VERSION "HNPBNNNYNNNNNNNNNNNNNNNNNNNNNNNNYNYYYYYYYY>4>%%%/4>'%**4YYY///"

NS_ :

BS_:

BU_: TPM TCM SCCM RF_HUB PTS ORC IC HaLF ETM ESM ESC EPS ECM Diagnost DTCM DASM CBC AFLS ADCM

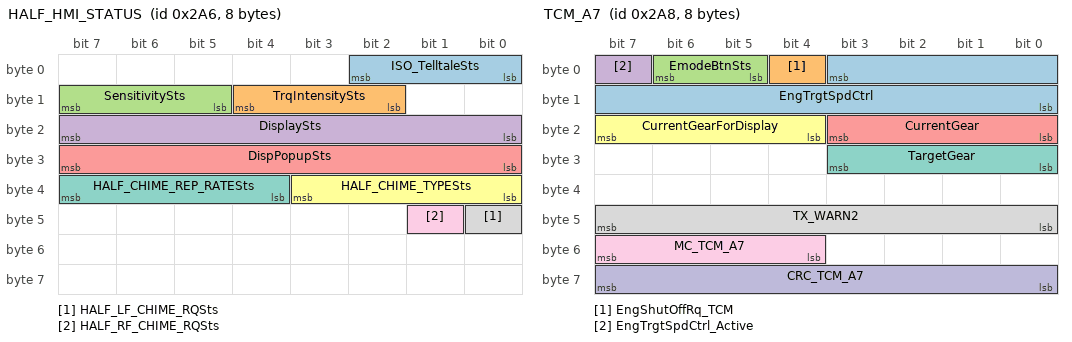
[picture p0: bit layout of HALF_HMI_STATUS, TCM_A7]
BO_ 678 HALF_HMI_STATUS: 8 HaLF
 SG_ ISO_TelltaleSts : 0|3@1+ (1,0) [0|0] ""  IC
 SG_ TrqIntensitySts : 10|3@1+ (1,0) [0|0] ""  IC
 SG_ SensitivitySts : 13|3@1+ (1,0) [0|0] ""  IC
 SG_ DisplaySts : 16|8@1+ (1,0) [0|0] ""  IC
 SG_ DispPopupSts : 24|8@1+ (1,0) [0|0] ""  IC
 SG_ HALF_CHIME_TYPESts : 32|4@1+ (1,0) [0|0] ""  CBC
 SG_ HALF_CHIME_REP_RATESts : 36|4@1+ (1,0) [0|15] ""  CBC
 SG_ HALF_LF_CHIME_RQSts : 40|1@1+ (1,0) [0|0] ""  CBC
 SG_ HALF_RF_CHIME_RQSts : 41|1@1+ (1,0) [0|0] ""  CBC

BO_ 680 TCM_A7: 8 ECM
 SG_ EngTrgtSpdCtrl : 3|12@0+ (2.5,0) [0|10235] "rpm"  ECM
 SG_ EngShutOffRq_TCM : 4|1@1+ (1,0) [0|0] ""  ECM,RF_HUB
 SG_ EmodeBtnSts : 5|2@1+ (1,0) [0|0] ""  ECM,CBC
 SG_ EngTrgtSpdCtrl_Active : 7|1@1+ (1,0) [0|0] ""  ECM
 SG_ CurrentGear : 16|4@1+ (1,0) [0|0] ""  ECM,DASM
 SG_ CurrentGearForDisplay : 20|4@1+ (1,0) [0|0] ""  ECM,IC
 SG_ TargetGear : 24|4@1+ (1,0) [0|0] ""  ECM,DASM
 SG_ TX_WARN2 : 40|8@1+ (1,0) [0|0] ""  ECM,IC
 SG_ MC_TCM_A7 : 52|4@1+ (1,0) [0|15] ""  ECM,DASM
 SG_ CRC_TCM_A7 : 56|8@1+ (1,0) [0|0] ""  ECM,DASM

BO_ 683 CBC_PT9: 8 CBC
 SG_ Pitch_Angle : 0|8@1+ (1,-90) [-90|90] "°"  IC
 SG_ Roll_Angle : 8|8@1+ (1,-90) [-90|90] "°"  IC

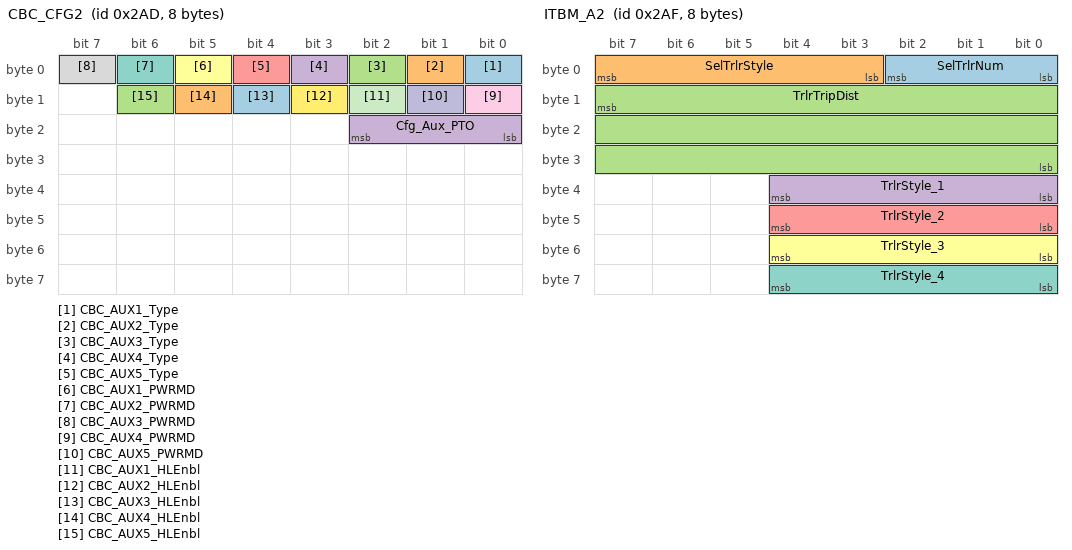
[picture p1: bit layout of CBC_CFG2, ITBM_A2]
BO_ 685 CBC_CFG2: 8 CBC
 SG_ CBC_AUX1_Type : 0|1@1+ (1,0) [0|0] ""  IC
 SG_ CBC_AUX2_Type : 1|1@1+ (1,0) [0|0] ""  IC
 SG_ CBC_AUX3_Type : 2|1@1+ (1,0) [0|0] ""  IC
 SG_ CBC_AUX4_Type : 3|1@1+ (1,0) [0|0] ""  IC
 SG_ CBC_AUX5_Type : 4|1@1+ (1,0) [0|0] ""  IC
 SG_ CBC_AUX1_PWRMD : 5|1@1+ (1,0) [0|0] ""  IC
 SG_ CBC_AUX2_PWRMD : 6|1@1+ (1,0) [0|0] ""  IC
 SG_ CBC_AUX3_PWRMD : 7|1@1+ (1,0) [0|0] ""  IC
 SG_ CBC_AUX4_PWRMD : 8|1@1+ (1,0) [0|0] ""  IC
 SG_ CBC_AUX5_PWRMD : 9|1@1+ (1,0) [0|0] ""  IC
 SG_ CBC_AUX1_HLEnbl : 10|1@1+ (1,0) [0|0] ""  IC
 SG_ CBC_AUX2_HLEnbl : 11|1@1+ (1,0) [0|0] ""  IC
 SG_ CBC_AUX3_HLEnbl : 12|1@1+ (1,0) [0|0] ""  IC
 SG_ CBC_AUX4_HLEnbl : 13|1@1+ (1,0) [0|0] ""  IC
 SG_ CBC_AUX5_HLEnbl : 14|1@1+ (1,0) [0|0] ""  IC
 SG_ Cfg_Aux_PTO : 16|3@1+ (1,0) [0|0] ""  IC

BO_ 687 ITBM_A2: 8 Vector__XXX
 SG_ SelTrlrNum : 0|3@1+ (1,0) [0|0] ""  IC,CBC
 SG_ SelTrlrStyle : 3|5@1+ (1,0) [0|0] ""  IC,CBC
 SG_ TrlrTripDist : 15|24@0+ (0.1,0) [0|1677720] "km"  IC,CBC
 SG_ TrlrStyle_1 : 32|5@1+ (1,0) [0|0] ""  IC,CBC
 SG_ TrlrStyle_2 : 40|5@1+ (1,0) [0|0] ""  IC,CBC
 SG_ TrlrStyle_3 : 48|5@1+ (1,0) [0|0] ""  IC,CBC
 SG_ TrlrStyle_4 : 56|5@1+ (1,0) [0|0] ""  IC,CBC

BO_ 688 EPPM_A1: 2 Vector__XXX
 SG_ EPPM_FAULT : 0|1@1+ (1,0) [0|0] ""  ORC,IC
 SG_ EPPM_Stat : 1|2@1+ (1,0) [0|0] ""  ORC

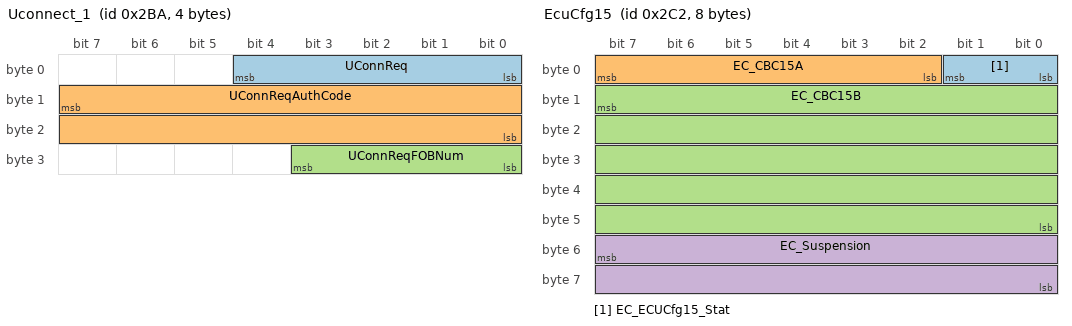
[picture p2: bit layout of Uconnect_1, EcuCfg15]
BO_ 698 Uconnect_1: 4 ETM
 SG_ UConnReq : 0|5@1+ (1,0) [0|0] ""  RF_HUB
 SG_ UConnReqAuthCode : 15|16@0+ (1,0) [0|0] ""  RF_HUB
 SG_ UConnReqFOBNum : 24|4@1+ (1,0) [0|0] ""  RF_HUB

BO_ 706 EcuCfg15: 8 CBC
 SG_ EC_ECUCfg15_Stat : 0|2@1+ (1,0) [0|0] ""  ADCM,RF_HUB
 SG_ EC_CBC15A : 2|6@1+ (1,0) [0|0] ""  RF_HUB
 SG_ EC_CBC15B : 15|40@0+ (1,0) [0|0] ""  RF_HUB
 SG_ EC_Suspension : 55|16@0+ (1,0) [0|0] ""  ADCM,RF_HUB

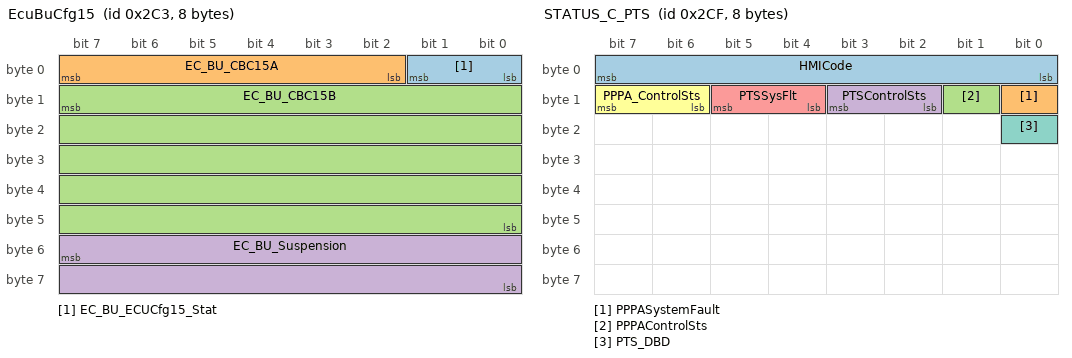
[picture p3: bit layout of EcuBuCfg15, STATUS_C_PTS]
BO_ 707 EcuBuCfg15: 8 RF_HUB
 SG_ EC_BU_ECUCfg15_Stat : 0|2@1+ (1,0) [0|0] ""  CBC
 SG_ EC_BU_CBC15A : 2|6@1+ (1,0) [0|0] ""  CBC
 SG_ EC_BU_CBC15B : 15|40@0+ (1,0) [0|0] ""  CBC
 SG_ EC_BU_Suspension : 55|16@0+ (1,0) [0|0] ""  CBC

BO_ 719 STATUS_C_PTS: 8 PTS
 SG_ HMICode : 0|8@1+ (1,0) [0|0] ""  IC
 SG_ PPPASystemFault : 8|1@1+ (1,0) [0|0] ""  IC
 SG_ PPPAControlSts : 9|1@1+ (1,0) [0|0] ""  IC
 SG_ PTSControlSts : 10|2@1+ (1,0) [0|0] ""  IC
 SG_ PTSSysFlt : 12|2@1+ (1,0) [0|0] ""  IC
 SG_ PPPA_ControlSts : 14|2@1+ (1,0) [0|0] ""  CBC
 SG_ PTS_DBD : 16|1@1+ (1,0) [0|0] ""  IC

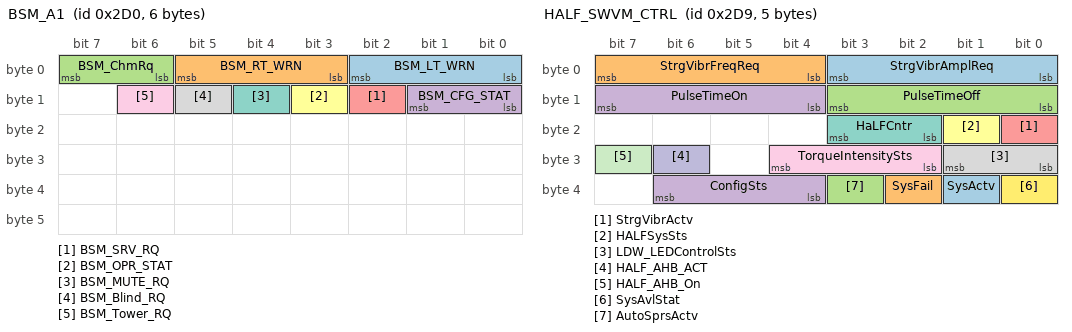
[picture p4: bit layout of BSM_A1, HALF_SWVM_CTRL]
BO_ 720 BSM_A1: 6 CBC
 SG_ BSM_LT_WRN : 0|3@1+ (1,0) [0|0] ""  IC
 SG_ BSM_RT_WRN : 3|3@1+ (1,0) [0|0] ""  IC
 SG_ BSM_ChmRq : 6|2@1+ (1,0) [0|0] ""  IC
 SG_ BSM_CFG_STAT : 8|2@1+ (1,0) [0|0] ""  IC
 SG_ BSM_SRV_RQ : 10|1@1+ (1,0) [0|0] ""  IC
 SG_ BSM_OPR_STAT : 11|1@1+ (1,0) [0|0] ""  IC
 SG_ BSM_MUTE_RQ : 12|1@1+ (1,0) [0|0] "" Vector__XXX
 SG_ BSM_Blind_RQ : 13|1@1+ (1,0) [0|0] ""  IC
 SG_ BSM_Tower_RQ : 14|1@1+ (1,0) [0|0] ""  IC

BO_ 729 HALF_SWVM_CTRL: 5 HaLF
 SG_ StrgVibrAmplReq : 0|4@1+ (0.25,0) [0|3.75] "mm"  SCCM
 SG_ StrgVibrFreqReq : 4|4@1+ (1,0) [0|15] "Hz"  SCCM
 SG_ PulseTimeOff : 8|4@1+ (0.25,0) [0|3.75] "ms"  SCCM
 SG_ PulseTimeOn : 12|4@1+ (0.25,0) [0|3.75] "ms"  SCCM
 SG_ StrgVibrActv : 16|1@1+ (1,0) [0|0] ""  SCCM
 SG_ HALFSysSts : 17|1@1+ (1,0) [0|0] ""  SCCM
 SG_ HaLFCntr : 18|2@1+ (1,0) [0|3] "decimal"  SCCM
 SG_ LDW_LEDControlSts : 24|2@1+ (1,0) [0|0] ""  CBC
 SG_ TorqueIntensitySts : 26|3@1+ (1,0) [0|0] ""  CBC
 SG_ HALF_AHB_ACT : 30|1@1+ (1,0) [0|0] ""  IC,CBC
 SG_ HALF_AHB_On : 31|1@1+ (1,0) [0|0] ""  CBC
 SG_ SysAvlStat : 32|1@1+ (1,0) [0|0] ""  IC
 SG_ SysActv : 33|1@1+ (1,0) [0|0] ""  IC
 SG_ SysFail : 34|1@1+ (1,0) [0|0] ""  IC
 SG_ AutoSprsActv : 35|1@1+ (1,0) [0|0] ""  IC
 SG_ ConfigSts : 36|3@1+ (1,0) [0|0] ""  IC,CBC

BO_ 734 RFHUB_KEY_DATA: 7 RF_HUB
 SG_ RFHM_TXFR_SEL : 0|3@1+ (1,0) [0|0] ""  CBC
 SG_ RFHM_KEY_DATA : 15|48@0+ (1,0) [0|0] ""  CBC

BO_ 735 CBC_KEY_DATA: 7 CBC
 SG_ CBC_TXFR_SEL : 0|3@1+ (1,0) [0|0] ""  RF_HUB
 SG_ CBC_KEY_DATA : 15|48@0+ (1,0) [0|0] ""  RF_HUB

BO_ 736 ESP_B1: 8 ESC
 SG_ LT_DIST : 7|16@0+ (4,0) [0|262136] "cm"  ECM,PTS,IC,CBC
 SG_ RT_DIST : 23|16@0+ (4,0) [0|262136] "cm"  ECM,PTS,IC,CBC
 SG_ YRS_DataRq : 32|1@1+ (1,0) [0|0] "" Vector__XXX
 SG_ SPCR_Warn_V2 : 33|3@1+ (1,0) [0|0] ""  DASM,IC
 SG_ HDC_SUPP : 40|1@1+ (1,0) [0|0] ""  CBC
 SG_ HDC_EN : 41|1@1+ (1,0) [0|0] ""  CBC
 SG_ TSC_SUPP : 42|1@1+ (1,0) [0|0] ""  CBC
 SG_ TSC_EN : 43|1@1+ (1,0) [0|0] ""  CBC
 SG_ ESP_PD_SUPP : 44|1@1+ (1,0) [0|0] ""  CBC
 SG_ ESP_PD_EN : 45|1@1+ (1,0) [0|0] ""  CBC
 SG_ HSA_SUPP : 46|1@1+ (1,0) [0|0] ""  IC,CBC
 SG_ HSA_EN : 47|1@1+ (1,0) [0|0] ""  IC,CBC
 SG_ ESP_DSBL : 51|1@1+ (1,0) [0|0] ""  ETM,ORC,DTCM,DASM,IC,CBC
 SG_ HILL_DES_STAT : 52|2@1+ (1,0) [0|0] ""  TCM,ECM,DASM,IC,CBC
 SG_ ESP_Off_IndLmp_On_Rq : 54|1@1+ (1,0) [0|0] ""  ETM,ORC,DTCM,IC,CBC
 SG_ ESP_TRK_MD : 55|1@1+ (1,0) [0|0] ""  ORC,IC,CBC
 SG_ ESC_CtrlLmp_Info : 56|2@1+ (1,0) [0|0] ""  ETM,ORC,DTCM,DASM,PTS,IC
 SG_ ABS_IndLmp_On_Rq : 58|2@1+ (1,0) [0|0] ""  ETM,ECM,IC
 SG_ BrkIndLmp_On_Rq_ESC : 60|2@1+ (1,0) [0|0] ""  ETM,IC
 SG_ SelSpdLmp : 62|2@1+ (1,0) [0|0] ""  IC,CBC

BO_ 737 ESP_B2: 8 ESC
 SG_ VehPerfAccel_X : 1|10@0+ (0.08,-40.88) [-40.88|40.88] "m/s²"  IC,CBC
 SG_ ESC_LnchMd : 3|2@1+ (1,0) [0|0] ""  ORC,ECM,IC,CBC
 SG_ ESC_LnchMdAbrt : 5|1@1+ (1,0) [0|0] ""  ECM,IC
 SG_ VehPerfAccel_Y : 17|10@0+ (0.08,-40.88) [-40.88|40.88] "m/s²"  IC,CBC
 SG_ LaunchRPMsetting_ESC : 19|5@1+ (250,1000) [1000|7000] "rpm"  CBC
 SG_ ESC_LnchMdCnd1 : 32|1@1+ (1,0) [0|0] ""  ECM,IC
 SG_ ESC_LnchMdCnd2 : 33|1@1+ (1,0) [0|0] ""  ECM,IC
 SG_ ESC_LnchMdCnd3 : 34|1@1+ (1,0) [0|0] ""  ECM,IC
 SG_ ESC_LnchMdCnd4 : 35|1@1+ (1,0) [0|0] ""  ECM,IC
 SG_ ESC_LnchMdCnd5 : 36|1@1+ (1,0) [0|0] ""  ECM,IC
 SG_ ESC_LnchMdCnd6 : 37|1@1+ (1,0) [0|0] ""  ECM,IC
 SG_ BrkWearInd : 38|2@1+ (1,0) [0|0] ""  IC
 SG_ ESC_sftbtn_launch_sel : 40|1@1+ (1,0) [0|0] ""  CBC
 SG_ ICS_ESC_OFF_LED_hrdbtn_cnrtl : 41|2@1+ (1,0) [0|0] ""  CBC
 SG_ ESC_OFF_Hrd_Sft_Button_sts : 43|3@1+ (1,0) [0|0] ""  CBC
 SG_ ESC_LnchAbrtSts : 46|2@1+ (1,0) [0|0] ""  ECM,IC
 SG_ ICS_Launch_HrdBtn_LED_cnrtl : 51|2@1+ (1,0) [0|0] ""  CBC
 SG_ ESC_LnchMode : 53|3@1+ (1,0) [0|0] ""  ECM

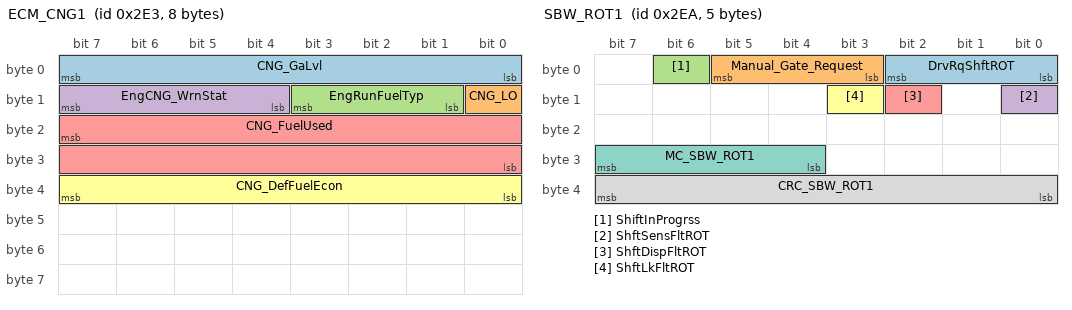
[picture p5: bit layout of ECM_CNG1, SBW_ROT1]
BO_ 739 ECM_CNG1: 8 ECM
 SG_ CNG_GaLvl : 0|8@1+ (1,0) [0|100] "%"  IC
 SG_ CNG_LO : 8|1@1+ (1,0) [0|0] ""  IC
 SG_ EngRunFuelTyp : 9|3@1+ (1,0) [0|0] ""  IC,CBC
 SG_ EngCNG_WrnStat : 12|4@1+ (1,0) [0|0] ""  IC
 SG_ CNG_FuelUsed : 23|16@0+ (0.21668,0) [0|14200] "µl/100ms"  IC
 SG_ CNG_DefFuelEcon : 32|8@1+ (0.2,0) [0|50] "kmpl"  IC

BO_ 746 SBW_ROT1: 5 ESM
 SG_ DrvRqShftROT : 0|3@1+ (1,0) [0|0] ""  TCM,RF_HUB
 SG_ Manual_Gate_Request : 3|3@1+ (1,0) [0|0] ""  TCM
 SG_ ShiftInProgrss : 6|1@1+ (1,0) [0|0] ""  TCM,IC
 SG_ ShftSensFltROT : 8|1@1+ (1,0) [0|0] ""  TCM
 SG_ ShftDispFltROT : 10|1@1+ (1,0) [0|0] ""  TCM
 SG_ ShftLkFltROT : 11|1@1+ (1,0) [0|0] ""  TCM
 SG_ MC_SBW_ROT1 : 28|4@1+ (1,0) [0|15] ""  TCM
 SG_ CRC_SBW_ROT1 : 32|8@1+ (1,0) [0|0] ""  TCM

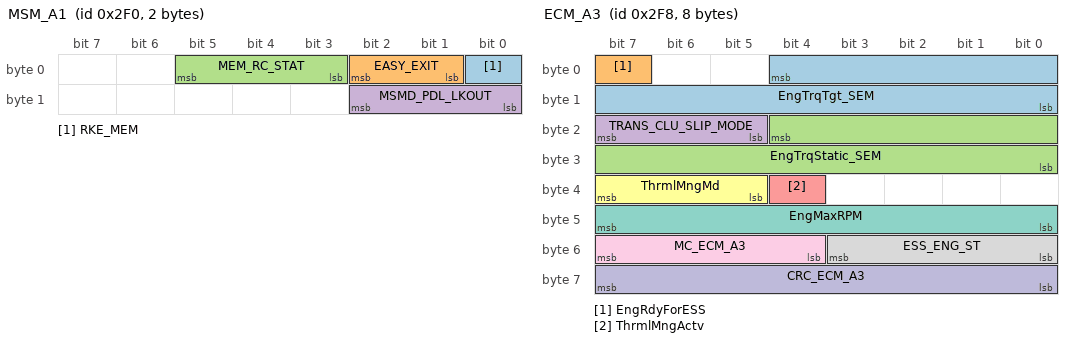
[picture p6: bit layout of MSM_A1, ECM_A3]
BO_ 752 MSM_A1: 2 CBC
 SG_ RKE_MEM : 0|1@1+ (1,0) [0|0] ""  IC
 SG_ EASY_EXIT : 1|2@1+ (1,0) [0|0] ""  IC
 SG_ MEM_RC_STAT : 3|3@1+ (1,0) [0|0] ""  IC
 SG_ MSMD_PDL_LKOUT : 8|3@1+ (1,0) [0|0] ""  IC

BO_ 760 ECM_A3: 8 ECM
 SG_ EngTrqTgt_SEM : 4|13@0+ (0.25,-500) [-500|1547.5] "Nm"  TCM
 SG_ EngRdyForESS : 7|1@1+ (1,0) [0|0] ""  TCM
 SG_ EngTrqStatic_SEM : 20|13@0+ (0.25,-500) [-500|1547.5] "Nm"  TCM
 SG_ TRANS_CLU_SLIP_MODE : 21|3@1+ (1,0) [0|0] ""  TCM
 SG_ ThrmlMngActv : 36|1@1+ (1,0) [0|0] ""  TCM
 SG_ ThrmlMngMd : 37|3@1+ (1,0) [0|0] ""  CBC
 SG_ EngMaxRPM : 40|8@1+ (50,0) [0|12700] "rpm"  TCM
 SG_ ESS_ENG_ST : 48|4@1+ (1,0) [0|0] ""  ORC,DTCM,TCM,ESC,EPS,AFLS,CBC
 SG_ MC_ECM_A3 : 52|4@1+ (1,0) [0|15] ""  TCM,CBC
 SG_ CRC_ECM_A3 : 56|8@1+ (1,0) [0|0] ""  TCM

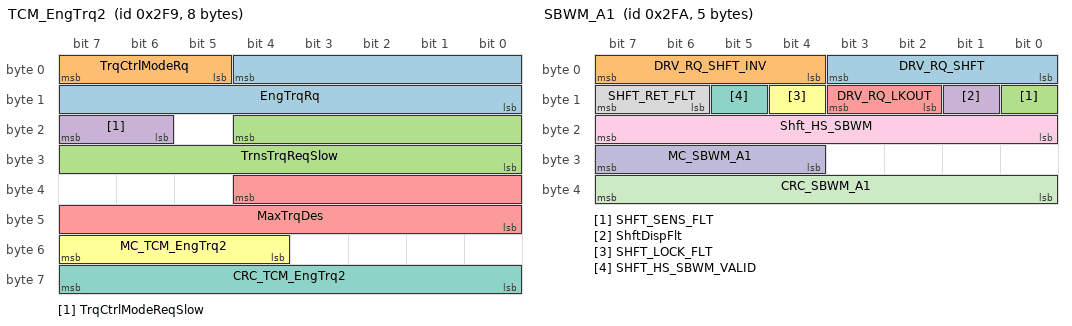
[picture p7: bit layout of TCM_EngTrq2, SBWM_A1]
BO_ 761 TCM_EngTrq2: 8 TCM
 SG_ EngTrqRq : 4|13@0+ (0.25,-500) [-500|1547.5] "Nm"  ECM
 SG_ TrqCtrlModeRq : 5|3@1+ (1,0) [0|0] ""  ECM
 SG_ TrnsTrqReqSlow : 20|13@0+ (0.25,-500) [-500|1547.5] "Nm"  ECM
 SG_ TrqCtrlModeReqSlow : 22|2@1+ (1,0) [0|0] ""  ECM
 SG_ MaxTrqDes : 36|13@0+ (0.25,-500) [-500|1547.5] "Nm"  ECM
 SG_ MC_TCM_EngTrq2 : 52|4@1+ (1,0) [0|15] ""  ECM
 SG_ CRC_TCM_EngTrq2 : 56|8@1+ (1,0) [0|0] ""  ECM

BO_ 762 SBWM_A1: 5 Vector__XXX
 SG_ DRV_RQ_SHFT : 0|4@1+ (1,0) [0|0] ""  TCM
 SG_ DRV_RQ_SHFT_INV : 4|4@1+ (1,0) [0|0] ""  TCM
 SG_ SHFT_SENS_FLT : 8|1@1+ (1,0) [0|0] ""  TCM
 SG_ ShftDispFlt : 9|1@1+ (1,0) [0|0] ""  TCM
 SG_ DRV_RQ_LKOUT : 10|2@1+ (1,0) [0|0] ""  TCM
 SG_ SHFT_LOCK_FLT : 12|1@1+ (1,0) [0|0] ""  TCM
 SG_ SHFT_HS_SBWM_VALID : 13|1@1+ (1,0) [0|0] ""  TCM
 SG_ SHFT_RET_FLT : 14|2@1+ (1,0) [0|0] ""  TCM
 SG_ Shft_HS_SBWM : 16|8@1+ (1,0) [0|0] ""  TCM
 SG_ MC_SBWM_A1 : 28|4@1+ (1,0) [0|15] ""  TCM
 SG_ CRC_SBWM_A1 : 32|8@1+ (1,0) [0|0] ""  TCM

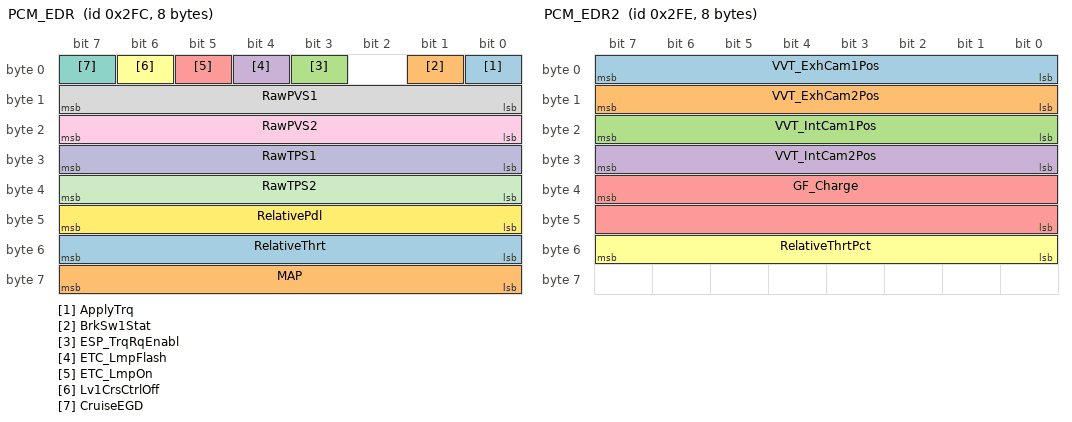
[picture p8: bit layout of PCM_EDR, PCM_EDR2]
BO_ 764 PCM_EDR: 8 ECM
 SG_ ApplyTrq : 0|1@1+ (1,0) [0|0] ""  ORC
 SG_ BrkSw1Stat : 1|1@1+ (1,0) [0|0] "" Vector__XXX
 SG_ ESP_TrqRqEnabl : 3|1@1+ (1,0) [0|0] ""  ORC
 SG_ ETC_LmpFlash : 4|1@1+ (1,0) [0|0] ""  ORC
 SG_ ETC_LmpOn : 5|1@1+ (1,0) [0|0] ""  ORC
 SG_ Lv1CrsCtrlOff : 6|1@1+ (1,0) [0|0] ""  ORC
 SG_ CruiseEGD : 7|1@1+ (1,0) [0|0] ""  ORC
 SG_ RawPVS1 : 8|8@1+ (0.019607843,0) [0|4.98] "Volts"  ORC
 SG_ RawPVS2 : 16|8@1+ (0.019607843,0) [0|4.98] "Volts"  ORC
 SG_ RawTPS1 : 24|8@1+ (0.019607843,0) [0|4.98] "Volts"  ORC
 SG_ RawTPS2 : 32|8@1+ (0.019607843,0) [0|4.98] "Volts"  ORC
 SG_ RelativePdl : 40|8@1+ (0.019607843,0) [0|4.98] "Volts"  ORC
 SG_ RelativeThrt : 48|8@1+ (0.019607843,0) [0|4.98] "Volts"  ORC
 SG_ MAP : 56|8@1+ (0.8,0) [0|203.2] "kPa"  ORC,ESC

BO_ 766 PCM_EDR2: 8 ECM
 SG_ VVT_ExhCam1Pos : 0|8@1+ (1,0) [1|254] "Degrees"  ORC
 SG_ VVT_ExhCam2Pos : 8|8@1+ (1,0) [1|254] "Degrees"  ORC
 SG_ VVT_IntCam1Pos : 16|8@1+ (1,0) [1|254] "Degrees"  ORC
 SG_ VVT_IntCam2Pos : 24|8@1+ (1,0) [1|254] "Degrees"  ORC
 SG_ GF_Charge : 39|16@0+ (0.2,0) [0|13106.8] "mg/cycle/cyl"  ORC
 SG_ RelativeThrtPct : 48|8@1+ (0.4,0) [0|100] "%"  ORC

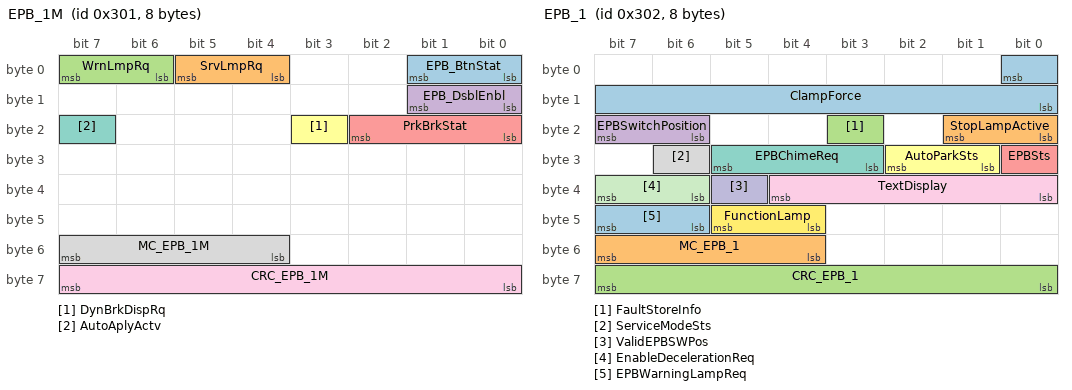
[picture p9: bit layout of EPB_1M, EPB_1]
BO_ 769 EPB_1M: 8 Vector__XXX
 SG_ EPB_BtnStat : 0|2@1+ (1,0) [0|0] ""  ECM,ESC
 SG_ SrvLmpRq : 4|2@1+ (1,0) [0|0] ""  CBC
 SG_ WrnLmpRq : 6|2@1+ (1,0) [0|0] ""  ORC,CBC
 SG_ EPB_DsblEnbl : 8|2@1+ (1,0) [0|0] ""  TCM,RF_HUB
 SG_ PrkBrkStat : 16|3@1+ (1,0) [0|0] ""  ORC,TCM,ECM,ESC,CBC,RF_HUB
 SG_ DynBrkDispRq : 19|1@1+ (1,0) [0|0] ""  TCM,ESC,CBC
 SG_ AutoAplyActv : 23|1@1+ (1,0) [0|0] ""  CBC
 SG_ MC_EPB_1M : 52|4@1+ (1,0) [0|15] ""  ESC
 SG_ CRC_EPB_1M : 56|8@1+ (1,0) [0|0] ""  ESC

BO_ 770 EPB_1: 8 Vector__XXX
 SG_ ClampForce : 0|9@0+ (0.1,0) [0|51.1] "Kn"  ORC,DASM,ESC,EPS,IC,CBC
 SG_ StopLampActive : 16|2@1+ (1,0) [0|0] ""  DASM,ESC,EPS,IC,CBC
 SG_ FaultStoreInfo : 19|1@1+ (1,0) [0|0] ""  DASM,ESC,EPS,IC,CBC
 SG_ EPBSwitchPosition : 22|2@1+ (1,0) [0|0] ""  ORC,DASM,ESC,EPS,IC,CBC
 SG_ EPBSts : 24|1@1+ (1,0) [0|0] ""  ORC,DASM,ESC,EPS,IC,CBC
 SG_ AutoParkSts : 25|2@1+ (1,0) [0|0] ""  DASM,ESC,EPS,IC,CBC
 SG_ EPBChimeReq : 27|3@1+ (1,0) [0|0] ""  DASM,ESC,EPS,IC,CBC
 SG_ ServiceModeSts : 30|1@1+ (1,0) [0|0] ""  DASM,ESC,EPS,IC,CBC
 SG_ TextDisplay : 32|5@1+ (1,0) [0|0] ""  DASM,ESC,EPS,IC,CBC
 SG_ ValidEPBSWPos : 37|1@1+ (1,0) [0|0] ""  DASM,ESC,EPS,IC,CBC
 SG_ EnableDecelerationReq : 38|2@1+ (1,0) [0|0] ""  DASM,ESC,EPS,IC,CBC
 SG_ FunctionLamp : 44|2@1+ (1,0) [0|0] ""  DASM,ESC,EPS,IC,CBC
 SG_ EPBWarningLampReq : 46|2@1+ (1,0) [0|0] ""  ORC,DASM,ESC,EPS,IC,CBC
 SG_ MC_EPB_1 : 52|4@1+ (1,0) [0|15] ""  DASM,ESC,EPS,IC,CBC
 SG_ CRC_EPB_1 : 56|8@1+ (1,0) [0|0] ""  DASM,ESC,EPS,IC,CBC

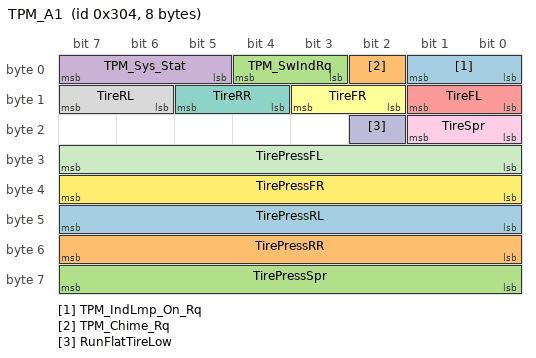
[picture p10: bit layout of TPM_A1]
BO_ 772 TPM_A1: 8 TPM
 SG_ TPM_IndLmp_On_Rq : 0|2@1+ (1,0) [0|0] ""  ETM,ORC,IC
 SG_ TPM_Chime_Rq : 2|1@1+ (1,0) [0|0] ""  ORC,IC
 SG_ TPM_SwIndRq : 3|2@1+ (1,0) [0|0] ""  ORC,IC,CBC
 SG_ TPM_Sys_Stat : 5|3@1+ (1,0) [0|0] ""  ORC,IC
 SG_ TireFL : 8|2@1+ (1,0) [0|0] ""  ETM,ORC,IC
 SG_ TireFR : 10|2@1+ (1,0) [0|0] ""  ETM,ORC,IC
 SG_ TireRR : 12|2@1+ (1,0) [0|0] ""  ETM,ORC,IC
 SG_ TireRL : 14|2@1+ (1,0) [0|0] ""  ETM,ORC,IC
 SG_ TireSpr : 16|2@1+ (1,0) [0|0] ""  ORC,IC
 SG_ RunFlatTireLow : 18|1@1+ (1,0) [0|0] ""  ORC,IC
 SG_ TirePressFL : 24|8@1+ (1,0) [0|126] "psi"  ETM,ORC,IC
 SG_ TirePressFR : 32|8@1+ (1,0) [0|126] "psi"  ETM,ORC,IC
 SG_ TirePressRL : 40|8@1+ (1,0) [0|126] "psi"  ETM,ORC,IC
 SG_ TirePressRR : 48|8@1+ (1,0) [0|126] "psi"  ETM,ORC,IC
 SG_ TirePressSpr : 56|8@1+ (1,0) [0|126] "psi"  ORC,IC

CM_ SG_ 678 ISO_TelltaleSts "LDW telltale status in cluster";
CM_ SG_ 678 TrqIntensitySts "LDW torque intesity level for display in cluster";
CM_ SG_ 678 SensitivitySts "LDW sensitivity level for display in cluster";
CM_ SG_ 678 DisplaySts "LDW display status in cluster";
CM_ SG_ 678 DispPopupSts "LDW message status in cluster";
CM_ SG_ 678 HALF_CHIME_TYPESts "LDW chime type";
CM_ SG_ 678 HALF_CHIME_REP_RATESts "LDW chime repetition rate";
CM_ SG_ 678 HALF_LF_CHIME_RQSts "LDW chime request for left side; true = [1]";
CM_ SG_ 678 HALF_RF_CHIME_RQSts "LDW chime request for right side; true = [1]";
CM_ SG_ 680 EngTrgtSpdCtrl "Engine target speed control";
CM_ SG_ 680 EngShutOffRq_TCM "TCM request engine shut off";
CM_ SG_ 680 EmodeBtnSts "Emode button LED status";
CM_ SG_ 680 EngTrgtSpdCtrl_Active "Engine target speed control active";
CM_ SG_ 680 CurrentGear "Current Gear";
CM_ SG_ 680 CurrentGearForDisplay "Current Gear for display";
CM_ SG_ 680 TargetGear "Target Gear - protected";
CM_ SG_ 680 TX_WARN2 "Transmission warning #2";
CM_ SG_ 680 MC_TCM_A7 "Message counter";
CM_ SG_ 680 CRC_TCM_A7 "CRC-checksum byte 1 to 7 according to SAE J1850";
CM_ SG_ 683 Pitch_Angle "Pitch angle; Disable = [FE]";
CM_ SG_ 683 Roll_Angle "Roll angle";
CM_ SG_ 685 CBC_AUX1_Type "Aux switch 1 behavior; Latching = [0], Momentary = [1]";
CM_ SG_ 685 CBC_AUX2_Type "Aux switch 2 behavior; Latching = [0], Momentary = [1]";
CM_ SG_ 685 CBC_AUX3_Type "Aux switch 3 behavior; Latching = [0], Momentary = [1]";
CM_ SG_ 685 CBC_AUX4_Type "Aux switch 4 behavior; Latching = [0], Momentary = [1]";
CM_ SG_ 685 CBC_AUX5_Type "Aux switch 5 behavior; Latching = [0], Momentary = [1]";
CM_ SG_ 685 CBC_AUX1_PWRMD "Aux switch 1 power mode; ignition = [0], battery = [1]";
CM_ SG_ 685 CBC_AUX2_PWRMD "Aux switch 2 power mode; ignition = [0], battery = [1]";
CM_ SG_ 685 CBC_AUX3_PWRMD "Aux switch 3 power mode; ignition = [0], battery = [1]";
CM_ SG_ 685 CBC_AUX4_PWRMD "Aux switch 4 power mode; ignition = [0], battery = [1]";
CM_ SG_ 685 CBC_AUX5_PWRMD "Aux switch 5 power mode; ignition = [0], battery = [1]";
CM_ SG_ 685 CBC_AUX1_HLEnbl "Aux switch 1 enable holding last state; enabled = [1]";
CM_ SG_ 685 CBC_AUX2_HLEnbl "Aux switch 2 enable holding last state; enabled = [1]";
CM_ SG_ 685 CBC_AUX3_HLEnbl "Aux switch 3 enable holding last state; enabled = [1]";
CM_ SG_ 685 CBC_AUX4_HLEnbl "Aux switch 4 enable holding last state; enabled = [1]";
CM_ SG_ 685 CBC_AUX5_HLEnbl "Aux switch 5 enable holding last state; enabled = [1]";
CM_ SG_ 685 Cfg_Aux_PTO "AUX Switches Configuration";
CM_ SG_ 687 SelTrlrNum "Selected trailer number";
CM_ SG_ 687 SelTrlrStyle "Selected trailer style";
CM_ SG_ 687 TrlrTripDist "Trip distance of the curent Trailer";
CM_ SG_ 687 TrlrStyle_1 "Trailer 1 style";
CM_ SG_ 687 TrlrStyle_2 "Trailer 2 style";
CM_ SG_ 687 TrlrStyle_3 "Trailer 3 style";
CM_ SG_ 687 TrlrStyle_4 "Trailer 4 style";
CM_ SG_ 688 EPPM_FAULT "Pedestrian protection module fault; True = [1]";
CM_ SG_ 688 EPPM_Stat "Pedestrian protection module status";
CM_ SG_ 698 UConnReq "Basic Uconnect request";
CM_ SG_ 698 UConnReqAuthCode "Authorization for requests";
CM_ SG_ 698 UConnReqFOBNum "FOB number making the request";
CM_ SG_ 706 EC_ECUCfg15_Stat "ECU Configuration messages status 15";
CM_ SG_ 706 EC_CBC15A "CBC ecu configuration 15A";
CM_ SG_ 706 EC_CBC15B "CBC ecu configuration 15B";
CM_ SG_ 706 EC_Suspension "Suspension ecu configuration";
CM_ SG_ 707 EC_BU_ECUCfg15_Stat "Backup for ECU Configuration messages status 15";
CM_ SG_ 707 EC_BU_CBC15A "Backup for CBC ecu configuration 15A";
CM_ SG_ 707 EC_BU_CBC15B "Backup for CBC ecu configuration 15B";
CM_ SG_ 707 EC_BU_Suspension "Backup for Suspension ecu configuration";
CM_ SG_ 719 HMICode "HMI codes to be displayed";
CM_ SG_ 719 PPPASystemFault "Indicates the fail status of PPPA; true = [1]";
CM_ SG_ 719 PPPAControlSts "Indicates the active state of PPPA; active = [1]";
CM_ SG_ 719 PTSControlSts "Indicates the active state of the PTS";
CM_ SG_ 719 PTSSysFlt "Indicates the fail status of the PTS";
CM_ SG_ 719 PPPA_ControlSts "Parallel & perpendicular park assist switch status";
CM_ SG_ 719 PTS_DBD "Park assist system disabled; System_Disabled = [1]";
CM_ SG_ 720 BSM_LT_WRN "Blind spot detection left side warning";
CM_ SG_ 720 BSM_RT_WRN "Blind spot detection Right side warning";
CM_ SG_ 720 BSM_ChmRq "Blind spot chime request";
CM_ SG_ 720 BSM_CFG_STAT "BSM configuration status";
CM_ SG_ 720 BSM_SRV_RQ "BSM service warning request; 1= service request";
CM_ SG_ 720 BSM_OPR_STAT "BSM operation status; 1= operational failure";
CM_ SG_ 720 BSM_MUTE_RQ "Audio system mute request from BSM";
CM_ SG_ 720 BSM_Blind_RQ "Sensor blinded request from BSM; 1= sensor blocked request";
CM_ SG_ 720 BSM_Tower_RQ "BSM unavailable in the astronomy tower zone; 1= tower zone request";
CM_ SG_ 729 StrgVibrAmplReq "Steering vibration amplitude request";
CM_ SG_ 729 StrgVibrFreqReq "Steering vibration frequency request";
CM_ SG_ 729 PulseTimeOff "Pulse time off";
CM_ SG_ 729 PulseTimeOn "Pulse time on";
CM_ SG_ 729 StrgVibrActv "Steering vibration active; true = [1]";
CM_ SG_ 729 HALFSysSts "Half system status; fault = [1]";
CM_ SG_ 729 HaLFCntr "HaLF message counter";
CM_ SG_ 729 LDW_LEDControlSts "LDW switch LED status";
CM_ SG_ 729 TorqueIntensitySts "LDW Torque Intesity Level";
CM_ SG_ 729 HALF_AHB_ACT "Auto high beam is active (indicates that all enabling conditions are met)";
CM_ SG_ 729 HALF_AHB_On "Auto high beam on request from the HALF ECU";
CM_ SG_ 729 SysAvlStat "System availability status; available = [1]";
CM_ SG_ 729 SysActv "System active";
CM_ SG_ 729 SysFail "System fault";
CM_ SG_ 729 AutoSprsActv "Automatic suppression active";
CM_ SG_ 729 ConfigSts "LDW sensitivity level";
CM_ SG_ 734 RFHM_TXFR_SEL "RFHM transfer select (defines the key data)";
CM_ SG_ 734 RFHM_KEY_DATA "RFHM key data";
CM_ SG_ 735 CBC_TXFR_SEL "CBC transfer select (defines the key data)";
CM_ SG_ 735 CBC_KEY_DATA "CBC key data";
CM_ SG_ 736 LT_DIST "Distance Traveled by Left Wheel";
CM_ SG_ 736 RT_DIST "Distance Traveled by Right Wheel";
CM_ SG_ 736 YRS_DataRq "Request from ESC for YRS information";
CM_ SG_ 736 SPCR_Warn_V2 "Stop coordinator warning if driver exits vehicle";
CM_ SG_ 736 HDC_SUPP "Hill Descent Control supported (1=supported)";
CM_ SG_ 736 HDC_EN "Hill Descent Control enabled (1=enabled)";
CM_ SG_ 736 TSC_SUPP "Trailer Sway Control supported (1=supported)";
CM_ SG_ 736 TSC_EN "Trailer Sway Control enabled (1=enabled)";
CM_ SG_ 736 ESP_PD_SUPP "ESP Permanent Disable supported (1=supported)";
CM_ SG_ 736 ESP_PD_EN "ESP Permanent Disable enabled (1=enabled)";
CM_ SG_ 736 HSA_SUPP "Hill Start Assist supported (1=supported)";
CM_ SG_ 736 HSA_EN "Hill Start Assist enabled (1=enabled)";
CM_ SG_ 736 ESP_DSBL "ESP feature is completely disabled = [1]";
CM_ SG_ 736 HILL_DES_STAT "Hill descent feature status";
CM_ SG_ 736 ESP_Off_IndLmp_On_Rq "ESP-OFF indication lamp on request";
CM_ SG_ 736 ESP_TRK_MD "ESP Track Mode indication";
CM_ SG_ 736 ESC_CtrlLmp_Info "ESC control lamp information";
CM_ SG_ 736 ABS_IndLmp_On_Rq "ABS indication lamp on request";
CM_ SG_ 736 BrkIndLmp_On_Rq_ESC "Brake indication lamp (red) on request";
CM_ SG_ 736 SelSpdLmp "Select speed lamp status";
CM_ SG_ 737 VehPerfAccel_X "Vehicle longitudinal acceleration (+ means forward)";
CM_ SG_ 737 ESC_LnchMd "ESC launch mode";
CM_ SG_ 737 ESC_LnchMdAbrt "Indication of aborted Launch (1=aborted)";
CM_ SG_ 737 VehPerfAccel_Y "Vehicle lateral acceleration (+ means left, specific to center of gravity)";
CM_ SG_ 737 LaunchRPMsetting_ESC "Launch RPM setting";
CM_ SG_ 737 ESC_LnchMdCnd1 "Vehicle stopped for Launch (1=stopped for launch)";
CM_ SG_ 737 ESC_LnchMdCnd2 "Vehicle on level ground for Launch (1=level for launch)";
CM_ SG_ 737 ESC_LnchMdCnd3 "Steering wheel straight for Launch (1=straight for launch)";
CM_ SG_ 737 ESC_LnchMdCnd4 "Accelerator depressed for Launch (1=accelerator depressed for launch)";
CM_ SG_ 737 ESC_LnchMdCnd5 "Vehicle not in Reverse (1=not in reverse for launch)";
CM_ SG_ 737 ESC_LnchMdCnd6 "Engine Running (1=running)";
CM_ SG_ 737 BrkWearInd "Brake pad wear indication";
CM_ SG_ 737 ESC_sftbtn_launch_sel "Soft button launch selected; Launch selected = [1]";
CM_ SG_ 737 ICS_ESC_OFF_LED_hrdbtn_cnrtl "Button 4 control status";
CM_ SG_ 737 ESC_OFF_Hrd_Sft_Button_sts "ESC hard button status";
CM_ SG_ 737 ESC_LnchAbrtSts "ESC launch mode abort status";
CM_ SG_ 737 ICS_Launch_HrdBtn_LED_cnrtl "Launch LED control status";
CM_ SG_ 737 ESC_LnchMode "ESC launch mode - signal # 2";
CM_ SG_ 739 CNG_GaLvl "CNG gauge level";
CM_ SG_ 739 CNG_LO "CNG is low";
CM_ SG_ 739 EngRunFuelTyp "Engine running fuel type";
CM_ SG_ 739 EngCNG_WrnStat "Engine CNG warning status";
CM_ SG_ 739 CNG_FuelUsed "CNG fuel used per 100 ms";
CM_ SG_ 739 CNG_DefFuelEcon "CNG default fuel economy";
CM_ SG_ 746 DrvRqShftROT "Driver requested gear shift position";
CM_ SG_ 746 Manual_Gate_Request "Manual gate request";
CM_ SG_ 746 ShiftInProgrss "Shift lever shift in progress, 1=Active";
CM_ SG_ 746 ShftSensFltROT "Shift sensor single fault - rotary shifter, 1=fault";
CM_ SG_ 746 ShftDispFltROT "Gear shifter display/trigger fault status - rotary shifter, 1=fault";
CM_ SG_ 746 ShftLkFltROT "Shift lock fault - rotary shifter, 1=fault";
CM_ SG_ 746 MC_SBW_ROT1 "Message counter";
CM_ SG_ 746 CRC_SBW_ROT1 "CRC-checksum byte 1 to 4 according to SAE J1850";
CM_ SG_ 752 RKE_MEM "Remote linked to memory; [0] = NO, [1] = YES";
CM_ SG_ 752 EASY_EXIT "Easy exit seat state";
CM_ SG_ 752 MEM_RC_STAT "Memory recall status";
CM_ SG_ 752 MSMD_PDL_LKOUT "Adjustable pedal lockout";
CM_ SG_ 760 EngTrqTgt_SEM "Target Torque  - trans trq. request";
CM_ SG_ 760 EngRdyForESS "Engine is ready for ESS action (1 = ready)";
CM_ SG_ 760 EngTrqStatic_SEM "Static engine torque - trans trq request";
CM_ SG_ 760 TRANS_CLU_SLIP_MODE "Clutch Slip Request Mode";
CM_ SG_ 760 ThrmlMngActv "Thermal management active (extra flag)";
CM_ SG_ 760 ThrmlMngMd "Thermal management mode";
CM_ SG_ 760 EngMaxRPM "Engine maximum RPM";
CM_ SG_ 760 ESS_ENG_ST "ESS Engine State";
CM_ SG_ 760 MC_ECM_A3 "Message counter";
CM_ SG_ 760 CRC_ECM_A3 "CRC-checksum byte 1 to 7 according to SAE J1850";
CM_ SG_ 761 EngTrqRq "Requested engine torque";
CM_ SG_ 761 TrqCtrlModeRq "Torque control mode request";
CM_ SG_ 761 TrnsTrqReqSlow "Slow path desired engine torque request from the trans";
CM_ SG_ 761 TrqCtrlModeReqSlow "Slow path torque control mode request";
CM_ SG_ 761 MaxTrqDes "Maximum engine torque desired";
CM_ SG_ 761 MC_TCM_EngTrq2 "Message counter";
CM_ SG_ 761 CRC_TCM_EngTrq2 "CRC-checksum byte 1 to 7 according to SAE J1850";
CM_ SG_ 762 DRV_RQ_SHFT "Driver requested gear shift position";
CM_ SG_ 762 DRV_RQ_SHFT_INV "Driver requested gear shift position inverse";
CM_ SG_ 762 SHFT_SENS_FLT "Shift sensor single fault, 1=fault";
CM_ SG_ 762 ShftDispFlt "Gear shifter display/trigger fault status, 1=fault";
CM_ SG_ 762 DRV_RQ_LKOUT "Driver requested shifter lockout release switch";
CM_ SG_ 762 SHFT_LOCK_FLT "Shift lock fault, 1=fault";
CM_ SG_ 762 SHFT_HS_SBWM_VALID "Handshake testparameter valid (SBWM to TCU), 1=valid";
CM_ SG_ 762 SHFT_RET_FLT "Gear shifter return sensor fault status";
CM_ SG_ 762 Shft_HS_SBWM "Handshake testparameter (SBWM to TCU)";
CM_ SG_ 762 MC_SBWM_A1 "Message counter";
CM_ SG_ 762 CRC_SBWM_A1 "CRC-checksum byte 1 to 4 according to SAE J1850";
CM_ SG_ 764 ApplyTrq "EDR ONLY - Torque may be applied to the wheels";
CM_ SG_ 764 BrkSw1Stat "EDR ONLY - Brake switch1 status, off = [0]";
CM_ SG_ 764 ESP_TrqRqEnabl "EDR ONLY - ESP torque requests are allowed = [1]";
CM_ SG_ 764 ETC_LmpFlash "EDR ONLY - ETC lamp is flashing";
CM_ SG_ 764 ETC_LmpOn "EDR ONLY - ETC lamp is on";
CM_ SG_ 764 Lv1CrsCtrlOff "EDR ONLY - Level is requested cruise off";
CM_ SG_ 764 CruiseEGD "EDR ONLY - Cruise system is engaged";
CM_ SG_ 764 RawPVS1 "EDR ONLY - Raw pedal value sensor #1";
CM_ SG_ 764 RawPVS2 "EDR ONLY - Raw pedal value sensor #2";
CM_ SG_ 764 RawTPS1 "EDR ONLY - Raw throttle position sensor #1";
CM_ SG_ 764 RawTPS2 "EDR ONLY - Raw throttle position sensor #2";
CM_ SG_ 764 RelativePdl "EDR ONLY - Relative pedal value";
CM_ SG_ 764 RelativeThrt "EDR ONLY - Relative throttle value";
CM_ SG_ 764 MAP "EDR ONLY - Intake manifold pressure";
CM_ SG_ 766 VVT_ExhCam1Pos "EDR ONLY - Centerline position for exhaust cam on bank 1";
CM_ SG_ 766 VVT_ExhCam2Pos "EDR ONLY - Centerline position for exhaust cam on bank 2";
CM_ SG_ 766 VVT_IntCam1Pos "EDR ONLY - Centerline position for intake cam on bank 1";
CM_ SG_ 766 VVT_IntCam2Pos "EDR ONLY - Centerline position for intake cam on bank 2";
CM_ SG_ 766 GF_Charge "EDR ONLY - Port flow per cylinder per stroke";
CM_ SG_ 766 RelativeThrtPct "EDR ONLY - Relative throttle percent";
CM_ SG_ 769 EPB_BtnStat "Electric parking brake button status";
CM_ SG_ 769 SrvLmpRq "Service lamp request";
CM_ SG_ 769 WrnLmpRq "Warning lamp request";
CM_ SG_ 769 EPB_DsblEnbl "EPB display enable";
CM_ SG_ 769 PrkBrkStat "Parking brake status";
CM_ SG_ 769 DynBrkDispRq "Dynamic braking display request; True = [1]";
CM_ SG_ 769 AutoAplyActv "Automatic apply is active; True = [1]";
CM_ SG_ 769 MC_EPB_1M "Message counter";
CM_ SG_ 769 CRC_EPB_1M "CRC-checksum byte 1 to 7 according to SAE J1850";
CM_ SG_ 770 ClampForce "EPB clamp force";
CM_ SG_ 770 StopLampActive "Stop Lamp active request";
CM_ SG_ 770 FaultStoreInfo "Fault (DTC) store information";
CM_ SG_ 770 EPBSwitchPosition "EPB switch position";
CM_ SG_ 770 EPBSts "EPB status for external system";
CM_ SG_ 770 AutoParkSts "Auto park status (snable/disable)";
CM_ SG_ 770 EPBChimeReq "EPB chime request";
CM_ SG_ 770 ServiceModeSts "EPB service mode status";
CM_ SG_ 770 TextDisplay "Text message display request";
CM_ SG_ 770 ValidEPBSWPos "Valid EPB switch position";
CM_ SG_ 770 EnableDecelerationReq "Enable (active) deceleration request";
CM_ SG_ 770 FunctionLamp "EPB function lamp (BRAKE) active request";
CM_ SG_ 770 EPBWarningLampReq "EPB warning lamp active request";
CM_ SG_ 770 MC_EPB_1 "Message counter";
CM_ SG_ 770 CRC_EPB_1 "CRC-checksum byte 1 to 7 according to SAE J1850";
CM_ SG_ 772 TPM_IndLmp_On_Rq "Tire pressure indication request";
CM_ SG_ 772 TPM_Chime_Rq "TPM chime request";
CM_ SG_ 772 TPM_SwIndRq "TPM load switch indicator request";
CM_ SG_ 772 TPM_Sys_Stat "TPM system localization status";
CM_ SG_ 772 TireFL "Tire front left";
CM_ SG_ 772 TireFR "Tire front right";
CM_ SG_ 772 TireRR "Tire rear right";
CM_ SG_ 772 TireRL "Tire rear left";
CM_ SG_ 772 TireSpr "Spare tire";
CM_ SG_ 772 RunFlatTireLow "Run flat tire low pressure; true = [1]";
CM_ SG_ 772 TirePressFL "Tire pressure front left";
CM_ SG_ 772 TirePressFR "Tire pressure front right";
CM_ SG_ 772 TirePressRL "Tire pressure rear left";
CM_ SG_ 772 TirePressRR "Tire pressure rear right";
CM_ SG_ 772 TirePressSpr "Tire pressure spare tire";
BA_DEF_ SG_  "GenSigTimeout_ADCM" INT 0 65535;
BA_DEF_ SG_  "GenSigTimeout_AFLS" INT 0 65535;
BA_DEF_ SG_  "GenSigTimeout_CBC" INT 0 65535;
BA_DEF_ SG_  "GenSigTimeout_DTCM" INT 0 65535;
BA_DEF_ SG_  "GenSigTimeout_ECM" INT 0 65535;
BA_DEF_ SG_  "GenSigTimeout_EPS" INT 0 65535;
BA_DEF_ SG_  "GenSigTimeout_ESC" INT 0 65535;
BA_DEF_ SG_  "GenSigTimeout_ESM" INT 0 65535;
BA_DEF_ SG_  "GenSigTimeout_ETM" INT 0 65535;
BA_DEF_ SG_  "GenSigTimeout_HaLF" INT 0 65535;
BA_DEF_ SG_  "GenSigTimeout_IC" INT 0 65535;
BA_DEF_ SG_  "GenSigTimeout_ORC" INT 0 65535;
BA_DEF_ SG_  "GenSigTimeout_PTS" INT 0 65535;
BA_DEF_ SG_  "GenSigTimeout_RF_HUB" INT 0 65535;
BA_DEF_ SG_  "GenSigTimeout_SCCM" INT 0 65535;
BA_DEF_ SG_  "GenSigTimeout_TPM" INT 0 65535;
BA_DEF_ BO_  "GenMsgStartValue" STRING ;
BA_DEF_ SG_  "GenSigSNA" STRING ;
BA_DEF_ SG_  "FlexKomIsMotorola" ENUM  "nein","ja";
BA_DEF_ SG_  "FlexKomSigLaenge" INT 0 64;
BA_DEF_ SG_  "FlexKomSigStartPos" INT 0 63;
BA_DEF_ SG_  "FlexKomComment" STRING ;
BA_DEF_ SG_  "FlexKomSigName" STRING ;
BA_DEF_ SG_  "FlexKomSID" INT 0 2147483647;
BA_DEF_ SG_  "GenSigStartValue" HEX 0 4294967295;
BA_DEF_ SG_  "FlexKomSigStartValue" STRING ;
BA_DEF_ SG_  "GenSigCycleTimeActive" INT 0 65535;
BA_DEF_ SG_  "GenSigCycleTime" INT 0 65535;
BA_DEF_ SG_  "GenSigSendType" ENUM  "cyclicX","spontanX","cyclicIfActiveX","spontanWithDelay","cyclicAndSpontanX","cyclicAndSpontanWithDelay","spontanWithRepitition","cyclicIfActiveAndSpontanWD","cyclicIfActiveFast","cyclicWithRepeatOnDemand","none";
BA_DEF_ BO_  "GenMsgNrOfRepetitions" INT 0 65535;
BA_DEF_ BO_  "GenMsgDelayTime" INT 0 65535;
BA_DEF_ BO_  "GenMsgStartDelayTime" INT 0 65535;
BA_DEF_ BO_  "GenMsgCycleTimeActive" INT 0 65535;
BA_DEF_ BO_  "GenMsgCycleTime" INT 0 65535;
BA_DEF_ BO_  "GenMsgSendType" ENUM  "cyclicX","spontanX","cyclicIfActiveX","spontanWithDelay","cyclicAndSpontanX","cyclicAndSpontanWithDelay","spontanWithRepitition","cyclicIfActiveAndSpontanWD","cyclicIfActiveFast","cyclicWithRepeatOnDemand","none";
BA_DEF_ BO_  "DiagResponse" ENUM  "nein","ja";
BA_DEF_ BO_  "DiagRequest" ENUM  "nein","ja";
BA_DEF_ BO_  "DiagState" ENUM  "nein","ja";
BA_DEF_ BO_  "App-Botschaft" ENUM  "nein","ja";
BA_DEF_ BO_  "NWM-Botschaft" ENUM  "nein","ja";
BA_DEF_DEF_  "GenSigTimeout_ADCM" 0;
BA_DEF_DEF_  "GenSigTimeout_AFLS" 0;
BA_DEF_DEF_  "GenSigTimeout_CBC" 0;
BA_DEF_DEF_  "GenSigTimeout_DTCM" 0;
BA_DEF_DEF_  "GenSigTimeout_ECM" 0;
BA_DEF_DEF_  "GenSigTimeout_EPS" 0;
BA_DEF_DEF_  "GenSigTimeout_ESC" 0;
BA_DEF_DEF_  "GenSigTimeout_ESM" 0;
BA_DEF_DEF_  "GenSigTimeout_ETM" 0;
BA_DEF_DEF_  "GenSigTimeout_HaLF" 0;
BA_DEF_DEF_  "GenSigTimeout_IC" 0;
BA_DEF_DEF_  "GenSigTimeout_ORC" 0;
BA_DEF_DEF_  "GenSigTimeout_PTS" 0;
BA_DEF_DEF_  "GenSigTimeout_RF_HUB" 0;
BA_DEF_DEF_  "GenSigTimeout_SCCM" 0;
BA_DEF_DEF_  "GenSigTimeout_TPM" 0;
BA_DEF_DEF_  "GenMsgStartValue" "";
BA_DEF_DEF_  "GenSigSNA" "";
BA_DEF_DEF_  "FlexKomIsMotorola" "nein";
BA_DEF_DEF_  "FlexKomSigLaenge" 0;
BA_DEF_DEF_  "FlexKomSigStartPos" 0;
BA_DEF_DEF_  "FlexKomComment" "";
BA_DEF_DEF_  "FlexKomSigName" "";
BA_DEF_DEF_  "FlexKomSID" 0;
BA_DEF_DEF_  "GenSigStartValue" 0;
BA_DEF_DEF_  "FlexKomSigStartValue" "";
BA_DEF_DEF_  "GenSigCycleTimeActive" 0;
BA_DEF_DEF_  "GenSigCycleTime" 0;
BA_DEF_DEF_  "GenSigSendType" "cyclicX";
BA_DEF_DEF_  "GenMsgNrOfRepetitions" 0;
BA_DEF_DEF_  "GenMsgDelayTime" 0;
BA_DEF_DEF_  "GenMsgStartDelayTime" 0;
BA_DEF_DEF_  "GenMsgCycleTimeActive" 0;
BA_DEF_DEF_  "GenMsgCycleTime" 0;
BA_DEF_DEF_  "GenMsgSendType" "cyclicX";
BA_DEF_DEF_  "DiagResponse" "nein";
BA_DEF_DEF_  "DiagRequest" "nein";
BA_DEF_DEF_  "DiagState" "nein";
BA_DEF_DEF_  "App-Botschaft" "nein";
BA_DEF_DEF_  "NWM-Botschaft" "nein";
BA_ "GenMsgSendType" BO_ 678 5;
BA_ "GenMsgCycleTime" BO_ 678 250;
BA_ "GenMsgDelayTime" BO_ 678 20;
BA_ "GenMsgNrOfRepetitions" BO_ 678 2;
BA_ "GenMsgStartValue" BO_ 678 "0000000000000000h";
BA_ "GenMsgCycleTime" BO_ 680 20;
BA_ "GenMsgDelayTime" BO_ 680 20;
BA_ "GenMsgNrOfRepetitions" BO_ 680 2;
BA_ "GenMsgStartValue" BO_ 680 "0FFF0F0F000000FFh";
BA_ "GenMsgCycleTime" BO_ 683 100;
BA_ "GenMsgDelayTime" BO_ 683 20;
BA_ "GenMsgNrOfRepetitions" BO_ 683 2;
BA_ "GenMsgStartValue" BO_ 683 "5A5AAAAAAAAAAAAAh";
BA_ "GenMsgStartDelayTime" BO_ 683 30;
BA_ "GenMsgSendType" BO_ 685 5;
BA_ "GenMsgCycleTime" BO_ 685 1000;
BA_ "GenMsgDelayTime" BO_ 685 20;
BA_ "GenMsgNrOfRepetitions" BO_ 685 2;
BA_ "GenMsgStartValue" BO_ 685 "0080AFAAAAAAAAAAh";
BA_ "GenMsgStartDelayTime" BO_ 685 110;
BA_ "GenMsgSendType" BO_ 687 5;
BA_ "GenMsgCycleTime" BO_ 687 1000;
BA_ "GenMsgDelayTime" BO_ 687 20;
BA_ "GenMsgNrOfRepetitions" BO_ 687 2;
BA_ "GenMsgStartValue" BO_ 687 "09FFFFFF01010101h";
BA_ "GenMsgSendType" BO_ 688 5;
BA_ "GenMsgCycleTime" BO_ 688 1000;
BA_ "GenMsgDelayTime" BO_ 688 20;
BA_ "GenMsgNrOfRepetitions" BO_ 688 2;
BA_ "GenMsgStartValue" BO_ 688 "0000h";
BA_ "GenMsgSendType" BO_ 698 8;
BA_ "GenMsgCycleTimeActive" BO_ 698 100;
BA_ "GenMsgDelayTime" BO_ 698 20;
BA_ "GenMsgNrOfRepetitions" BO_ 698 2;
BA_ "GenMsgStartValue" BO_ 698 "00000000h";
BA_ "GenMsgSendType" BO_ 706 5;
BA_ "GenMsgCycleTime" BO_ 706 2000;
BA_ "GenMsgDelayTime" BO_ 706 20;
BA_ "GenMsgNrOfRepetitions" BO_ 706 2;
BA_ "GenMsgStartValue" BO_ 706 "0300000000000000h";
BA_ "GenMsgSendType" BO_ 707 1;
BA_ "GenMsgDelayTime" BO_ 707 20;
BA_ "GenMsgNrOfRepetitions" BO_ 707 2;
BA_ "GenMsgStartValue" BO_ 707 "0300000000000000h";
BA_ "GenMsgSendType" BO_ 719 5;
BA_ "GenMsgCycleTime" BO_ 719 500;
BA_ "GenMsgDelayTime" BO_ 719 20;
BA_ "GenMsgNrOfRepetitions" BO_ 719 2;
BA_ "GenMsgStartValue" BO_ 719 "0000000000000000h";
BA_ "GenMsgSendType" BO_ 720 5;
BA_ "GenMsgCycleTime" BO_ 720 500;
BA_ "GenMsgDelayTime" BO_ 720 20;
BA_ "GenMsgNrOfRepetitions" BO_ 720 2;
BA_ "GenMsgStartValue" BO_ 720 "000300000000h";
BA_ "GenMsgSendType" BO_ 729 5;
BA_ "GenMsgCycleTime" BO_ 729 100;
BA_ "GenMsgDelayTime" BO_ 729 20;
BA_ "GenMsgNrOfRepetitions" BO_ 729 2;
BA_ "GenMsgStartValue" BO_ 729 "0000000020h";
BA_ "GenMsgSendType" BO_ 734 1;
BA_ "GenMsgDelayTime" BO_ 734 20;
BA_ "GenMsgNrOfRepetitions" BO_ 734 2;
BA_ "GenMsgStartValue" BO_ 734 "00000000000000h";
BA_ "GenMsgSendType" BO_ 735 1;
BA_ "GenMsgDelayTime" BO_ 735 20;
BA_ "GenMsgNrOfRepetitions" BO_ 735 2;
BA_ "GenMsgStartValue" BO_ 735 "00000000000000h";
BA_ "GenMsgCycleTime" BO_ 736 50;
BA_ "GenMsgDelayTime" BO_ 736 20;
BA_ "GenMsgNrOfRepetitions" BO_ 736 2;
BA_ "GenMsgStartValue" BO_ 736 "FFFFFFFF0000003Fh";
BA_ "GenMsgCycleTime" BO_ 737 100;
BA_ "GenMsgDelayTime" BO_ 737 20;
BA_ "GenMsgNrOfRepetitions" BO_ 737 2;
BA_ "GenMsgStartValue" BO_ 737 "C1FE01FE00000000h";
BA_ "GenMsgCycleTime" BO_ 739 100;
BA_ "GenMsgDelayTime" BO_ 739 20;
BA_ "GenMsgNrOfRepetitions" BO_ 739 2;
BA_ "GenMsgStartValue" BO_ 739 "FF00FFFFFF000000h";
BA_ "GenMsgCycleTime" BO_ 746 20;
BA_ "GenMsgDelayTime" BO_ 746 20;
BA_ "GenMsgNrOfRepetitions" BO_ 746 2;
BA_ "GenMsgStartValue" BO_ 746 "00000000FFh";
BA_ "GenMsgSendType" BO_ 752 5;
BA_ "GenMsgCycleTime" BO_ 752 500;
BA_ "GenMsgDelayTime" BO_ 752 20;
BA_ "GenMsgNrOfRepetitions" BO_ 752 2;
BA_ "GenMsgStartValue" BO_ 752 "0600h";
BA_ "GenMsgCycleTime" BO_ 760 10;
BA_ "GenMsgDelayTime" BO_ 760 20;
BA_ "GenMsgNrOfRepetitions" BO_ 760 2;
BA_ "GenMsgStartValue" BO_ 760 "1FFF1FFF00FF0FFFh";
BA_ "GenMsgCycleTime" BO_ 761 10;
BA_ "GenMsgDelayTime" BO_ 761 20;
BA_ "GenMsgNrOfRepetitions" BO_ 761 2;
BA_ "GenMsgStartValue" BO_ 761 "1FFF1FFF1FFF00FFh";
BA_ "GenMsgCycleTime" BO_ 762 20;
BA_ "GenMsgDelayTime" BO_ 762 20;
BA_ "GenMsgNrOfRepetitions" BO_ 762 2;
BA_ "GenMsgStartValue" BO_ 762 "F04C0000FFh";
BA_ "GenMsgCycleTime" BO_ 764 100;
BA_ "GenMsgDelayTime" BO_ 764 20;
BA_ "GenMsgNrOfRepetitions" BO_ 764 2;
BA_ "GenMsgStartValue" BO_ 764 "00FFFFFFFFFFFFFFh";
BA_ "GenMsgCycleTime" BO_ 766 100;
BA_ "GenMsgDelayTime" BO_ 766 20;
BA_ "GenMsgNrOfRepetitions" BO_ 766 2;
BA_ "GenMsgStartValue" BO_ 766 "FFFFFFFF0000FF00h";
BA_ "GenMsgCycleTime" BO_ 769 100;
BA_ "GenMsgDelayTime" BO_ 769 20;
BA_ "GenMsgNrOfRepetitions" BO_ 769 2;
BA_ "GenMsgStartValue" BO_ 769 "00020700000000FFh";
BA_ "GenMsgCycleTime" BO_ 770 100;
BA_ "GenMsgDelayTime" BO_ 770 20;
BA_ "GenMsgNrOfRepetitions" BO_ 770 2;
BA_ "GenMsgStartValue" BO_ 770 "00000000000000FFh";
BA_ "GenMsgCycleTime" BO_ 772 1000;
BA_ "GenMsgDelayTime" BO_ 772 20;
BA_ "GenMsgNrOfRepetitions" BO_ 772 2;
BA_ "GenMsgStartValue" BO_ 772 "000000FFFFFFFFFFh";
BA_ "GenSigSendType" SG_ 678 ISO_TelltaleSts 5;
BA_ "GenSigCycleTime" SG_ 678 ISO_TelltaleSts 250;
BA_ "FlexKomSigStartValue" SG_ 678 ISO_TelltaleSts "00h";
BA_ "GenSigTimeout_IC" SG_ 678 ISO_TelltaleSts 2625;
BA_ "FlexKomSID" SG_ 678 ISO_TelltaleSts 2015;
BA_ "FlexKomSigStartPos" SG_ 678 ISO_TelltaleSts 2;
BA_ "FlexKomSigLaenge" SG_ 678 ISO_TelltaleSts 3;
BA_ "FlexKomSigName" SG_ 678 ISO_TelltaleSts "ISO_TelltaleSts";
BA_ "FlexKomComment" SG_ 678 ISO_TelltaleSts "LDW telltale status in cluster";
BA_ "FlexKomIsMotorola" SG_ 678 ISO_TelltaleSts 1;
BA_ "GenSigSNA" SG_ 678 ISO_TelltaleSts "7h";
BA_ "GenSigSendType" SG_ 678 TrqIntensitySts 5;
BA_ "GenSigCycleTime" SG_ 678 TrqIntensitySts 250;
BA_ "FlexKomSigStartValue" SG_ 678 TrqIntensitySts "00h";
BA_ "GenSigTimeout_IC" SG_ 678 TrqIntensitySts 2625;
BA_ "FlexKomSID" SG_ 678 TrqIntensitySts 2016;
BA_ "FlexKomSigStartPos" SG_ 678 TrqIntensitySts 12;
BA_ "FlexKomSigLaenge" SG_ 678 TrqIntensitySts 3;
BA_ "FlexKomSigName" SG_ 678 TrqIntensitySts "TrqIntensitySts";
BA_ "FlexKomComment" SG_ 678 TrqIntensitySts "LDW torque intesity level for display in cluster";
BA_ "FlexKomIsMotorola" SG_ 678 TrqIntensitySts 1;
BA_ "GenSigSNA" SG_ 678 TrqIntensitySts "7h";
BA_ "GenSigSendType" SG_ 678 SensitivitySts 5;
BA_ "GenSigCycleTime" SG_ 678 SensitivitySts 250;
BA_ "FlexKomSigStartValue" SG_ 678 SensitivitySts "00h";
BA_ "GenSigTimeout_IC" SG_ 678 SensitivitySts 2625;
BA_ "FlexKomSID" SG_ 678 SensitivitySts 2017;
BA_ "FlexKomSigStartPos" SG_ 678 SensitivitySts 15;
BA_ "FlexKomSigLaenge" SG_ 678 SensitivitySts 3;
BA_ "FlexKomSigName" SG_ 678 SensitivitySts "SensitivitySts";
BA_ "FlexKomComment" SG_ 678 SensitivitySts "LDW sensitivity level for display in cluster";
BA_ "FlexKomIsMotorola" SG_ 678 SensitivitySts 1;
BA_ "GenSigSNA" SG_ 678 SensitivitySts "7h";
BA_ "GenSigSendType" SG_ 678 DisplaySts 5;
BA_ "GenSigCycleTime" SG_ 678 DisplaySts 250;
BA_ "FlexKomSigStartValue" SG_ 678 DisplaySts "00h";
BA_ "GenSigTimeout_IC" SG_ 678 DisplaySts 2625;
BA_ "FlexKomSID" SG_ 678 DisplaySts 2018;
BA_ "FlexKomSigStartPos" SG_ 678 DisplaySts 23;
BA_ "FlexKomSigLaenge" SG_ 678 DisplaySts 8;
BA_ "FlexKomSigName" SG_ 678 DisplaySts "DisplaySts";
BA_ "FlexKomComment" SG_ 678 DisplaySts "LDW display status in cluster";
BA_ "FlexKomIsMotorola" SG_ 678 DisplaySts 1;
BA_ "GenSigSNA" SG_ 678 DisplaySts "FFh";
BA_ "GenSigSendType" SG_ 678 DispPopupSts 5;
BA_ "GenSigCycleTime" SG_ 678 DispPopupSts 250;
BA_ "FlexKomSigStartValue" SG_ 678 DispPopupSts "00h";
BA_ "GenSigTimeout_IC" SG_ 678 DispPopupSts 2625;
BA_ "FlexKomSID" SG_ 678 DispPopupSts 2019;
BA_ "FlexKomSigStartPos" SG_ 678 DispPopupSts 31;
BA_ "FlexKomSigLaenge" SG_ 678 DispPopupSts 8;
BA_ "FlexKomSigName" SG_ 678 DispPopupSts "DispPopupSts";
BA_ "FlexKomComment" SG_ 678 DispPopupSts "LDW message status in cluster";
BA_ "FlexKomIsMotorola" SG_ 678 DispPopupSts 1;
BA_ "GenSigSNA" SG_ 678 DispPopupSts "FFh";
BA_ "GenSigSendType" SG_ 678 HALF_CHIME_TYPESts 5;
BA_ "GenSigCycleTime" SG_ 678 HALF_CHIME_TYPESts 250;
BA_ "FlexKomSigStartValue" SG_ 678 HALF_CHIME_TYPESts "00h";
BA_ "GenSigTimeout_CBC" SG_ 678 HALF_CHIME_TYPESts 2625;
BA_ "FlexKomSID" SG_ 678 HALF_CHIME_TYPESts 2020;
BA_ "FlexKomSigStartPos" SG_ 678 HALF_CHIME_TYPESts 35;
BA_ "FlexKomSigLaenge" SG_ 678 HALF_CHIME_TYPESts 4;
BA_ "FlexKomSigName" SG_ 678 HALF_CHIME_TYPESts "HALF_CHIME_TYPESts";
BA_ "FlexKomComment" SG_ 678 HALF_CHIME_TYPESts "LDW chime type";
BA_ "FlexKomIsMotorola" SG_ 678 HALF_CHIME_TYPESts 1;
BA_ "GenSigSNA" SG_ 678 HALF_CHIME_TYPESts "Fh";
BA_ "GenSigSendType" SG_ 678 HALF_CHIME_REP_RATESts 5;
BA_ "GenSigCycleTime" SG_ 678 HALF_CHIME_REP_RATESts 250;
BA_ "FlexKomSigStartValue" SG_ 678 HALF_CHIME_REP_RATESts "00h";
BA_ "GenSigTimeout_CBC" SG_ 678 HALF_CHIME_REP_RATESts 2625;
BA_ "FlexKomSID" SG_ 678 HALF_CHIME_REP_RATESts 2021;
BA_ "FlexKomSigStartPos" SG_ 678 HALF_CHIME_REP_RATESts 39;
BA_ "FlexKomSigLaenge" SG_ 678 HALF_CHIME_REP_RATESts 4;
BA_ "FlexKomSigName" SG_ 678 HALF_CHIME_REP_RATESts "HALF_CHIME_REP_RATESts";
BA_ "FlexKomComment" SG_ 678 HALF_CHIME_REP_RATESts "LDW chime repetition rate";
BA_ "FlexKomIsMotorola" SG_ 678 HALF_CHIME_REP_RATESts 1;
BA_ "GenSigSNA" SG_ 678 HALF_CHIME_REP_RATESts "0h";
BA_ "GenSigSendType" SG_ 678 HALF_LF_CHIME_RQSts 5;
BA_ "GenSigCycleTime" SG_ 678 HALF_LF_CHIME_RQSts 250;
BA_ "FlexKomSigStartValue" SG_ 678 HALF_LF_CHIME_RQSts "00h";
BA_ "FlexKomSID" SG_ 678 HALF_LF_CHIME_RQSts 2023;
BA_ "FlexKomSigStartPos" SG_ 678 HALF_LF_CHIME_RQSts 40;
BA_ "FlexKomSigLaenge" SG_ 678 HALF_LF_CHIME_RQSts 1;
BA_ "FlexKomSigName" SG_ 678 HALF_LF_CHIME_RQSts "HALF_LF_CHIME_RQSts";
BA_ "FlexKomComment" SG_ 678 HALF_LF_CHIME_RQSts "LDW chime request for left side; true = [1]";
BA_ "FlexKomIsMotorola" SG_ 678 HALF_LF_CHIME_RQSts 1;
BA_ "GenSigSNA" SG_ 678 HALF_LF_CHIME_RQSts "0h";
BA_ "GenSigSendType" SG_ 678 HALF_RF_CHIME_RQSts 5;
BA_ "GenSigCycleTime" SG_ 678 HALF_RF_CHIME_RQSts 250;
BA_ "FlexKomSigStartValue" SG_ 678 HALF_RF_CHIME_RQSts "00h";
BA_ "FlexKomSID" SG_ 678 HALF_RF_CHIME_RQSts 2022;
BA_ "FlexKomSigStartPos" SG_ 678 HALF_RF_CHIME_RQSts 41;
BA_ "FlexKomSigLaenge" SG_ 678 HALF_RF_CHIME_RQSts 1;
BA_ "FlexKomSigName" SG_ 678 HALF_RF_CHIME_RQSts "HALF_RF_CHIME_RQSts";
BA_ "FlexKomComment" SG_ 678 HALF_RF_CHIME_RQSts "LDW chime request for right side; true = [1]";
BA_ "FlexKomIsMotorola" SG_ 678 HALF_RF_CHIME_RQSts 1;
BA_ "GenSigSNA" SG_ 678 HALF_RF_CHIME_RQSts "0h";
BA_ "GenSigCycleTime" SG_ 680 EngTrgtSpdCtrl 20;
BA_ "FlexKomSigStartValue" SG_ 680 EngTrgtSpdCtrl "0FFF0F0F000000FFh";
BA_ "GenSigStartValue" SG_ 680 EngTrgtSpdCtrl 4095;
BA_ "FlexKomSID" SG_ 680 EngTrgtSpdCtrl 1613;
BA_ "FlexKomSigStartPos" SG_ 680 EngTrgtSpdCtrl 7;
BA_ "FlexKomSigLaenge" SG_ 680 EngTrgtSpdCtrl 64;
BA_ "FlexKomSigName" SG_ 680 EngTrgtSpdCtrl "TCM_A7_PKT";
BA_ "FlexKomComment" SG_ 680 EngTrgtSpdCtrl "Transmission message A7 packet";
BA_ "FlexKomIsMotorola" SG_ 680 EngTrgtSpdCtrl 1;
BA_ "GenSigSNA" SG_ 680 EngTrgtSpdCtrl "FFFh";
BA_ "GenSigCycleTime" SG_ 680 EngShutOffRq_TCM 20;
BA_ "FlexKomSigStartValue" SG_ 680 EngShutOffRq_TCM "0FFF0F0F000000FFh";
BA_ "FlexKomSID" SG_ 680 EngShutOffRq_TCM 1613;
BA_ "FlexKomSigStartPos" SG_ 680 EngShutOffRq_TCM 7;
BA_ "FlexKomSigLaenge" SG_ 680 EngShutOffRq_TCM 64;
BA_ "FlexKomSigName" SG_ 680 EngShutOffRq_TCM "TCM_A7_PKT";
BA_ "FlexKomComment" SG_ 680 EngShutOffRq_TCM "Transmission message A7 packet";
BA_ "FlexKomIsMotorola" SG_ 680 EngShutOffRq_TCM 1;
BA_ "GenSigSNA" SG_ 680 EngShutOffRq_TCM "0h";
BA_ "GenSigCycleTime" SG_ 680 EmodeBtnSts 20;
BA_ "FlexKomSigStartValue" SG_ 680 EmodeBtnSts "0FFF0F0F000000FFh";
BA_ "GenSigTimeout_CBC" SG_ 680 EmodeBtnSts 210;
BA_ "FlexKomSID" SG_ 680 EmodeBtnSts 1613;
BA_ "FlexKomSigStartPos" SG_ 680 EmodeBtnSts 7;
BA_ "FlexKomSigLaenge" SG_ 680 EmodeBtnSts 64;
BA_ "FlexKomSigName" SG_ 680 EmodeBtnSts "TCM_A7_PKT";
BA_ "FlexKomComment" SG_ 680 EmodeBtnSts "Transmission message A7 packet";
BA_ "FlexKomIsMotorola" SG_ 680 EmodeBtnSts 1;
BA_ "GenSigSNA" SG_ 680 EmodeBtnSts "3h";
BA_ "GenSigCycleTime" SG_ 680 EngTrgtSpdCtrl_Active 20;
BA_ "FlexKomSigStartValue" SG_ 680 EngTrgtSpdCtrl_Active "0FFF0F0F000000FFh";
BA_ "FlexKomSID" SG_ 680 EngTrgtSpdCtrl_Active 1613;
BA_ "FlexKomSigStartPos" SG_ 680 EngTrgtSpdCtrl_Active 7;
BA_ "FlexKomSigLaenge" SG_ 680 EngTrgtSpdCtrl_Active 64;
BA_ "FlexKomSigName" SG_ 680 EngTrgtSpdCtrl_Active "TCM_A7_PKT";
BA_ "FlexKomComment" SG_ 680 EngTrgtSpdCtrl_Active "Transmission message A7 packet";
BA_ "FlexKomIsMotorola" SG_ 680 EngTrgtSpdCtrl_Active 1;
BA_ "GenSigSNA" SG_ 680 EngTrgtSpdCtrl_Active "0h";
BA_ "GenSigCycleTime" SG_ 680 CurrentGear 20;
BA_ "FlexKomSigStartValue" SG_ 680 CurrentGear "0FFF0F0F000000FFh";
BA_ "GenSigStartValue" SG_ 680 CurrentGear 15;
BA_ "FlexKomSID" SG_ 680 CurrentGear 1613;
BA_ "FlexKomSigStartPos" SG_ 680 CurrentGear 7;
BA_ "FlexKomSigLaenge" SG_ 680 CurrentGear 64;
BA_ "FlexKomSigName" SG_ 680 CurrentGear "TCM_A7_PKT";
BA_ "FlexKomComment" SG_ 680 CurrentGear "Transmission message A7 packet";
BA_ "FlexKomIsMotorola" SG_ 680 CurrentGear 1;
BA_ "GenSigSNA" SG_ 680 CurrentGear "Fh";
BA_ "GenSigCycleTime" SG_ 680 CurrentGearForDisplay 20;
BA_ "FlexKomSigStartValue" SG_ 680 CurrentGearForDisplay "0FFF0F0F000000FFh";
BA_ "GenSigTimeout_IC" SG_ 680 CurrentGearForDisplay 210;
BA_ "FlexKomSID" SG_ 680 CurrentGearForDisplay 1613;
BA_ "FlexKomSigStartPos" SG_ 680 CurrentGearForDisplay 7;
BA_ "FlexKomSigLaenge" SG_ 680 CurrentGearForDisplay 64;
BA_ "FlexKomSigName" SG_ 680 CurrentGearForDisplay "TCM_A7_PKT";
BA_ "FlexKomComment" SG_ 680 CurrentGearForDisplay "Transmission message A7 packet";
BA_ "FlexKomIsMotorola" SG_ 680 CurrentGearForDisplay 1;
BA_ "GenSigSNA" SG_ 680 CurrentGearForDisplay "Fh";
BA_ "GenSigCycleTime" SG_ 680 TargetGear 20;
BA_ "FlexKomSigStartValue" SG_ 680 TargetGear "0FFF0F0F000000FFh";
BA_ "GenSigStartValue" SG_ 680 TargetGear 15;
BA_ "FlexKomSID" SG_ 680 TargetGear 1613;
BA_ "FlexKomSigStartPos" SG_ 680 TargetGear 7;
BA_ "FlexKomSigLaenge" SG_ 680 TargetGear 64;
BA_ "FlexKomSigName" SG_ 680 TargetGear "TCM_A7_PKT";
BA_ "FlexKomComment" SG_ 680 TargetGear "Transmission message A7 packet";
BA_ "FlexKomIsMotorola" SG_ 680 TargetGear 1;
BA_ "GenSigSNA" SG_ 680 TargetGear "Fh";
BA_ "GenSigCycleTime" SG_ 680 TX_WARN2 20;
BA_ "FlexKomSigStartValue" SG_ 680 TX_WARN2 "0FFF0F0F000000FFh";
BA_ "GenSigTimeout_IC" SG_ 680 TX_WARN2 210;
BA_ "FlexKomSID" SG_ 680 TX_WARN2 1613;
BA_ "FlexKomSigStartPos" SG_ 680 TX_WARN2 7;
BA_ "FlexKomSigLaenge" SG_ 680 TX_WARN2 64;
BA_ "FlexKomSigName" SG_ 680 TX_WARN2 "TCM_A7_PKT";
BA_ "FlexKomComment" SG_ 680 TX_WARN2 "Transmission message A7 packet";
BA_ "FlexKomIsMotorola" SG_ 680 TX_WARN2 1;
BA_ "GenSigSNA" SG_ 680 TX_WARN2 "FFh";
BA_ "GenSigCycleTime" SG_ 680 MC_TCM_A7 20;
BA_ "FlexKomSigStartValue" SG_ 680 MC_TCM_A7 "0FFF0F0F000000FFh";
BA_ "FlexKomSID" SG_ 680 MC_TCM_A7 1613;
BA_ "FlexKomSigStartPos" SG_ 680 MC_TCM_A7 7;
BA_ "FlexKomSigLaenge" SG_ 680 MC_TCM_A7 64;
BA_ "FlexKomSigName" SG_ 680 MC_TCM_A7 "TCM_A7_PKT";
BA_ "FlexKomComment" SG_ 680 MC_TCM_A7 "Transmission message A7 packet";
BA_ "FlexKomIsMotorola" SG_ 680 MC_TCM_A7 1;
BA_ "GenSigSNA" SG_ 680 MC_TCM_A7 "0h";
BA_ "GenSigCycleTime" SG_ 680 CRC_TCM_A7 20;
BA_ "FlexKomSigStartValue" SG_ 680 CRC_TCM_A7 "0FFF0F0F000000FFh";
BA_ "GenSigStartValue" SG_ 680 CRC_TCM_A7 255;
BA_ "FlexKomSID" SG_ 680 CRC_TCM_A7 1613;
BA_ "FlexKomSigStartPos" SG_ 680 CRC_TCM_A7 7;
BA_ "FlexKomSigLaenge" SG_ 680 CRC_TCM_A7 64;
BA_ "FlexKomSigName" SG_ 680 CRC_TCM_A7 "TCM_A7_PKT";
BA_ "FlexKomComment" SG_ 680 CRC_TCM_A7 "Transmission message A7 packet";
BA_ "FlexKomIsMotorola" SG_ 680 CRC_TCM_A7 1;
BA_ "GenSigSNA" SG_ 680 CRC_TCM_A7 "FFh";
BA_ "GenSigCycleTime" SG_ 683 Pitch_Angle 100;
BA_ "FlexKomSigStartValue" SG_ 683 Pitch_Angle "5Ah";
BA_ "GenSigStartValue" SG_ 683 Pitch_Angle 90;
BA_ "GenSigTimeout_IC" SG_ 683 Pitch_Angle 1050;
BA_ "FlexKomSID" SG_ 683 Pitch_Angle 1963;
BA_ "FlexKomSigStartPos" SG_ 683 Pitch_Angle 7;
BA_ "FlexKomSigLaenge" SG_ 683 Pitch_Angle 8;
BA_ "FlexKomSigName" SG_ 683 Pitch_Angle "Pitch_Angle";
BA_ "FlexKomComment" SG_ 683 Pitch_Angle "Pitch angle";
BA_ "FlexKomIsMotorola" SG_ 683 Pitch_Angle 1;
BA_ "GenSigSNA" SG_ 683 Pitch_Angle "FFh";
BA_ "GenSigCycleTime" SG_ 683 Roll_Angle 100;
BA_ "FlexKomSigStartValue" SG_ 683 Roll_Angle "5Ah";
BA_ "GenSigStartValue" SG_ 683 Roll_Angle 90;
BA_ "GenSigTimeout_IC" SG_ 683 Roll_Angle 1050;
BA_ "FlexKomSID" SG_ 683 Roll_Angle 1962;
BA_ "FlexKomSigStartPos" SG_ 683 Roll_Angle 15;
BA_ "FlexKomSigLaenge" SG_ 683 Roll_Angle 8;
BA_ "FlexKomSigName" SG_ 683 Roll_Angle "Roll_Angle";
BA_ "FlexKomComment" SG_ 683 Roll_Angle "Roll angle";
BA_ "FlexKomIsMotorola" SG_ 683 Roll_Angle 1;
BA_ "GenSigSNA" SG_ 683 Roll_Angle "FFh";
BA_ "GenSigSendType" SG_ 685 CBC_AUX1_Type 5;
BA_ "GenSigCycleTime" SG_ 685 CBC_AUX1_Type 1000;
BA_ "FlexKomSigStartValue" SG_ 685 CBC_AUX1_Type "0080AFAAAAAAAAAAh";
BA_ "GenSigTimeout_IC" SG_ 685 CBC_AUX1_Type 10500;
BA_ "FlexKomSID" SG_ 685 CBC_AUX1_Type 1957;
BA_ "FlexKomSigStartPos" SG_ 685 CBC_AUX1_Type 7;
BA_ "FlexKomSigLaenge" SG_ 685 CBC_AUX1_Type 64;
BA_ "FlexKomSigName" SG_ 685 CBC_AUX1_Type "CBC_Cfg2_Pkt";
BA_ "FlexKomComment" SG_ 685 CBC_AUX1_Type "Configuration status CBC 2";
BA_ "FlexKomIsMotorola" SG_ 685 CBC_AUX1_Type 1;
BA_ "GenSigSNA" SG_ 685 CBC_AUX1_Type "0h";
BA_ "GenSigSendType" SG_ 685 CBC_AUX2_Type 5;
BA_ "GenSigCycleTime" SG_ 685 CBC_AUX2_Type 1000;
BA_ "FlexKomSigStartValue" SG_ 685 CBC_AUX2_Type "0080AFAAAAAAAAAAh";
BA_ "GenSigTimeout_IC" SG_ 685 CBC_AUX2_Type 10500;
BA_ "FlexKomSID" SG_ 685 CBC_AUX2_Type 1957;
BA_ "FlexKomSigStartPos" SG_ 685 CBC_AUX2_Type 7;
BA_ "FlexKomSigLaenge" SG_ 685 CBC_AUX2_Type 64;
BA_ "FlexKomSigName" SG_ 685 CBC_AUX2_Type "CBC_Cfg2_Pkt";
BA_ "FlexKomComment" SG_ 685 CBC_AUX2_Type "Configuration status CBC 2";
BA_ "FlexKomIsMotorola" SG_ 685 CBC_AUX2_Type 1;
BA_ "GenSigSNA" SG_ 685 CBC_AUX2_Type "0h";
BA_ "GenSigSendType" SG_ 685 CBC_AUX3_Type 5;
BA_ "GenSigCycleTime" SG_ 685 CBC_AUX3_Type 1000;
BA_ "FlexKomSigStartValue" SG_ 685 CBC_AUX3_Type "0080AFAAAAAAAAAAh";
BA_ "GenSigTimeout_IC" SG_ 685 CBC_AUX3_Type 10500;
BA_ "FlexKomSID" SG_ 685 CBC_AUX3_Type 1957;
BA_ "FlexKomSigStartPos" SG_ 685 CBC_AUX3_Type 7;
BA_ "FlexKomSigLaenge" SG_ 685 CBC_AUX3_Type 64;
BA_ "FlexKomSigName" SG_ 685 CBC_AUX3_Type "CBC_Cfg2_Pkt";
BA_ "FlexKomComment" SG_ 685 CBC_AUX3_Type "Configuration status CBC 2";
BA_ "FlexKomIsMotorola" SG_ 685 CBC_AUX3_Type 1;
BA_ "GenSigSNA" SG_ 685 CBC_AUX3_Type "0h";
BA_ "GenSigSendType" SG_ 685 CBC_AUX4_Type 5;
BA_ "GenSigCycleTime" SG_ 685 CBC_AUX4_Type 1000;
BA_ "FlexKomSigStartValue" SG_ 685 CBC_AUX4_Type "0080AFAAAAAAAAAAh";
BA_ "GenSigTimeout_IC" SG_ 685 CBC_AUX4_Type 10500;
BA_ "FlexKomSID" SG_ 685 CBC_AUX4_Type 1957;
BA_ "FlexKomSigStartPos" SG_ 685 CBC_AUX4_Type 7;
BA_ "FlexKomSigLaenge" SG_ 685 CBC_AUX4_Type 64;
BA_ "FlexKomSigName" SG_ 685 CBC_AUX4_Type "CBC_Cfg2_Pkt";
BA_ "FlexKomComment" SG_ 685 CBC_AUX4_Type "Configuration status CBC 2";
BA_ "FlexKomIsMotorola" SG_ 685 CBC_AUX4_Type 1;
BA_ "GenSigSNA" SG_ 685 CBC_AUX4_Type "0h";
BA_ "GenSigSendType" SG_ 685 CBC_AUX5_Type 5;
BA_ "GenSigCycleTime" SG_ 685 CBC_AUX5_Type 1000;
BA_ "FlexKomSigStartValue" SG_ 685 CBC_AUX5_Type "0080AFAAAAAAAAAAh";
BA_ "GenSigTimeout_IC" SG_ 685 CBC_AUX5_Type 10500;
BA_ "FlexKomSID" SG_ 685 CBC_AUX5_Type 1957;
BA_ "FlexKomSigStartPos" SG_ 685 CBC_AUX5_Type 7;
BA_ "FlexKomSigLaenge" SG_ 685 CBC_AUX5_Type 64;
BA_ "FlexKomSigName" SG_ 685 CBC_AUX5_Type "CBC_Cfg2_Pkt";
BA_ "FlexKomComment" SG_ 685 CBC_AUX5_Type "Configuration status CBC 2";
BA_ "FlexKomIsMotorola" SG_ 685 CBC_AUX5_Type 1;
BA_ "GenSigSNA" SG_ 685 CBC_AUX5_Type "0h";
BA_ "GenSigSendType" SG_ 685 CBC_AUX1_PWRMD 5;
BA_ "GenSigCycleTime" SG_ 685 CBC_AUX1_PWRMD 1000;
BA_ "FlexKomSigStartValue" SG_ 685 CBC_AUX1_PWRMD "0080AFAAAAAAAAAAh";
BA_ "GenSigTimeout_IC" SG_ 685 CBC_AUX1_PWRMD 10500;
BA_ "FlexKomSID" SG_ 685 CBC_AUX1_PWRMD 1957;
BA_ "FlexKomSigStartPos" SG_ 685 CBC_AUX1_PWRMD 7;
BA_ "FlexKomSigLaenge" SG_ 685 CBC_AUX1_PWRMD 64;
BA_ "FlexKomSigName" SG_ 685 CBC_AUX1_PWRMD "CBC_Cfg2_Pkt";
BA_ "FlexKomComment" SG_ 685 CBC_AUX1_PWRMD "Configuration status CBC 2";
BA_ "FlexKomIsMotorola" SG_ 685 CBC_AUX1_PWRMD 1;
BA_ "GenSigSNA" SG_ 685 CBC_AUX1_PWRMD "0h";
BA_ "GenSigSendType" SG_ 685 CBC_AUX2_PWRMD 5;
BA_ "GenSigCycleTime" SG_ 685 CBC_AUX2_PWRMD 1000;
BA_ "FlexKomSigStartValue" SG_ 685 CBC_AUX2_PWRMD "0080AFAAAAAAAAAAh";
BA_ "GenSigTimeout_IC" SG_ 685 CBC_AUX2_PWRMD 10500;
BA_ "FlexKomSID" SG_ 685 CBC_AUX2_PWRMD 1957;
BA_ "FlexKomSigStartPos" SG_ 685 CBC_AUX2_PWRMD 7;
BA_ "FlexKomSigLaenge" SG_ 685 CBC_AUX2_PWRMD 64;
BA_ "FlexKomSigName" SG_ 685 CBC_AUX2_PWRMD "CBC_Cfg2_Pkt";
BA_ "FlexKomComment" SG_ 685 CBC_AUX2_PWRMD "Configuration status CBC 2";
BA_ "FlexKomIsMotorola" SG_ 685 CBC_AUX2_PWRMD 1;
BA_ "GenSigSNA" SG_ 685 CBC_AUX2_PWRMD "0h";
BA_ "GenSigSendType" SG_ 685 CBC_AUX3_PWRMD 5;
BA_ "GenSigCycleTime" SG_ 685 CBC_AUX3_PWRMD 1000;
BA_ "FlexKomSigStartValue" SG_ 685 CBC_AUX3_PWRMD "0080AFAAAAAAAAAAh";
BA_ "GenSigTimeout_IC" SG_ 685 CBC_AUX3_PWRMD 10500;
BA_ "FlexKomSID" SG_ 685 CBC_AUX3_PWRMD 1957;
BA_ "FlexKomSigStartPos" SG_ 685 CBC_AUX3_PWRMD 7;
BA_ "FlexKomSigLaenge" SG_ 685 CBC_AUX3_PWRMD 64;
BA_ "FlexKomSigName" SG_ 685 CBC_AUX3_PWRMD "CBC_Cfg2_Pkt";
BA_ "FlexKomComment" SG_ 685 CBC_AUX3_PWRMD "Configuration status CBC 2";
BA_ "FlexKomIsMotorola" SG_ 685 CBC_AUX3_PWRMD 1;
BA_ "GenSigSNA" SG_ 685 CBC_AUX3_PWRMD "0h";
BA_ "GenSigSendType" SG_ 685 CBC_AUX4_PWRMD 5;
BA_ "GenSigCycleTime" SG_ 685 CBC_AUX4_PWRMD 1000;
BA_ "FlexKomSigStartValue" SG_ 685 CBC_AUX4_PWRMD "0080AFAAAAAAAAAAh";
BA_ "GenSigTimeout_IC" SG_ 685 CBC_AUX4_PWRMD 10500;
BA_ "FlexKomSID" SG_ 685 CBC_AUX4_PWRMD 1957;
BA_ "FlexKomSigStartPos" SG_ 685 CBC_AUX4_PWRMD 7;
BA_ "FlexKomSigLaenge" SG_ 685 CBC_AUX4_PWRMD 64;
BA_ "FlexKomSigName" SG_ 685 CBC_AUX4_PWRMD "CBC_Cfg2_Pkt";
BA_ "FlexKomComment" SG_ 685 CBC_AUX4_PWRMD "Configuration status CBC 2";
BA_ "FlexKomIsMotorola" SG_ 685 CBC_AUX4_PWRMD 1;
BA_ "GenSigSNA" SG_ 685 CBC_AUX4_PWRMD "0h";
BA_ "GenSigSendType" SG_ 685 CBC_AUX5_PWRMD 5;
BA_ "GenSigCycleTime" SG_ 685 CBC_AUX5_PWRMD 1000;
BA_ "FlexKomSigStartValue" SG_ 685 CBC_AUX5_PWRMD "0080AFAAAAAAAAAAh";
BA_ "GenSigTimeout_IC" SG_ 685 CBC_AUX5_PWRMD 10500;
BA_ "FlexKomSID" SG_ 685 CBC_AUX5_PWRMD 1957;
BA_ "FlexKomSigStartPos" SG_ 685 CBC_AUX5_PWRMD 7;
BA_ "FlexKomSigLaenge" SG_ 685 CBC_AUX5_PWRMD 64;
BA_ "FlexKomSigName" SG_ 685 CBC_AUX5_PWRMD "CBC_Cfg2_Pkt";
BA_ "FlexKomComment" SG_ 685 CBC_AUX5_PWRMD "Configuration status CBC 2";
BA_ "FlexKomIsMotorola" SG_ 685 CBC_AUX5_PWRMD 1;
BA_ "GenSigSNA" SG_ 685 CBC_AUX5_PWRMD "0h";
BA_ "GenSigSendType" SG_ 685 CBC_AUX1_HLEnbl 5;
BA_ "GenSigCycleTime" SG_ 685 CBC_AUX1_HLEnbl 1000;
BA_ "FlexKomSigStartValue" SG_ 685 CBC_AUX1_HLEnbl "0080AFAAAAAAAAAAh";
BA_ "GenSigTimeout_IC" SG_ 685 CBC_AUX1_HLEnbl 10500;
BA_ "FlexKomSID" SG_ 685 CBC_AUX1_HLEnbl 1957;
BA_ "FlexKomSigStartPos" SG_ 685 CBC_AUX1_HLEnbl 7;
BA_ "FlexKomSigLaenge" SG_ 685 CBC_AUX1_HLEnbl 64;
BA_ "FlexKomSigName" SG_ 685 CBC_AUX1_HLEnbl "CBC_Cfg2_Pkt";
BA_ "FlexKomComment" SG_ 685 CBC_AUX1_HLEnbl "Configuration status CBC 2";
BA_ "FlexKomIsMotorola" SG_ 685 CBC_AUX1_HLEnbl 1;
BA_ "GenSigSNA" SG_ 685 CBC_AUX1_HLEnbl "0h";
BA_ "GenSigSendType" SG_ 685 CBC_AUX2_HLEnbl 5;
BA_ "GenSigCycleTime" SG_ 685 CBC_AUX2_HLEnbl 1000;
BA_ "FlexKomSigStartValue" SG_ 685 CBC_AUX2_HLEnbl "0080AFAAAAAAAAAAh";
BA_ "GenSigTimeout_IC" SG_ 685 CBC_AUX2_HLEnbl 10500;
BA_ "FlexKomSID" SG_ 685 CBC_AUX2_HLEnbl 1957;
BA_ "FlexKomSigStartPos" SG_ 685 CBC_AUX2_HLEnbl 7;
BA_ "FlexKomSigLaenge" SG_ 685 CBC_AUX2_HLEnbl 64;
BA_ "FlexKomSigName" SG_ 685 CBC_AUX2_HLEnbl "CBC_Cfg2_Pkt";
BA_ "FlexKomComment" SG_ 685 CBC_AUX2_HLEnbl "Configuration status CBC 2";
BA_ "FlexKomIsMotorola" SG_ 685 CBC_AUX2_HLEnbl 1;
BA_ "GenSigSNA" SG_ 685 CBC_AUX2_HLEnbl "0h";
BA_ "GenSigSendType" SG_ 685 CBC_AUX3_HLEnbl 5;
BA_ "GenSigCycleTime" SG_ 685 CBC_AUX3_HLEnbl 1000;
BA_ "FlexKomSigStartValue" SG_ 685 CBC_AUX3_HLEnbl "0080AFAAAAAAAAAAh";
BA_ "GenSigTimeout_IC" SG_ 685 CBC_AUX3_HLEnbl 10500;
BA_ "FlexKomSID" SG_ 685 CBC_AUX3_HLEnbl 1957;
BA_ "FlexKomSigStartPos" SG_ 685 CBC_AUX3_HLEnbl 7;
BA_ "FlexKomSigLaenge" SG_ 685 CBC_AUX3_HLEnbl 64;
BA_ "FlexKomSigName" SG_ 685 CBC_AUX3_HLEnbl "CBC_Cfg2_Pkt";
BA_ "FlexKomComment" SG_ 685 CBC_AUX3_HLEnbl "Configuration status CBC 2";
BA_ "FlexKomIsMotorola" SG_ 685 CBC_AUX3_HLEnbl 1;
BA_ "GenSigSNA" SG_ 685 CBC_AUX3_HLEnbl "0h";
BA_ "GenSigSendType" SG_ 685 CBC_AUX4_HLEnbl 5;
BA_ "GenSigCycleTime" SG_ 685 CBC_AUX4_HLEnbl 1000;
BA_ "FlexKomSigStartValue" SG_ 685 CBC_AUX4_HLEnbl "0080AFAAAAAAAAAAh";
BA_ "GenSigTimeout_IC" SG_ 685 CBC_AUX4_HLEnbl 10500;
BA_ "FlexKomSID" SG_ 685 CBC_AUX4_HLEnbl 1957;
BA_ "FlexKomSigStartPos" SG_ 685 CBC_AUX4_HLEnbl 7;
BA_ "FlexKomSigLaenge" SG_ 685 CBC_AUX4_HLEnbl 64;
BA_ "FlexKomSigName" SG_ 685 CBC_AUX4_HLEnbl "CBC_Cfg2_Pkt";
BA_ "FlexKomComment" SG_ 685 CBC_AUX4_HLEnbl "Configuration status CBC 2";
BA_ "FlexKomIsMotorola" SG_ 685 CBC_AUX4_HLEnbl 1;
BA_ "GenSigSNA" SG_ 685 CBC_AUX4_HLEnbl "0h";
BA_ "GenSigSendType" SG_ 685 CBC_AUX5_HLEnbl 5;
BA_ "GenSigCycleTime" SG_ 685 CBC_AUX5_HLEnbl 1000;
BA_ "FlexKomSigStartValue" SG_ 685 CBC_AUX5_HLEnbl "0080AFAAAAAAAAAAh";
BA_ "GenSigTimeout_IC" SG_ 685 CBC_AUX5_HLEnbl 10500;
BA_ "FlexKomSID" SG_ 685 CBC_AUX5_HLEnbl 1957;
BA_ "FlexKomSigStartPos" SG_ 685 CBC_AUX5_HLEnbl 7;
BA_ "FlexKomSigLaenge" SG_ 685 CBC_AUX5_HLEnbl 64;
BA_ "FlexKomSigName" SG_ 685 CBC_AUX5_HLEnbl "CBC_Cfg2_Pkt";
BA_ "FlexKomComment" SG_ 685 CBC_AUX5_HLEnbl "Configuration status CBC 2";
BA_ "FlexKomIsMotorola" SG_ 685 CBC_AUX5_HLEnbl 1;
BA_ "GenSigSNA" SG_ 685 CBC_AUX5_HLEnbl "0h";
BA_ "GenSigSendType" SG_ 685 Cfg_Aux_PTO 5;
BA_ "GenSigCycleTime" SG_ 685 Cfg_Aux_PTO 1000;
BA_ "FlexKomSigStartValue" SG_ 685 Cfg_Aux_PTO "0080AFAAAAAAAAAAh";
BA_ "GenSigStartValue" SG_ 685 Cfg_Aux_PTO 7;
BA_ "GenSigTimeout_IC" SG_ 685 Cfg_Aux_PTO 10500;
BA_ "FlexKomSID" SG_ 685 Cfg_Aux_PTO 1957;
BA_ "FlexKomSigStartPos" SG_ 685 Cfg_Aux_PTO 7;
BA_ "FlexKomSigLaenge" SG_ 685 Cfg_Aux_PTO 64;
BA_ "FlexKomSigName" SG_ 685 Cfg_Aux_PTO "CBC_Cfg2_Pkt";
BA_ "FlexKomComment" SG_ 685 Cfg_Aux_PTO "Configuration status CBC 2";
BA_ "FlexKomIsMotorola" SG_ 685 Cfg_Aux_PTO 1;
BA_ "GenSigSNA" SG_ 685 Cfg_Aux_PTO "7h";
BA_ "GenSigSendType" SG_ 687 SelTrlrNum 5;
BA_ "GenSigCycleTime" SG_ 687 SelTrlrNum 1000;
BA_ "FlexKomSigStartValue" SG_ 687 SelTrlrNum "09h";
BA_ "GenSigStartValue" SG_ 687 SelTrlrNum 1;
BA_ "GenSigTimeout_CBC" SG_ 687 SelTrlrNum 10500;
BA_ "GenSigTimeout_IC" SG_ 687 SelTrlrNum 10500;
BA_ "FlexKomSID" SG_ 687 SelTrlrNum 1828;
BA_ "FlexKomSigStartPos" SG_ 687 SelTrlrNum 7;
BA_ "FlexKomSigLaenge" SG_ 687 SelTrlrNum 8;
BA_ "FlexKomSigName" SG_ 687 SelTrlrNum "ITBM_Config";
BA_ "FlexKomComment" SG_ 687 SelTrlrNum "ITBM trailer configuration packet";
BA_ "FlexKomIsMotorola" SG_ 687 SelTrlrNum 1;
BA_ "GenSigSNA" SG_ 687 SelTrlrNum "7h";
BA_ "GenSigSendType" SG_ 687 SelTrlrStyle 5;
BA_ "GenSigCycleTime" SG_ 687 SelTrlrStyle 1000;
BA_ "FlexKomSigStartValue" SG_ 687 SelTrlrStyle "09h";
BA_ "GenSigStartValue" SG_ 687 SelTrlrStyle 1;
BA_ "GenSigTimeout_CBC" SG_ 687 SelTrlrStyle 10500;
BA_ "GenSigTimeout_IC" SG_ 687 SelTrlrStyle 10500;
BA_ "FlexKomSID" SG_ 687 SelTrlrStyle 1828;
BA_ "FlexKomSigStartPos" SG_ 687 SelTrlrStyle 7;
BA_ "FlexKomSigLaenge" SG_ 687 SelTrlrStyle 8;
BA_ "FlexKomSigName" SG_ 687 SelTrlrStyle "ITBM_Config";
BA_ "FlexKomComment" SG_ 687 SelTrlrStyle "ITBM trailer configuration packet";
BA_ "FlexKomIsMotorola" SG_ 687 SelTrlrStyle 1;
BA_ "GenSigSNA" SG_ 687 SelTrlrStyle "1Fh";
BA_ "GenSigSendType" SG_ 687 TrlrTripDist 5;
BA_ "GenSigCycleTime" SG_ 687 TrlrTripDist 1000;
BA_ "FlexKomSigStartValue" SG_ 687 TrlrTripDist "FFFFFFh";
BA_ "GenSigStartValue" SG_ 687 TrlrTripDist 16777215;
BA_ "GenSigTimeout_CBC" SG_ 687 TrlrTripDist 10500;
BA_ "GenSigTimeout_IC" SG_ 687 TrlrTripDist 10500;
BA_ "FlexKomSID" SG_ 687 TrlrTripDist 1827;
BA_ "FlexKomSigStartPos" SG_ 687 TrlrTripDist 15;
BA_ "FlexKomSigLaenge" SG_ 687 TrlrTripDist 24;
BA_ "FlexKomSigName" SG_ 687 TrlrTripDist "TrlrTripDist";
BA_ "FlexKomComment" SG_ 687 TrlrTripDist "Trip distance of the curent Trailer";
BA_ "FlexKomIsMotorola" SG_ 687 TrlrTripDist 1;
BA_ "GenSigSNA" SG_ 687 TrlrTripDist "FFFFFFh";
BA_ "GenSigSendType" SG_ 687 TrlrStyle_1 5;
BA_ "GenSigCycleTime" SG_ 687 TrlrStyle_1 1000;
BA_ "FlexKomSigStartValue" SG_ 687 TrlrStyle_1 "01h";
BA_ "GenSigStartValue" SG_ 687 TrlrStyle_1 1;
BA_ "GenSigTimeout_CBC" SG_ 687 TrlrStyle_1 10500;
BA_ "GenSigTimeout_IC" SG_ 687 TrlrStyle_1 10500;
BA_ "FlexKomSID" SG_ 687 TrlrStyle_1 1925;
BA_ "FlexKomSigStartPos" SG_ 687 TrlrStyle_1 36;
BA_ "FlexKomSigLaenge" SG_ 687 TrlrStyle_1 5;
BA_ "FlexKomSigName" SG_ 687 TrlrStyle_1 "TrlrStyle_1";
BA_ "FlexKomComment" SG_ 687 TrlrStyle_1 "Trailer 1 style";
BA_ "FlexKomIsMotorola" SG_ 687 TrlrStyle_1 1;
BA_ "GenSigSNA" SG_ 687 TrlrStyle_1 "1Fh";
BA_ "GenSigSendType" SG_ 687 TrlrStyle_2 5;
BA_ "GenSigCycleTime" SG_ 687 TrlrStyle_2 1000;
BA_ "FlexKomSigStartValue" SG_ 687 TrlrStyle_2 "01h";
BA_ "GenSigStartValue" SG_ 687 TrlrStyle_2 1;
BA_ "GenSigTimeout_CBC" SG_ 687 TrlrStyle_2 10500;
BA_ "GenSigTimeout_IC" SG_ 687 TrlrStyle_2 10500;
BA_ "FlexKomSID" SG_ 687 TrlrStyle_2 1928;
BA_ "FlexKomSigStartPos" SG_ 687 TrlrStyle_2 44;
BA_ "FlexKomSigLaenge" SG_ 687 TrlrStyle_2 5;
BA_ "FlexKomSigName" SG_ 687 TrlrStyle_2 "TrlrStyle_2";
BA_ "FlexKomComment" SG_ 687 TrlrStyle_2 "Trailer 2 style";
BA_ "FlexKomIsMotorola" SG_ 687 TrlrStyle_2 1;
BA_ "GenSigSNA" SG_ 687 TrlrStyle_2 "1Fh";
BA_ "GenSigSendType" SG_ 687 TrlrStyle_3 5;
BA_ "GenSigCycleTime" SG_ 687 TrlrStyle_3 1000;
BA_ "FlexKomSigStartValue" SG_ 687 TrlrStyle_3 "01h";
BA_ "GenSigStartValue" SG_ 687 TrlrStyle_3 1;
BA_ "GenSigTimeout_CBC" SG_ 687 TrlrStyle_3 10500;
BA_ "GenSigTimeout_IC" SG_ 687 TrlrStyle_3 10500;
BA_ "FlexKomSID" SG_ 687 TrlrStyle_3 1927;
BA_ "FlexKomSigStartPos" SG_ 687 TrlrStyle_3 52;
BA_ "FlexKomSigLaenge" SG_ 687 TrlrStyle_3 5;
BA_ "FlexKomSigName" SG_ 687 TrlrStyle_3 "TrlrStyle_3";
BA_ "FlexKomComment" SG_ 687 TrlrStyle_3 "Trailer 3 style";
BA_ "FlexKomIsMotorola" SG_ 687 TrlrStyle_3 1;
BA_ "GenSigSNA" SG_ 687 TrlrStyle_3 "1Fh";
BA_ "GenSigSendType" SG_ 687 TrlrStyle_4 5;
BA_ "GenSigCycleTime" SG_ 687 TrlrStyle_4 1000;
BA_ "FlexKomSigStartValue" SG_ 687 TrlrStyle_4 "01h";
BA_ "GenSigStartValue" SG_ 687 TrlrStyle_4 1;
BA_ "GenSigTimeout_CBC" SG_ 687 TrlrStyle_4 10500;
BA_ "GenSigTimeout_IC" SG_ 687 TrlrStyle_4 10500;
BA_ "FlexKomSID" SG_ 687 TrlrStyle_4 1926;
BA_ "FlexKomSigStartPos" SG_ 687 TrlrStyle_4 60;
BA_ "FlexKomSigLaenge" SG_ 687 TrlrStyle_4 5;
BA_ "FlexKomSigName" SG_ 687 TrlrStyle_4 "TrlrStyle_4";
BA_ "FlexKomComment" SG_ 687 TrlrStyle_4 "Trailer 4 style";
BA_ "FlexKomIsMotorola" SG_ 687 TrlrStyle_4 1;
BA_ "GenSigSNA" SG_ 687 TrlrStyle_4 "1Fh";
BA_ "GenSigSendType" SG_ 688 EPPM_FAULT 5;
BA_ "GenSigCycleTime" SG_ 688 EPPM_FAULT 1000;
BA_ "FlexKomSigStartValue" SG_ 688 EPPM_FAULT "00h";
BA_ "GenSigTimeout_IC" SG_ 688 EPPM_FAULT 10500;
BA_ "GenSigTimeout_ORC" SG_ 688 EPPM_FAULT 3500;
BA_ "FlexKomSID" SG_ 688 EPPM_FAULT 1339;
BA_ "FlexKomSigLaenge" SG_ 688 EPPM_FAULT 1;
BA_ "FlexKomSigName" SG_ 688 EPPM_FAULT "EPPM_FAULT";
BA_ "FlexKomComment" SG_ 688 EPPM_FAULT "Pedestrian protection module fault; True = [1]";
BA_ "FlexKomIsMotorola" SG_ 688 EPPM_FAULT 1;
BA_ "GenSigSNA" SG_ 688 EPPM_FAULT "0h";
BA_ "GenSigSendType" SG_ 688 EPPM_Stat 5;
BA_ "GenSigCycleTime" SG_ 688 EPPM_Stat 1000;
BA_ "FlexKomSigStartValue" SG_ 688 EPPM_Stat "00h";
BA_ "GenSigTimeout_ORC" SG_ 688 EPPM_Stat 3500;
BA_ "FlexKomSID" SG_ 688 EPPM_Stat 1338;
BA_ "FlexKomSigStartPos" SG_ 688 EPPM_Stat 2;
BA_ "FlexKomSigLaenge" SG_ 688 EPPM_Stat 2;
BA_ "FlexKomSigName" SG_ 688 EPPM_Stat "EPPM_Stat";
BA_ "FlexKomComment" SG_ 688 EPPM_Stat "Pedestrian protection module status";
BA_ "FlexKomIsMotorola" SG_ 688 EPPM_Stat 1;
BA_ "GenSigSNA" SG_ 688 EPPM_Stat "3h";
BA_ "GenSigSendType" SG_ 698 UConnReq 8;
BA_ "GenSigCycleTimeActive" SG_ 698 UConnReq 100;
BA_ "FlexKomSigStartValue" SG_ 698 UConnReq "00000000h";
BA_ "FlexKomSID" SG_ 698 UConnReq 1772;
BA_ "FlexKomSigStartPos" SG_ 698 UConnReq 7;
BA_ "FlexKomSigLaenge" SG_ 698 UConnReq 32;
BA_ "FlexKomSigName" SG_ 698 UConnReq "Uconnect_1_Pkt";
BA_ "FlexKomComment" SG_ 698 UConnReq "Uconnect_1_Pkt";
BA_ "FlexKomIsMotorola" SG_ 698 UConnReq 1;
BA_ "GenSigSNA" SG_ 698 UConnReq "1Fh";
BA_ "GenSigSendType" SG_ 698 UConnReqAuthCode 8;
BA_ "GenSigCycleTimeActive" SG_ 698 UConnReqAuthCode 100;
BA_ "FlexKomSigStartValue" SG_ 698 UConnReqAuthCode "00000000h";
BA_ "FlexKomSID" SG_ 698 UConnReqAuthCode 1772;
BA_ "FlexKomSigStartPos" SG_ 698 UConnReqAuthCode 7;
BA_ "FlexKomSigLaenge" SG_ 698 UConnReqAuthCode 32;
BA_ "FlexKomSigName" SG_ 698 UConnReqAuthCode "Uconnect_1_Pkt";
BA_ "FlexKomComment" SG_ 698 UConnReqAuthCode "Uconnect_1_Pkt";
BA_ "FlexKomIsMotorola" SG_ 698 UConnReqAuthCode 1;
BA_ "GenSigSNA" SG_ 698 UConnReqAuthCode "FFFFh";
BA_ "GenSigSendType" SG_ 698 UConnReqFOBNum 8;
BA_ "GenSigCycleTimeActive" SG_ 698 UConnReqFOBNum 100;
BA_ "FlexKomSigStartValue" SG_ 698 UConnReqFOBNum "00000000h";
BA_ "FlexKomSID" SG_ 698 UConnReqFOBNum 1772;
BA_ "FlexKomSigStartPos" SG_ 698 UConnReqFOBNum 7;
BA_ "FlexKomSigLaenge" SG_ 698 UConnReqFOBNum 32;
BA_ "FlexKomSigName" SG_ 698 UConnReqFOBNum "Uconnect_1_Pkt";
BA_ "FlexKomComment" SG_ 698 UConnReqFOBNum "Uconnect_1_Pkt";
BA_ "FlexKomIsMotorola" SG_ 698 UConnReqFOBNum 1;
BA_ "GenSigSNA" SG_ 698 UConnReqFOBNum "Fh";
BA_ "GenSigSendType" SG_ 706 EC_ECUCfg15_Stat 5;
BA_ "GenSigCycleTime" SG_ 706 EC_ECUCfg15_Stat 2000;
BA_ "FlexKomSigStartValue" SG_ 706 EC_ECUCfg15_Stat "03h";
BA_ "GenSigStartValue" SG_ 706 EC_ECUCfg15_Stat 3;
BA_ "GenSigTimeout_ADCM" SG_ 706 EC_ECUCfg15_Stat 21000;
BA_ "FlexKomSID" SG_ 706 EC_ECUCfg15_Stat 2071;
BA_ "FlexKomSigStartPos" SG_ 706 EC_ECUCfg15_Stat 1;
BA_ "FlexKomSigLaenge" SG_ 706 EC_ECUCfg15_Stat 2;
BA_ "FlexKomSigName" SG_ 706 EC_ECUCfg15_Stat "EC_ECUCfg15_Stat";
BA_ "FlexKomComment" SG_ 706 EC_ECUCfg15_Stat "ECU Configuration messages status 15";
BA_ "FlexKomIsMotorola" SG_ 706 EC_ECUCfg15_Stat 1;
BA_ "GenSigSNA" SG_ 706 EC_ECUCfg15_Stat "3h";
BA_ "GenSigSendType" SG_ 706 EC_CBC15A 5;
BA_ "GenSigCycleTime" SG_ 706 EC_CBC15A 2000;
BA_ "FlexKomSigStartValue" SG_ 706 EC_CBC15A "000000000000h";
BA_ "FlexKomSID" SG_ 706 EC_CBC15A 2072;
BA_ "FlexKomSigStartPos" SG_ 706 EC_CBC15A 7;
BA_ "FlexKomSigLaenge" SG_ 706 EC_CBC15A 48;
BA_ "FlexKomSigName" SG_ 706 EC_CBC15A "EC_CBC15";
BA_ "FlexKomComment" SG_ 706 EC_CBC15A "CBC ecu configuration 15";
BA_ "FlexKomIsMotorola" SG_ 706 EC_CBC15A 1;
BA_ "GenSigSNA" SG_ 706 EC_CBC15A "0h";
BA_ "GenSigSendType" SG_ 706 EC_CBC15B 5;
BA_ "GenSigCycleTime" SG_ 706 EC_CBC15B 2000;
BA_ "FlexKomSigStartValue" SG_ 706 EC_CBC15B "000000000000h";
BA_ "FlexKomSID" SG_ 706 EC_CBC15B 2072;
BA_ "FlexKomSigStartPos" SG_ 706 EC_CBC15B 7;
BA_ "FlexKomSigLaenge" SG_ 706 EC_CBC15B 48;
BA_ "FlexKomSigName" SG_ 706 EC_CBC15B "EC_CBC15";
BA_ "FlexKomComment" SG_ 706 EC_CBC15B "CBC ecu configuration 15";
BA_ "FlexKomIsMotorola" SG_ 706 EC_CBC15B 1;
BA_ "GenSigSNA" SG_ 706 EC_CBC15B "0h";
BA_ "GenSigSendType" SG_ 706 EC_Suspension 5;
BA_ "GenSigCycleTime" SG_ 706 EC_Suspension 2000;
BA_ "FlexKomSigStartValue" SG_ 706 EC_Suspension "0000h";
BA_ "GenSigTimeout_ADCM" SG_ 706 EC_Suspension 21000;
BA_ "FlexKomSID" SG_ 706 EC_Suspension 891;
BA_ "FlexKomSigStartPos" SG_ 706 EC_Suspension 55;
BA_ "FlexKomSigLaenge" SG_ 706 EC_Suspension 16;
BA_ "FlexKomSigName" SG_ 706 EC_Suspension "EC_Suspension";
BA_ "FlexKomComment" SG_ 706 EC_Suspension "Suspension ecu configuration";
BA_ "FlexKomIsMotorola" SG_ 706 EC_Suspension 1;
BA_ "GenSigSNA" SG_ 706 EC_Suspension "0h";
BA_ "GenSigSendType" SG_ 707 EC_BU_ECUCfg15_Stat 1;
BA_ "FlexKomSigStartValue" SG_ 707 EC_BU_ECUCfg15_Stat "03h";
BA_ "GenSigStartValue" SG_ 707 EC_BU_ECUCfg15_Stat 3;
BA_ "FlexKomSID" SG_ 707 EC_BU_ECUCfg15_Stat 2074;
BA_ "FlexKomSigStartPos" SG_ 707 EC_BU_ECUCfg15_Stat 1;
BA_ "FlexKomSigLaenge" SG_ 707 EC_BU_ECUCfg15_Stat 2;
BA_ "FlexKomSigName" SG_ 707 EC_BU_ECUCfg15_Stat "EC_BU_ECUCfg15_Stat";
BA_ "FlexKomComment" SG_ 707 EC_BU_ECUCfg15_Stat "Backup for ECU Configuration messages status 15";
BA_ "FlexKomIsMotorola" SG_ 707 EC_BU_ECUCfg15_Stat 1;
BA_ "GenSigSNA" SG_ 707 EC_BU_ECUCfg15_Stat "3h";
BA_ "GenSigSendType" SG_ 707 EC_BU_CBC15A 1;
BA_ "FlexKomSigStartValue" SG_ 707 EC_BU_CBC15A "000000000000h";
BA_ "FlexKomSID" SG_ 707 EC_BU_CBC15A 2075;
BA_ "FlexKomSigStartPos" SG_ 707 EC_BU_CBC15A 7;
BA_ "FlexKomSigLaenge" SG_ 707 EC_BU_CBC15A 48;
BA_ "FlexKomSigName" SG_ 707 EC_BU_CBC15A "EC_BU_CBC15";
BA_ "FlexKomComment" SG_ 707 EC_BU_CBC15A "CBC ecu configuration 15";
BA_ "FlexKomIsMotorola" SG_ 707 EC_BU_CBC15A 1;
BA_ "GenSigSNA" SG_ 707 EC_BU_CBC15A "0h";
BA_ "GenSigSendType" SG_ 707 EC_BU_CBC15B 1;
BA_ "FlexKomSigStartValue" SG_ 707 EC_BU_CBC15B "000000000000h";
BA_ "FlexKomSID" SG_ 707 EC_BU_CBC15B 2075;
BA_ "FlexKomSigStartPos" SG_ 707 EC_BU_CBC15B 7;
BA_ "FlexKomSigLaenge" SG_ 707 EC_BU_CBC15B 48;
BA_ "FlexKomSigName" SG_ 707 EC_BU_CBC15B "EC_BU_CBC15";
BA_ "FlexKomComment" SG_ 707 EC_BU_CBC15B "CBC ecu configuration 15";
BA_ "FlexKomIsMotorola" SG_ 707 EC_BU_CBC15B 1;
BA_ "GenSigSNA" SG_ 707 EC_BU_CBC15B "0h";
BA_ "GenSigSendType" SG_ 707 EC_BU_Suspension 1;
BA_ "FlexKomSigStartValue" SG_ 707 EC_BU_Suspension "0000h";
BA_ "FlexKomSID" SG_ 707 EC_BU_Suspension 914;
BA_ "FlexKomSigStartPos" SG_ 707 EC_BU_Suspension 55;
BA_ "FlexKomSigLaenge" SG_ 707 EC_BU_Suspension 16;
BA_ "FlexKomSigName" SG_ 707 EC_BU_Suspension "EC_BU_Suspension";
BA_ "FlexKomComment" SG_ 707 EC_BU_Suspension "Backup for Suspension ecu configuration";
BA_ "FlexKomIsMotorola" SG_ 707 EC_BU_Suspension 1;
BA_ "GenSigSNA" SG_ 707 EC_BU_Suspension "0h";
BA_ "GenSigSendType" SG_ 719 HMICode 5;
BA_ "GenSigCycleTime" SG_ 719 HMICode 500;
BA_ "FlexKomSigStartValue" SG_ 719 HMICode "00h";
BA_ "GenSigTimeout_IC" SG_ 719 HMICode 5250;
BA_ "FlexKomSID" SG_ 719 HMICode 1919;
BA_ "FlexKomSigStartPos" SG_ 719 HMICode 7;
BA_ "FlexKomSigLaenge" SG_ 719 HMICode 8;
BA_ "FlexKomSigName" SG_ 719 HMICode "HMICode";
BA_ "FlexKomComment" SG_ 719 HMICode "HMI codes to be displayed";
BA_ "FlexKomIsMotorola" SG_ 719 HMICode 1;
BA_ "GenSigSNA" SG_ 719 HMICode "0h";
BA_ "GenSigSendType" SG_ 719 PPPASystemFault 5;
BA_ "GenSigCycleTime" SG_ 719 PPPASystemFault 500;
BA_ "FlexKomSigStartValue" SG_ 719 PPPASystemFault "00h";
BA_ "GenSigTimeout_IC" SG_ 719 PPPASystemFault 5250;
BA_ "FlexKomSID" SG_ 719 PPPASystemFault 1917;
BA_ "FlexKomSigStartPos" SG_ 719 PPPASystemFault 8;
BA_ "FlexKomSigLaenge" SG_ 719 PPPASystemFault 1;
BA_ "FlexKomSigName" SG_ 719 PPPASystemFault "PPPASystemFault";
BA_ "FlexKomComment" SG_ 719 PPPASystemFault "Indicates the fail status of PPPA; true = [1]";
BA_ "FlexKomIsMotorola" SG_ 719 PPPASystemFault 1;
BA_ "GenSigSNA" SG_ 719 PPPASystemFault "0h";
BA_ "GenSigSendType" SG_ 719 PPPAControlSts 5;
BA_ "GenSigCycleTime" SG_ 719 PPPAControlSts 500;
BA_ "FlexKomSigStartValue" SG_ 719 PPPAControlSts "00h";
BA_ "GenSigTimeout_IC" SG_ 719 PPPAControlSts 5250;
BA_ "FlexKomSID" SG_ 719 PPPAControlSts 1918;
BA_ "FlexKomSigStartPos" SG_ 719 PPPAControlSts 9;
BA_ "FlexKomSigLaenge" SG_ 719 PPPAControlSts 1;
BA_ "FlexKomSigName" SG_ 719 PPPAControlSts "PPPAControlSts";
BA_ "FlexKomComment" SG_ 719 PPPAControlSts "Indicates the active state of PPPA; active = [1]";
BA_ "FlexKomIsMotorola" SG_ 719 PPPAControlSts 1;
BA_ "GenSigSNA" SG_ 719 PPPAControlSts "0h";
BA_ "GenSigSendType" SG_ 719 PTSControlSts 5;
BA_ "GenSigCycleTime" SG_ 719 PTSControlSts 500;
BA_ "FlexKomSigStartValue" SG_ 719 PTSControlSts "00h";
BA_ "GenSigTimeout_IC" SG_ 719 PTSControlSts 5250;
BA_ "FlexKomSID" SG_ 719 PTSControlSts 1920;
BA_ "FlexKomSigStartPos" SG_ 719 PTSControlSts 11;
BA_ "FlexKomSigLaenge" SG_ 719 PTSControlSts 2;
BA_ "FlexKomSigName" SG_ 719 PTSControlSts "PTSControlSts";
BA_ "FlexKomComment" SG_ 719 PTSControlSts "Indicates the active state of the PTS";
BA_ "FlexKomIsMotorola" SG_ 719 PTSControlSts 1;
BA_ "GenSigSNA" SG_ 719 PTSControlSts "0h";
BA_ "GenSigSendType" SG_ 719 PTSSysFlt 5;
BA_ "GenSigCycleTime" SG_ 719 PTSSysFlt 500;
BA_ "FlexKomSigStartValue" SG_ 719 PTSSysFlt "00h";
BA_ "GenSigTimeout_IC" SG_ 719 PTSSysFlt 5250;
BA_ "FlexKomSID" SG_ 719 PTSSysFlt 1921;
BA_ "FlexKomSigStartPos" SG_ 719 PTSSysFlt 13;
BA_ "FlexKomSigLaenge" SG_ 719 PTSSysFlt 2;
BA_ "FlexKomSigName" SG_ 719 PTSSysFlt "PTSSysFlt";
BA_ "FlexKomComment" SG_ 719 PTSSysFlt "Indicates the fail status of the PTS";
BA_ "FlexKomIsMotorola" SG_ 719 PTSSysFlt 1;
BA_ "GenSigSNA" SG_ 719 PTSSysFlt "0h";
BA_ "GenSigSendType" SG_ 719 PPPA_ControlSts 5;
BA_ "GenSigCycleTime" SG_ 719 PPPA_ControlSts 500;
BA_ "FlexKomSigStartValue" SG_ 719 PPPA_ControlSts "00h";
BA_ "GenSigTimeout_CBC" SG_ 719 PPPA_ControlSts 5250;
BA_ "FlexKomSID" SG_ 719 PPPA_ControlSts 1922;
BA_ "FlexKomSigStartPos" SG_ 719 PPPA_ControlSts 15;
BA_ "FlexKomSigLaenge" SG_ 719 PPPA_ControlSts 2;
BA_ "FlexKomSigName" SG_ 719 PPPA_ControlSts "PPPA_ControlSts";
BA_ "FlexKomComment" SG_ 719 PPPA_ControlSts "Parallel & perpendicular park assist switch status";
BA_ "FlexKomIsMotorola" SG_ 719 PPPA_ControlSts 1;
BA_ "GenSigSNA" SG_ 719 PPPA_ControlSts "3h";
BA_ "GenSigSendType" SG_ 719 PTS_DBD 5;
BA_ "GenSigCycleTime" SG_ 719 PTS_DBD 500;
BA_ "FlexKomSigStartValue" SG_ 719 PTS_DBD "00h";
BA_ "GenSigTimeout_IC" SG_ 719 PTS_DBD 5250;
BA_ "FlexKomSID" SG_ 719 PTS_DBD 1949;
BA_ "FlexKomSigStartPos" SG_ 719 PTS_DBD 16;
BA_ "FlexKomSigLaenge" SG_ 719 PTS_DBD 1;
BA_ "FlexKomSigName" SG_ 719 PTS_DBD "PTS_DBD";
BA_ "FlexKomComment" SG_ 719 PTS_DBD "Park assist system disabled; System_Disabled = [1]";
BA_ "FlexKomIsMotorola" SG_ 719 PTS_DBD 1;
BA_ "GenSigSNA" SG_ 719 PTS_DBD "0h";
BA_ "GenSigSendType" SG_ 720 BSM_LT_WRN 5;
BA_ "GenSigCycleTime" SG_ 720 BSM_LT_WRN 500;
BA_ "FlexKomSigStartValue" SG_ 720 BSM_LT_WRN "00h";
BA_ "GenSigTimeout_IC" SG_ 720 BSM_LT_WRN 5250;
BA_ "FlexKomSID" SG_ 720 BSM_LT_WRN 9;
BA_ "FlexKomSigStartPos" SG_ 720 BSM_LT_WRN 5;
BA_ "FlexKomSigLaenge" SG_ 720 BSM_LT_WRN 6;
BA_ "FlexKomSigName" SG_ 720 BSM_LT_WRN "BSM_WRN";
BA_ "FlexKomComment" SG_ 720 BSM_LT_WRN "Blind spot detection warning status";
BA_ "FlexKomIsMotorola" SG_ 720 BSM_LT_WRN 1;
BA_ "GenSigSNA" SG_ 720 BSM_LT_WRN "7h";
BA_ "GenSigSendType" SG_ 720 BSM_RT_WRN 5;
BA_ "GenSigCycleTime" SG_ 720 BSM_RT_WRN 500;
BA_ "FlexKomSigStartValue" SG_ 720 BSM_RT_WRN "00h";
BA_ "GenSigTimeout_IC" SG_ 720 BSM_RT_WRN 5250;
BA_ "FlexKomSID" SG_ 720 BSM_RT_WRN 9;
BA_ "FlexKomSigStartPos" SG_ 720 BSM_RT_WRN 5;
BA_ "FlexKomSigLaenge" SG_ 720 BSM_RT_WRN 6;
BA_ "FlexKomSigName" SG_ 720 BSM_RT_WRN "BSM_WRN";
BA_ "FlexKomComment" SG_ 720 BSM_RT_WRN "Blind spot detection warning status";
BA_ "FlexKomIsMotorola" SG_ 720 BSM_RT_WRN 1;
BA_ "GenSigSNA" SG_ 720 BSM_RT_WRN "7h";
BA_ "GenSigSendType" SG_ 720 BSM_ChmRq 5;
BA_ "GenSigCycleTime" SG_ 720 BSM_ChmRq 500;
BA_ "FlexKomSigStartValue" SG_ 720 BSM_ChmRq "00h";
BA_ "GenSigTimeout_IC" SG_ 720 BSM_ChmRq 5250;
BA_ "FlexKomSID" SG_ 720 BSM_ChmRq 5;
BA_ "FlexKomSigStartPos" SG_ 720 BSM_ChmRq 7;
BA_ "FlexKomSigLaenge" SG_ 720 BSM_ChmRq 2;
BA_ "FlexKomSigName" SG_ 720 BSM_ChmRq "BSM_ChmRq";
BA_ "FlexKomComment" SG_ 720 BSM_ChmRq "Blind spot chime request";
BA_ "FlexKomIsMotorola" SG_ 720 BSM_ChmRq 1;
BA_ "GenSigSNA" SG_ 720 BSM_ChmRq "0h";
BA_ "GenSigSendType" SG_ 720 BSM_CFG_STAT 5;
BA_ "GenSigCycleTime" SG_ 720 BSM_CFG_STAT 500;
BA_ "FlexKomSigStartValue" SG_ 720 BSM_CFG_STAT "03h";
BA_ "GenSigStartValue" SG_ 720 BSM_CFG_STAT 3;
BA_ "GenSigTimeout_IC" SG_ 720 BSM_CFG_STAT 5250;
BA_ "FlexKomSID" SG_ 720 BSM_CFG_STAT 4;
BA_ "FlexKomSigStartPos" SG_ 720 BSM_CFG_STAT 9;
BA_ "FlexKomSigLaenge" SG_ 720 BSM_CFG_STAT 2;
BA_ "FlexKomSigName" SG_ 720 BSM_CFG_STAT "BSM_CFG_STAT";
BA_ "FlexKomComment" SG_ 720 BSM_CFG_STAT "BSM configuration status";
BA_ "FlexKomIsMotorola" SG_ 720 BSM_CFG_STAT 1;
BA_ "GenSigSNA" SG_ 720 BSM_CFG_STAT "3h";
BA_ "GenSigSendType" SG_ 720 BSM_SRV_RQ 5;
BA_ "GenSigCycleTime" SG_ 720 BSM_SRV_RQ 500;
BA_ "FlexKomSigStartValue" SG_ 720 BSM_SRV_RQ "00h";
BA_ "GenSigTimeout_IC" SG_ 720 BSM_SRV_RQ 5250;
BA_ "FlexKomSID" SG_ 720 BSM_SRV_RQ 6;
BA_ "FlexKomSigStartPos" SG_ 720 BSM_SRV_RQ 10;
BA_ "FlexKomSigLaenge" SG_ 720 BSM_SRV_RQ 1;
BA_ "FlexKomSigName" SG_ 720 BSM_SRV_RQ "BSM_SRV_RQ";
BA_ "FlexKomComment" SG_ 720 BSM_SRV_RQ "BSM service warning request; 1= service request";
BA_ "FlexKomIsMotorola" SG_ 720 BSM_SRV_RQ 1;
BA_ "GenSigSNA" SG_ 720 BSM_SRV_RQ "0h";
BA_ "GenSigSendType" SG_ 720 BSM_OPR_STAT 5;
BA_ "GenSigCycleTime" SG_ 720 BSM_OPR_STAT 500;
BA_ "FlexKomSigStartValue" SG_ 720 BSM_OPR_STAT "00h";
BA_ "GenSigTimeout_IC" SG_ 720 BSM_OPR_STAT 5250;
BA_ "FlexKomSID" SG_ 720 BSM_OPR_STAT 7;
BA_ "FlexKomSigStartPos" SG_ 720 BSM_OPR_STAT 11;
BA_ "FlexKomSigLaenge" SG_ 720 BSM_OPR_STAT 1;
BA_ "FlexKomSigName" SG_ 720 BSM_OPR_STAT "BSM_OPR_STAT";
BA_ "FlexKomComment" SG_ 720 BSM_OPR_STAT "BSM operation status; 1= operational failure";
BA_ "FlexKomIsMotorola" SG_ 720 BSM_OPR_STAT 1;
BA_ "GenSigSNA" SG_ 720 BSM_OPR_STAT "0h";
BA_ "GenSigSendType" SG_ 720 BSM_MUTE_RQ 5;
BA_ "GenSigCycleTime" SG_ 720 BSM_MUTE_RQ 500;
BA_ "FlexKomSigStartValue" SG_ 720 BSM_MUTE_RQ "00h";
BA_ "FlexKomSID" SG_ 720 BSM_MUTE_RQ 8;
BA_ "FlexKomSigStartPos" SG_ 720 BSM_MUTE_RQ 12;
BA_ "FlexKomSigLaenge" SG_ 720 BSM_MUTE_RQ 1;
BA_ "FlexKomSigName" SG_ 720 BSM_MUTE_RQ "BSM_MUTE_RQ";
BA_ "FlexKomComment" SG_ 720 BSM_MUTE_RQ "Audio system mute request from BSM";
BA_ "FlexKomIsMotorola" SG_ 720 BSM_MUTE_RQ 1;
BA_ "GenSigSNA" SG_ 720 BSM_MUTE_RQ "0h";
BA_ "GenSigSendType" SG_ 720 BSM_Blind_RQ 5;
BA_ "GenSigCycleTime" SG_ 720 BSM_Blind_RQ 500;
BA_ "FlexKomSigStartValue" SG_ 720 BSM_Blind_RQ "00h";
BA_ "GenSigTimeout_IC" SG_ 720 BSM_Blind_RQ 5250;
BA_ "FlexKomSID" SG_ 720 BSM_Blind_RQ 1362;
BA_ "FlexKomSigStartPos" SG_ 720 BSM_Blind_RQ 13;
BA_ "FlexKomSigLaenge" SG_ 720 BSM_Blind_RQ 1;
BA_ "FlexKomSigName" SG_ 720 BSM_Blind_RQ "BSM_Blind_RQ";
BA_ "FlexKomComment" SG_ 720 BSM_Blind_RQ "Sensor blinded request from BSM; 1= sensor blocked";
BA_ "FlexKomIsMotorola" SG_ 720 BSM_Blind_RQ 1;
BA_ "GenSigSNA" SG_ 720 BSM_Blind_RQ "0h";
BA_ "GenSigSendType" SG_ 720 BSM_Tower_RQ 5;
BA_ "GenSigCycleTime" SG_ 720 BSM_Tower_RQ 500;
BA_ "FlexKomSigStartValue" SG_ 720 BSM_Tower_RQ "00h";
BA_ "GenSigTimeout_IC" SG_ 720 BSM_Tower_RQ 5250;
BA_ "FlexKomSID" SG_ 720 BSM_Tower_RQ 1363;
BA_ "FlexKomSigStartPos" SG_ 720 BSM_Tower_RQ 14;
BA_ "FlexKomSigLaenge" SG_ 720 BSM_Tower_RQ 1;
BA_ "FlexKomSigName" SG_ 720 BSM_Tower_RQ "BSM_Tower_RQ";
BA_ "FlexKomComment" SG_ 720 BSM_Tower_RQ "BSM unavailable in the astronomy tower zone; 1= to";
BA_ "FlexKomIsMotorola" SG_ 720 BSM_Tower_RQ 1;
BA_ "GenSigSNA" SG_ 720 BSM_Tower_RQ "0h";
BA_ "GenSigSendType" SG_ 729 StrgVibrAmplReq 5;
BA_ "GenSigCycleTime" SG_ 729 StrgVibrAmplReq 100;
BA_ "FlexKomSigStartValue" SG_ 729 StrgVibrAmplReq "000000h";
BA_ "FlexKomSID" SG_ 729 StrgVibrAmplReq 1636;
BA_ "FlexKomSigStartPos" SG_ 729 StrgVibrAmplReq 7;
BA_ "FlexKomSigLaenge" SG_ 729 StrgVibrAmplReq 24;
BA_ "FlexKomSigName" SG_ 729 StrgVibrAmplReq "HALF_SWVM_CtrlPkt";
BA_ "FlexKomComment" SG_ 729 StrgVibrAmplReq "HALF steering wheel vibration control packet";
BA_ "FlexKomIsMotorola" SG_ 729 StrgVibrAmplReq 1;
BA_ "GenSigSNA" SG_ 729 StrgVibrAmplReq "0h";
BA_ "GenSigSendType" SG_ 729 StrgVibrFreqReq 5;
BA_ "GenSigCycleTime" SG_ 729 StrgVibrFreqReq 100;
BA_ "FlexKomSigStartValue" SG_ 729 StrgVibrFreqReq "000000h";
BA_ "FlexKomSID" SG_ 729 StrgVibrFreqReq 1636;
BA_ "FlexKomSigStartPos" SG_ 729 StrgVibrFreqReq 7;
BA_ "FlexKomSigLaenge" SG_ 729 StrgVibrFreqReq 24;
BA_ "FlexKomSigName" SG_ 729 StrgVibrFreqReq "HALF_SWVM_CtrlPkt";
BA_ "FlexKomComment" SG_ 729 StrgVibrFreqReq "HALF steering wheel vibration control packet";
BA_ "FlexKomIsMotorola" SG_ 729 StrgVibrFreqReq 1;
BA_ "GenSigSNA" SG_ 729 StrgVibrFreqReq "0h";
BA_ "GenSigSendType" SG_ 729 PulseTimeOff 5;
BA_ "GenSigCycleTime" SG_ 729 PulseTimeOff 100;
BA_ "FlexKomSigStartValue" SG_ 729 PulseTimeOff "000000h";
BA_ "FlexKomSID" SG_ 729 PulseTimeOff 1636;
BA_ "FlexKomSigStartPos" SG_ 729 PulseTimeOff 7;
BA_ "FlexKomSigLaenge" SG_ 729 PulseTimeOff 24;
BA_ "FlexKomSigName" SG_ 729 PulseTimeOff "HALF_SWVM_CtrlPkt";
BA_ "FlexKomComment" SG_ 729 PulseTimeOff "HALF steering wheel vibration control packet";
BA_ "FlexKomIsMotorola" SG_ 729 PulseTimeOff 1;
BA_ "GenSigSNA" SG_ 729 PulseTimeOff "0h";
BA_ "GenSigSendType" SG_ 729 PulseTimeOn 5;
BA_ "GenSigCycleTime" SG_ 729 PulseTimeOn 100;
BA_ "FlexKomSigStartValue" SG_ 729 PulseTimeOn "000000h";
BA_ "FlexKomSID" SG_ 729 PulseTimeOn 1636;
BA_ "FlexKomSigStartPos" SG_ 729 PulseTimeOn 7;
BA_ "FlexKomSigLaenge" SG_ 729 PulseTimeOn 24;
BA_ "FlexKomSigName" SG_ 729 PulseTimeOn "HALF_SWVM_CtrlPkt";
BA_ "FlexKomComment" SG_ 729 PulseTimeOn "HALF steering wheel vibration control packet";
BA_ "FlexKomIsMotorola" SG_ 729 PulseTimeOn 1;
BA_ "GenSigSNA" SG_ 729 PulseTimeOn "0h";
BA_ "GenSigSendType" SG_ 729 StrgVibrActv 5;
BA_ "GenSigCycleTime" SG_ 729 StrgVibrActv 100;
BA_ "FlexKomSigStartValue" SG_ 729 StrgVibrActv "000000h";
BA_ "FlexKomSID" SG_ 729 StrgVibrActv 1636;
BA_ "FlexKomSigStartPos" SG_ 729 StrgVibrActv 7;
BA_ "FlexKomSigLaenge" SG_ 729 StrgVibrActv 24;
BA_ "FlexKomSigName" SG_ 729 StrgVibrActv "HALF_SWVM_CtrlPkt";
BA_ "FlexKomComment" SG_ 729 StrgVibrActv "HALF steering wheel vibration control packet";
BA_ "FlexKomIsMotorola" SG_ 729 StrgVibrActv 1;
BA_ "GenSigSNA" SG_ 729 StrgVibrActv "0h";
BA_ "GenSigSendType" SG_ 729 HALFSysSts 5;
BA_ "GenSigCycleTime" SG_ 729 HALFSysSts 100;
BA_ "FlexKomSigStartValue" SG_ 729 HALFSysSts "000000h";
BA_ "FlexKomSID" SG_ 729 HALFSysSts 1636;
BA_ "FlexKomSigStartPos" SG_ 729 HALFSysSts 7;
BA_ "FlexKomSigLaenge" SG_ 729 HALFSysSts 24;
BA_ "FlexKomSigName" SG_ 729 HALFSysSts "HALF_SWVM_CtrlPkt";
BA_ "FlexKomComment" SG_ 729 HALFSysSts "HALF steering wheel vibration control packet";
BA_ "FlexKomIsMotorola" SG_ 729 HALFSysSts 1;
BA_ "GenSigSNA" SG_ 729 HALFSysSts "0h";
BA_ "GenSigSendType" SG_ 729 HaLFCntr 5;
BA_ "GenSigCycleTime" SG_ 729 HaLFCntr 100;
BA_ "FlexKomSigStartValue" SG_ 729 HaLFCntr "000000h";
BA_ "FlexKomSID" SG_ 729 HaLFCntr 1636;
BA_ "FlexKomSigStartPos" SG_ 729 HaLFCntr 7;
BA_ "FlexKomSigLaenge" SG_ 729 HaLFCntr 24;
BA_ "FlexKomSigName" SG_ 729 HaLFCntr "HALF_SWVM_CtrlPkt";
BA_ "FlexKomComment" SG_ 729 HaLFCntr "HALF steering wheel vibration control packet";
BA_ "FlexKomIsMotorola" SG_ 729 HaLFCntr 1;
BA_ "GenSigSNA" SG_ 729 HaLFCntr "0h";
BA_ "GenSigSendType" SG_ 729 LDW_LEDControlSts 5;
BA_ "GenSigCycleTime" SG_ 729 LDW_LEDControlSts 100;
BA_ "FlexKomSigStartValue" SG_ 729 LDW_LEDControlSts "00h";
BA_ "GenSigTimeout_CBC" SG_ 729 LDW_LEDControlSts 1050;
BA_ "FlexKomSID" SG_ 729 LDW_LEDControlSts 2024;
BA_ "FlexKomSigStartPos" SG_ 729 LDW_LEDControlSts 25;
BA_ "FlexKomSigLaenge" SG_ 729 LDW_LEDControlSts 2;
BA_ "FlexKomSigName" SG_ 729 LDW_LEDControlSts "LDW_LEDControlSts";
BA_ "FlexKomComment" SG_ 729 LDW_LEDControlSts "LDW switch LED status";
BA_ "FlexKomIsMotorola" SG_ 729 LDW_LEDControlSts 1;
BA_ "GenSigSNA" SG_ 729 LDW_LEDControlSts "3h";
BA_ "GenSigSendType" SG_ 729 TorqueIntensitySts 5;
BA_ "GenSigCycleTime" SG_ 729 TorqueIntensitySts 100;
BA_ "FlexKomSigStartValue" SG_ 729 TorqueIntensitySts "00h";
BA_ "GenSigTimeout_CBC" SG_ 729 TorqueIntensitySts 1050;
BA_ "FlexKomSID" SG_ 729 TorqueIntensitySts 2025;
BA_ "FlexKomSigStartPos" SG_ 729 TorqueIntensitySts 28;
BA_ "FlexKomSigLaenge" SG_ 729 TorqueIntensitySts 3;
BA_ "FlexKomSigName" SG_ 729 TorqueIntensitySts "TorqueIntensitySts";
BA_ "FlexKomComment" SG_ 729 TorqueIntensitySts "LDW Torque Intesity Level";
BA_ "FlexKomIsMotorola" SG_ 729 TorqueIntensitySts 1;
BA_ "GenSigSNA" SG_ 729 TorqueIntensitySts "7h";
BA_ "GenSigSendType" SG_ 729 HALF_AHB_ACT 5;
BA_ "GenSigCycleTime" SG_ 729 HALF_AHB_ACT 100;
BA_ "FlexKomSigStartValue" SG_ 729 HALF_AHB_ACT "00h";
BA_ "GenSigTimeout_IC" SG_ 729 HALF_AHB_ACT 1050;
BA_ "FlexKomSID" SG_ 729 HALF_AHB_ACT 1876;
BA_ "FlexKomSigStartPos" SG_ 729 HALF_AHB_ACT 30;
BA_ "FlexKomSigLaenge" SG_ 729 HALF_AHB_ACT 1;
BA_ "FlexKomSigName" SG_ 729 HALF_AHB_ACT "HALF_AHB_ACT";
BA_ "FlexKomComment" SG_ 729 HALF_AHB_ACT "Auto high beam is active (indicates that all enabl";
BA_ "FlexKomIsMotorola" SG_ 729 HALF_AHB_ACT 1;
BA_ "GenSigSNA" SG_ 729 HALF_AHB_ACT "0h";
BA_ "GenSigSendType" SG_ 729 HALF_AHB_On 5;
BA_ "GenSigCycleTime" SG_ 729 HALF_AHB_On 100;
BA_ "FlexKomSigStartValue" SG_ 729 HALF_AHB_On "00h";
BA_ "FlexKomSID" SG_ 729 HALF_AHB_On 1877;
BA_ "FlexKomSigStartPos" SG_ 729 HALF_AHB_On 31;
BA_ "FlexKomSigLaenge" SG_ 729 HALF_AHB_On 1;
BA_ "FlexKomSigName" SG_ 729 HALF_AHB_On "HALF_AHB_On";
BA_ "FlexKomComment" SG_ 729 HALF_AHB_On "Auto high beam on request from the HALF ECU";
BA_ "FlexKomIsMotorola" SG_ 729 HALF_AHB_On 1;
BA_ "GenSigSNA" SG_ 729 HALF_AHB_On "0h";
BA_ "GenSigSendType" SG_ 729 SysAvlStat 5;
BA_ "GenSigCycleTime" SG_ 729 SysAvlStat 100;
BA_ "FlexKomSigStartValue" SG_ 729 SysAvlStat "00h";
BA_ "FlexKomSID" SG_ 729 SysAvlStat 1640;
BA_ "FlexKomSigStartPos" SG_ 729 SysAvlStat 32;
BA_ "FlexKomSigLaenge" SG_ 729 SysAvlStat 1;
BA_ "FlexKomSigName" SG_ 729 SysAvlStat "SysAvlStat";
BA_ "FlexKomComment" SG_ 729 SysAvlStat "System availability status; available = [1]";
BA_ "FlexKomIsMotorola" SG_ 729 SysAvlStat 1;
BA_ "GenSigSNA" SG_ 729 SysAvlStat "0h";
BA_ "GenSigSendType" SG_ 729 SysActv 5;
BA_ "GenSigCycleTime" SG_ 729 SysActv 100;
BA_ "FlexKomSigStartValue" SG_ 729 SysActv "00h";
BA_ "FlexKomSID" SG_ 729 SysActv 1639;
BA_ "FlexKomSigStartPos" SG_ 729 SysActv 33;
BA_ "FlexKomSigLaenge" SG_ 729 SysActv 1;
BA_ "FlexKomSigName" SG_ 729 SysActv "SysActv";
BA_ "FlexKomComment" SG_ 729 SysActv "System active";
BA_ "FlexKomIsMotorola" SG_ 729 SysActv 1;
BA_ "GenSigSNA" SG_ 729 SysActv "0h";
BA_ "GenSigSendType" SG_ 729 SysFail 5;
BA_ "GenSigCycleTime" SG_ 729 SysFail 100;
BA_ "FlexKomSigStartValue" SG_ 729 SysFail "00h";
BA_ "FlexKomSID" SG_ 729 SysFail 1641;
BA_ "FlexKomSigStartPos" SG_ 729 SysFail 34;
BA_ "FlexKomSigLaenge" SG_ 729 SysFail 1;
BA_ "FlexKomSigName" SG_ 729 SysFail "SysFail";
BA_ "FlexKomComment" SG_ 729 SysFail "System fault";
BA_ "FlexKomIsMotorola" SG_ 729 SysFail 1;
BA_ "GenSigSNA" SG_ 729 SysFail "0h";
BA_ "GenSigSendType" SG_ 729 AutoSprsActv 5;
BA_ "GenSigCycleTime" SG_ 729 AutoSprsActv 100;
BA_ "FlexKomSigStartValue" SG_ 729 AutoSprsActv "00h";
BA_ "FlexKomSID" SG_ 729 AutoSprsActv 1637;
BA_ "FlexKomSigStartPos" SG_ 729 AutoSprsActv 35;
BA_ "FlexKomSigLaenge" SG_ 729 AutoSprsActv 1;
BA_ "FlexKomSigName" SG_ 729 AutoSprsActv "AutoSprsActv";
BA_ "FlexKomComment" SG_ 729 AutoSprsActv "Automatic suppression active";
BA_ "FlexKomIsMotorola" SG_ 729 AutoSprsActv 1;
BA_ "GenSigSNA" SG_ 729 AutoSprsActv "0h";
BA_ "GenSigSendType" SG_ 729 ConfigSts 5;
BA_ "GenSigCycleTime" SG_ 729 ConfigSts 100;
BA_ "FlexKomSigStartValue" SG_ 729 ConfigSts "02h";
BA_ "GenSigStartValue" SG_ 729 ConfigSts 2;
BA_ "FlexKomSID" SG_ 729 ConfigSts 1638;
BA_ "FlexKomSigStartPos" SG_ 729 ConfigSts 38;
BA_ "FlexKomSigLaenge" SG_ 729 ConfigSts 3;
BA_ "FlexKomSigName" SG_ 729 ConfigSts "ConfigSts";
BA_ "FlexKomComment" SG_ 729 ConfigSts "Configuration status";
BA_ "FlexKomIsMotorola" SG_ 729 ConfigSts 1;
BA_ "GenSigSNA" SG_ 729 ConfigSts "7h";
BA_ "GenSigSendType" SG_ 734 RFHM_TXFR_SEL 1;
BA_ "FlexKomSigStartValue" SG_ 734 RFHM_TXFR_SEL "00000000000000h";
BA_ "FlexKomSID" SG_ 734 RFHM_TXFR_SEL 1866;
BA_ "FlexKomSigStartPos" SG_ 734 RFHM_TXFR_SEL 7;
BA_ "FlexKomSigLaenge" SG_ 734 RFHM_TXFR_SEL 56;
BA_ "FlexKomSigName" SG_ 734 RFHM_TXFR_SEL "RFHMKeyDataPkt";
BA_ "FlexKomComment" SG_ 734 RFHM_TXFR_SEL "RFHM key data packet";
BA_ "FlexKomIsMotorola" SG_ 734 RFHM_TXFR_SEL 1;
BA_ "GenSigSNA" SG_ 734 RFHM_TXFR_SEL "7h";
BA_ "GenSigSendType" SG_ 734 RFHM_KEY_DATA 1;
BA_ "FlexKomSigStartValue" SG_ 734 RFHM_KEY_DATA "00000000000000h";
BA_ "FlexKomSID" SG_ 734 RFHM_KEY_DATA 1866;
BA_ "FlexKomSigStartPos" SG_ 734 RFHM_KEY_DATA 7;
BA_ "FlexKomSigLaenge" SG_ 734 RFHM_KEY_DATA 56;
BA_ "FlexKomSigName" SG_ 734 RFHM_KEY_DATA "RFHMKeyDataPkt";
BA_ "FlexKomComment" SG_ 734 RFHM_KEY_DATA "RFHM key data packet";
BA_ "FlexKomIsMotorola" SG_ 734 RFHM_KEY_DATA 1;
BA_ "GenSigSNA" SG_ 734 RFHM_KEY_DATA "0h";
BA_ "GenSigSendType" SG_ 735 CBC_TXFR_SEL 1;
BA_ "FlexKomSigStartValue" SG_ 735 CBC_TXFR_SEL "00000000000000h";
BA_ "FlexKomSID" SG_ 735 CBC_TXFR_SEL 1867;
BA_ "FlexKomSigStartPos" SG_ 735 CBC_TXFR_SEL 7;
BA_ "FlexKomSigLaenge" SG_ 735 CBC_TXFR_SEL 56;
BA_ "FlexKomSigName" SG_ 735 CBC_TXFR_SEL "CBCKeyDataPkt";
BA_ "FlexKomComment" SG_ 735 CBC_TXFR_SEL "CBC key data packet";
BA_ "FlexKomIsMotorola" SG_ 735 CBC_TXFR_SEL 1;
BA_ "GenSigSNA" SG_ 735 CBC_TXFR_SEL "7h";
BA_ "GenSigSendType" SG_ 735 CBC_KEY_DATA 1;
BA_ "FlexKomSigStartValue" SG_ 735 CBC_KEY_DATA "00000000000000h";
BA_ "FlexKomSID" SG_ 735 CBC_KEY_DATA 1867;
BA_ "FlexKomSigStartPos" SG_ 735 CBC_KEY_DATA 7;
BA_ "FlexKomSigLaenge" SG_ 735 CBC_KEY_DATA 56;
BA_ "FlexKomSigName" SG_ 735 CBC_KEY_DATA "CBCKeyDataPkt";
BA_ "FlexKomComment" SG_ 735 CBC_KEY_DATA "CBC key data packet";
BA_ "FlexKomIsMotorola" SG_ 735 CBC_KEY_DATA 1;
BA_ "GenSigSNA" SG_ 735 CBC_KEY_DATA "0h";
BA_ "GenSigCycleTime" SG_ 736 LT_DIST 50;
BA_ "FlexKomSigStartValue" SG_ 736 LT_DIST "FFFFFFFFh";
BA_ "GenSigStartValue" SG_ 736 LT_DIST 65535;
BA_ "GenSigTimeout_CBC" SG_ 736 LT_DIST 525;
BA_ "GenSigTimeout_IC" SG_ 736 LT_DIST 525;
BA_ "GenSigTimeout_PTS" SG_ 736 LT_DIST 525;
BA_ "FlexKomSID" SG_ 736 LT_DIST 395;
BA_ "FlexKomSigStartPos" SG_ 736 LT_DIST 7;
BA_ "FlexKomSigLaenge" SG_ 736 LT_DIST 32;
BA_ "FlexKomSigName" SG_ 736 LT_DIST "ESP_DIST";
BA_ "FlexKomComment" SG_ 736 LT_DIST "Distance traveled by wheels";
BA_ "FlexKomIsMotorola" SG_ 736 LT_DIST 1;
BA_ "GenSigSNA" SG_ 736 LT_DIST "FFFFh";
BA_ "GenSigCycleTime" SG_ 736 RT_DIST 50;
BA_ "FlexKomSigStartValue" SG_ 736 RT_DIST "FFFFFFFFh";
BA_ "GenSigStartValue" SG_ 736 RT_DIST 65535;
BA_ "GenSigTimeout_CBC" SG_ 736 RT_DIST 525;
BA_ "GenSigTimeout_IC" SG_ 736 RT_DIST 525;
BA_ "GenSigTimeout_PTS" SG_ 736 RT_DIST 525;
BA_ "FlexKomSID" SG_ 736 RT_DIST 395;
BA_ "FlexKomSigStartPos" SG_ 736 RT_DIST 7;
BA_ "FlexKomSigLaenge" SG_ 736 RT_DIST 32;
BA_ "FlexKomSigName" SG_ 736 RT_DIST "ESP_DIST";
BA_ "FlexKomComment" SG_ 736 RT_DIST "Distance traveled by wheels";
BA_ "FlexKomIsMotorola" SG_ 736 RT_DIST 1;
BA_ "GenSigSNA" SG_ 736 RT_DIST "FFFFh";
BA_ "GenSigCycleTime" SG_ 736 YRS_DataRq 50;
BA_ "FlexKomSigStartValue" SG_ 736 YRS_DataRq "00h";
BA_ "FlexKomSID" SG_ 736 YRS_DataRq 1589;
BA_ "FlexKomSigStartPos" SG_ 736 YRS_DataRq 32;
BA_ "FlexKomSigLaenge" SG_ 736 YRS_DataRq 1;
BA_ "FlexKomSigName" SG_ 736 YRS_DataRq "YRS_DataRq";
BA_ "FlexKomComment" SG_ 736 YRS_DataRq "Request from ESC for YRS information";
BA_ "FlexKomIsMotorola" SG_ 736 YRS_DataRq 1;
BA_ "GenSigSNA" SG_ 736 YRS_DataRq "0h";
BA_ "GenSigCycleTime" SG_ 736 SPCR_Warn_V2 50;
BA_ "FlexKomSigStartValue" SG_ 736 SPCR_Warn_V2 "00h";
BA_ "GenSigTimeout_IC" SG_ 736 SPCR_Warn_V2 525;
BA_ "FlexKomSID" SG_ 736 SPCR_Warn_V2 1005;
BA_ "FlexKomSigStartPos" SG_ 736 SPCR_Warn_V2 35;
BA_ "FlexKomSigLaenge" SG_ 736 SPCR_Warn_V2 3;
BA_ "FlexKomSigName" SG_ 736 SPCR_Warn_V2 "SPCR_Warn_V2";
BA_ "FlexKomComment" SG_ 736 SPCR_Warn_V2 "Stop coordinator warning if driver exits vehicle";
BA_ "FlexKomIsMotorola" SG_ 736 SPCR_Warn_V2 1;
BA_ "GenSigSNA" SG_ 736 SPCR_Warn_V2 "7h";
BA_ "GenSigCycleTime" SG_ 736 HDC_SUPP 50;
BA_ "FlexKomSigStartValue" SG_ 736 HDC_SUPP "00h";
BA_ "FlexKomSID" SG_ 736 HDC_SUPP 396;
BA_ "FlexKomSigStartPos" SG_ 736 HDC_SUPP 47;
BA_ "FlexKomSigLaenge" SG_ 736 HDC_SUPP 8;
BA_ "FlexKomSigName" SG_ 736 HDC_SUPP "EBC_Feature_Status";
BA_ "FlexKomComment" SG_ 736 HDC_SUPP "ESP feature present and enabled";
BA_ "FlexKomIsMotorola" SG_ 736 HDC_SUPP 1;
BA_ "GenSigSNA" SG_ 736 HDC_SUPP "0h";
BA_ "GenSigCycleTime" SG_ 736 HDC_EN 50;
BA_ "FlexKomSigStartValue" SG_ 736 HDC_EN "00h";
BA_ "FlexKomSID" SG_ 736 HDC_EN 396;
BA_ "FlexKomSigStartPos" SG_ 736 HDC_EN 47;
BA_ "FlexKomSigLaenge" SG_ 736 HDC_EN 8;
BA_ "FlexKomSigName" SG_ 736 HDC_EN "EBC_Feature_Status";
BA_ "FlexKomComment" SG_ 736 HDC_EN "ESP feature present and enabled";
BA_ "FlexKomIsMotorola" SG_ 736 HDC_EN 1;
BA_ "GenSigSNA" SG_ 736 HDC_EN "0h";
BA_ "GenSigCycleTime" SG_ 736 TSC_SUPP 50;
BA_ "FlexKomSigStartValue" SG_ 736 TSC_SUPP "00h";
BA_ "FlexKomSID" SG_ 736 TSC_SUPP 396;
BA_ "FlexKomSigStartPos" SG_ 736 TSC_SUPP 47;
BA_ "FlexKomSigLaenge" SG_ 736 TSC_SUPP 8;
BA_ "FlexKomSigName" SG_ 736 TSC_SUPP "EBC_Feature_Status";
BA_ "FlexKomComment" SG_ 736 TSC_SUPP "ESP feature present and enabled";
BA_ "FlexKomIsMotorola" SG_ 736 TSC_SUPP 1;
BA_ "GenSigSNA" SG_ 736 TSC_SUPP "0h";
BA_ "GenSigCycleTime" SG_ 736 TSC_EN 50;
BA_ "FlexKomSigStartValue" SG_ 736 TSC_EN "00h";
BA_ "FlexKomSID" SG_ 736 TSC_EN 396;
BA_ "FlexKomSigStartPos" SG_ 736 TSC_EN 47;
BA_ "FlexKomSigLaenge" SG_ 736 TSC_EN 8;
BA_ "FlexKomSigName" SG_ 736 TSC_EN "EBC_Feature_Status";
BA_ "FlexKomComment" SG_ 736 TSC_EN "ESP feature present and enabled";
BA_ "FlexKomIsMotorola" SG_ 736 TSC_EN 1;
BA_ "GenSigSNA" SG_ 736 TSC_EN "0h";
BA_ "GenSigCycleTime" SG_ 736 ESP_PD_SUPP 50;
BA_ "FlexKomSigStartValue" SG_ 736 ESP_PD_SUPP "00h";
BA_ "FlexKomSID" SG_ 736 ESP_PD_SUPP 396;
BA_ "FlexKomSigStartPos" SG_ 736 ESP_PD_SUPP 47;
BA_ "FlexKomSigLaenge" SG_ 736 ESP_PD_SUPP 8;
BA_ "FlexKomSigName" SG_ 736 ESP_PD_SUPP "EBC_Feature_Status";
BA_ "FlexKomComment" SG_ 736 ESP_PD_SUPP "ESP feature present and enabled";
BA_ "FlexKomIsMotorola" SG_ 736 ESP_PD_SUPP 1;
BA_ "GenSigSNA" SG_ 736 ESP_PD_SUPP "0h";
BA_ "GenSigCycleTime" SG_ 736 ESP_PD_EN 50;
BA_ "FlexKomSigStartValue" SG_ 736 ESP_PD_EN "00h";
BA_ "FlexKomSID" SG_ 736 ESP_PD_EN 396;
BA_ "FlexKomSigStartPos" SG_ 736 ESP_PD_EN 47;
BA_ "FlexKomSigLaenge" SG_ 736 ESP_PD_EN 8;
BA_ "FlexKomSigName" SG_ 736 ESP_PD_EN "EBC_Feature_Status";
BA_ "FlexKomComment" SG_ 736 ESP_PD_EN "ESP feature present and enabled";
BA_ "FlexKomIsMotorola" SG_ 736 ESP_PD_EN 1;
BA_ "GenSigSNA" SG_ 736 ESP_PD_EN "0h";
BA_ "GenSigCycleTime" SG_ 736 HSA_SUPP 50;
BA_ "FlexKomSigStartValue" SG_ 736 HSA_SUPP "00h";
BA_ "GenSigTimeout_IC" SG_ 736 HSA_SUPP 525;
BA_ "FlexKomSID" SG_ 736 HSA_SUPP 396;
BA_ "FlexKomSigStartPos" SG_ 736 HSA_SUPP 47;
BA_ "FlexKomSigLaenge" SG_ 736 HSA_SUPP 8;
BA_ "FlexKomSigName" SG_ 736 HSA_SUPP "EBC_Feature_Status";
BA_ "FlexKomComment" SG_ 736 HSA_SUPP "ESP feature present and enabled";
BA_ "FlexKomIsMotorola" SG_ 736 HSA_SUPP 1;
BA_ "GenSigSNA" SG_ 736 HSA_SUPP "0h";
BA_ "GenSigCycleTime" SG_ 736 HSA_EN 50;
BA_ "FlexKomSigStartValue" SG_ 736 HSA_EN "00h";
BA_ "GenSigTimeout_IC" SG_ 736 HSA_EN 525;
BA_ "FlexKomSID" SG_ 736 HSA_EN 396;
BA_ "FlexKomSigStartPos" SG_ 736 HSA_EN 47;
BA_ "FlexKomSigLaenge" SG_ 736 HSA_EN 8;
BA_ "FlexKomSigName" SG_ 736 HSA_EN "EBC_Feature_Status";
BA_ "FlexKomComment" SG_ 736 HSA_EN "ESP feature present and enabled";
BA_ "FlexKomIsMotorola" SG_ 736 HSA_EN 1;
BA_ "GenSigSNA" SG_ 736 HSA_EN "0h";
BA_ "GenSigCycleTime" SG_ 736 ESP_DSBL 50;
BA_ "FlexKomSigStartValue" SG_ 736 ESP_DSBL "003Fh";
BA_ "GenSigTimeout_IC" SG_ 736 ESP_DSBL 525;
BA_ "GenSigTimeout_ORC" SG_ 736 ESP_DSBL 175;
BA_ "GenSigTimeout_ETM" SG_ 736 ESP_DSBL 525;
BA_ "FlexKomSID" SG_ 736 ESP_DSBL 397;
BA_ "FlexKomSigStartPos" SG_ 736 ESP_DSBL 55;
BA_ "FlexKomSigLaenge" SG_ 736 ESP_DSBL 16;
BA_ "FlexKomSigName" SG_ 736 ESP_DSBL "ESP_HMI";
BA_ "FlexKomComment" SG_ 736 ESP_DSBL "ESP Customer Indicators";
BA_ "FlexKomIsMotorola" SG_ 736 ESP_DSBL 1;
BA_ "GenSigSNA" SG_ 736 ESP_DSBL "0h";
BA_ "GenSigCycleTime" SG_ 736 HILL_DES_STAT 50;
BA_ "FlexKomSigStartValue" SG_ 736 HILL_DES_STAT "003Fh";
BA_ "GenSigTimeout_IC" SG_ 736 HILL_DES_STAT 525;
BA_ "FlexKomSID" SG_ 736 HILL_DES_STAT 397;
BA_ "FlexKomSigStartPos" SG_ 736 HILL_DES_STAT 55;
BA_ "FlexKomSigLaenge" SG_ 736 HILL_DES_STAT 16;
BA_ "FlexKomSigName" SG_ 736 HILL_DES_STAT "ESP_HMI";
BA_ "FlexKomComment" SG_ 736 HILL_DES_STAT "ESP Customer Indicators";
BA_ "FlexKomIsMotorola" SG_ 736 HILL_DES_STAT 1;
BA_ "GenSigSNA" SG_ 736 HILL_DES_STAT "0h";
BA_ "GenSigCycleTime" SG_ 736 ESP_Off_IndLmp_On_Rq 50;
BA_ "FlexKomSigStartValue" SG_ 736 ESP_Off_IndLmp_On_Rq "003Fh";
BA_ "GenSigTimeout_IC" SG_ 736 ESP_Off_IndLmp_On_Rq 275;
BA_ "GenSigTimeout_ORC" SG_ 736 ESP_Off_IndLmp_On_Rq 175;
BA_ "GenSigTimeout_ETM" SG_ 736 ESP_Off_IndLmp_On_Rq 525;
BA_ "FlexKomSID" SG_ 736 ESP_Off_IndLmp_On_Rq 397;
BA_ "FlexKomSigStartPos" SG_ 736 ESP_Off_IndLmp_On_Rq 55;
BA_ "FlexKomSigLaenge" SG_ 736 ESP_Off_IndLmp_On_Rq 16;
BA_ "FlexKomSigName" SG_ 736 ESP_Off_IndLmp_On_Rq "ESP_HMI";
BA_ "FlexKomComment" SG_ 736 ESP_Off_IndLmp_On_Rq "ESP Customer Indicators";
BA_ "FlexKomIsMotorola" SG_ 736 ESP_Off_IndLmp_On_Rq 1;
BA_ "GenSigSNA" SG_ 736 ESP_Off_IndLmp_On_Rq "0h";
BA_ "GenSigCycleTime" SG_ 736 ESP_TRK_MD 50;
BA_ "FlexKomSigStartValue" SG_ 736 ESP_TRK_MD "003Fh";
BA_ "GenSigTimeout_IC" SG_ 736 ESP_TRK_MD 525;
BA_ "GenSigTimeout_ORC" SG_ 736 ESP_TRK_MD 175;
BA_ "FlexKomSID" SG_ 736 ESP_TRK_MD 397;
BA_ "FlexKomSigStartPos" SG_ 736 ESP_TRK_MD 55;
BA_ "FlexKomSigLaenge" SG_ 736 ESP_TRK_MD 16;
BA_ "FlexKomSigName" SG_ 736 ESP_TRK_MD "ESP_HMI";
BA_ "FlexKomComment" SG_ 736 ESP_TRK_MD "ESP Customer Indicators";
BA_ "FlexKomIsMotorola" SG_ 736 ESP_TRK_MD 1;
BA_ "GenSigSNA" SG_ 736 ESP_TRK_MD "0h";
BA_ "GenSigCycleTime" SG_ 736 ESC_CtrlLmp_Info 50;
BA_ "FlexKomSigStartValue" SG_ 736 ESC_CtrlLmp_Info "003Fh";
BA_ "GenSigStartValue" SG_ 736 ESC_CtrlLmp_Info 3;
BA_ "GenSigTimeout_IC" SG_ 736 ESC_CtrlLmp_Info 275;
BA_ "GenSigTimeout_ORC" SG_ 736 ESC_CtrlLmp_Info 175;
BA_ "GenSigTimeout_ETM" SG_ 736 ESC_CtrlLmp_Info 525;
BA_ "FlexKomSID" SG_ 736 ESC_CtrlLmp_Info 397;
BA_ "FlexKomSigStartPos" SG_ 736 ESC_CtrlLmp_Info 55;
BA_ "FlexKomSigLaenge" SG_ 736 ESC_CtrlLmp_Info 16;
BA_ "FlexKomSigName" SG_ 736 ESC_CtrlLmp_Info "ESP_HMI";
BA_ "FlexKomComment" SG_ 736 ESC_CtrlLmp_Info "ESP Customer Indicators";
BA_ "FlexKomIsMotorola" SG_ 736 ESC_CtrlLmp_Info 1;
BA_ "GenSigSNA" SG_ 736 ESC_CtrlLmp_Info "3h";
BA_ "GenSigCycleTime" SG_ 736 ABS_IndLmp_On_Rq 50;
BA_ "FlexKomSigStartValue" SG_ 736 ABS_IndLmp_On_Rq "003Fh";
BA_ "GenSigStartValue" SG_ 736 ABS_IndLmp_On_Rq 3;
BA_ "GenSigTimeout_IC" SG_ 736 ABS_IndLmp_On_Rq 275;
BA_ "GenSigTimeout_ETM" SG_ 736 ABS_IndLmp_On_Rq 525;
BA_ "FlexKomSID" SG_ 736 ABS_IndLmp_On_Rq 397;
BA_ "FlexKomSigStartPos" SG_ 736 ABS_IndLmp_On_Rq 55;
BA_ "FlexKomSigLaenge" SG_ 736 ABS_IndLmp_On_Rq 16;
BA_ "FlexKomSigName" SG_ 736 ABS_IndLmp_On_Rq "ESP_HMI";
BA_ "FlexKomComment" SG_ 736 ABS_IndLmp_On_Rq "ESP Customer Indicators";
BA_ "FlexKomIsMotorola" SG_ 736 ABS_IndLmp_On_Rq 1;
BA_ "GenSigSNA" SG_ 736 ABS_IndLmp_On_Rq "3h";
BA_ "GenSigCycleTime" SG_ 736 BrkIndLmp_On_Rq_ESC 50;
BA_ "FlexKomSigStartValue" SG_ 736 BrkIndLmp_On_Rq_ESC "003Fh";
BA_ "GenSigStartValue" SG_ 736 BrkIndLmp_On_Rq_ESC 3;
BA_ "GenSigTimeout_IC" SG_ 736 BrkIndLmp_On_Rq_ESC 275;
BA_ "GenSigTimeout_ETM" SG_ 736 BrkIndLmp_On_Rq_ESC 525;
BA_ "FlexKomSID" SG_ 736 BrkIndLmp_On_Rq_ESC 397;
BA_ "FlexKomSigStartPos" SG_ 736 BrkIndLmp_On_Rq_ESC 55;
BA_ "FlexKomSigLaenge" SG_ 736 BrkIndLmp_On_Rq_ESC 16;
BA_ "FlexKomSigName" SG_ 736 BrkIndLmp_On_Rq_ESC "ESP_HMI";
BA_ "FlexKomComment" SG_ 736 BrkIndLmp_On_Rq_ESC "ESP Customer Indicators";
BA_ "FlexKomIsMotorola" SG_ 736 BrkIndLmp_On_Rq_ESC 1;
BA_ "GenSigSNA" SG_ 736 BrkIndLmp_On_Rq_ESC "3h";
BA_ "GenSigCycleTime" SG_ 736 SelSpdLmp 50;
BA_ "FlexKomSigStartValue" SG_ 736 SelSpdLmp "003Fh";
BA_ "GenSigTimeout_CBC" SG_ 736 SelSpdLmp 525;
BA_ "GenSigTimeout_IC" SG_ 736 SelSpdLmp 525;
BA_ "FlexKomSID" SG_ 736 SelSpdLmp 397;
BA_ "FlexKomSigStartPos" SG_ 736 SelSpdLmp 55;
BA_ "FlexKomSigLaenge" SG_ 736 SelSpdLmp 16;
BA_ "FlexKomSigName" SG_ 736 SelSpdLmp "ESP_HMI";
BA_ "FlexKomComment" SG_ 736 SelSpdLmp "ESP Customer Indicators";
BA_ "FlexKomIsMotorola" SG_ 736 SelSpdLmp 1;
BA_ "GenSigSNA" SG_ 736 SelSpdLmp "3h";
BA_ "GenSigCycleTime" SG_ 737 VehPerfAccel_X 100;
BA_ "FlexKomSigStartValue" SG_ 737 VehPerfAccel_X "01FEh";
BA_ "GenSigStartValue" SG_ 737 VehPerfAccel_X 510;
BA_ "GenSigTimeout_CBC" SG_ 737 VehPerfAccel_X 1050;
BA_ "GenSigTimeout_IC" SG_ 737 VehPerfAccel_X 1050;
BA_ "FlexKomSID" SG_ 737 VehPerfAccel_X 1724;
BA_ "FlexKomSigStartPos" SG_ 737 VehPerfAccel_X 7;
BA_ "FlexKomSigLaenge" SG_ 737 VehPerfAccel_X 16;
BA_ "FlexKomSigName" SG_ 737 VehPerfAccel_X "VehPerfAccel_X";
BA_ "FlexKomComment" SG_ 737 VehPerfAccel_X "Vehicle longitudinal acceleration (+ means forward";
BA_ "FlexKomIsMotorola" SG_ 737 VehPerfAccel_X 1;
BA_ "GenSigSNA" SG_ 737 VehPerfAccel_X "3FFh";
BA_ "GenSigCycleTime" SG_ 737 ESC_LnchMd 100;
BA_ "FlexKomSigStartValue" SG_ 737 ESC_LnchMd "00h";
BA_ "GenSigTimeout_CBC" SG_ 737 ESC_LnchMd 1050;
BA_ "GenSigTimeout_IC" SG_ 737 ESC_LnchMd 1050;
BA_ "GenSigTimeout_ORC" SG_ 737 ESC_LnchMd 350;
BA_ "FlexKomSID" SG_ 737 ESC_LnchMd 1764;
BA_ "FlexKomSigStartPos" SG_ 737 ESC_LnchMd 5;
BA_ "FlexKomSigLaenge" SG_ 737 ESC_LnchMd 3;
BA_ "FlexKomSigName" SG_ 737 ESC_LnchMd "ESC_LnchMdPkt";
BA_ "FlexKomComment" SG_ 737 ESC_LnchMd "ESC launch mode packet";
BA_ "FlexKomIsMotorola" SG_ 737 ESC_LnchMd 1;
BA_ "GenSigSNA" SG_ 737 ESC_LnchMd "3h";
BA_ "GenSigCycleTime" SG_ 737 ESC_LnchMdAbrt 100;
BA_ "FlexKomSigStartValue" SG_ 737 ESC_LnchMdAbrt "00h";
BA_ "GenSigTimeout_IC" SG_ 737 ESC_LnchMdAbrt 1050;
BA_ "FlexKomSID" SG_ 737 ESC_LnchMdAbrt 1764;
BA_ "FlexKomSigStartPos" SG_ 737 ESC_LnchMdAbrt 5;
BA_ "FlexKomSigLaenge" SG_ 737 ESC_LnchMdAbrt 3;
BA_ "FlexKomSigName" SG_ 737 ESC_LnchMdAbrt "ESC_LnchMdPkt";
BA_ "FlexKomComment" SG_ 737 ESC_LnchMdAbrt "ESC launch mode packet";
BA_ "FlexKomIsMotorola" SG_ 737 ESC_LnchMdAbrt 1;
BA_ "GenSigSNA" SG_ 737 ESC_LnchMdAbrt "0h";
BA_ "GenSigCycleTime" SG_ 737 VehPerfAccel_Y 100;
BA_ "FlexKomSigStartValue" SG_ 737 VehPerfAccel_Y "01FEh";
BA_ "GenSigStartValue" SG_ 737 VehPerfAccel_Y 510;
BA_ "GenSigTimeout_CBC" SG_ 737 VehPerfAccel_Y 1050;
BA_ "GenSigTimeout_IC" SG_ 737 VehPerfAccel_Y 1050;
BA_ "FlexKomSID" SG_ 737 VehPerfAccel_Y 1723;
BA_ "FlexKomSigStartPos" SG_ 737 VehPerfAccel_Y 23;
BA_ "FlexKomSigLaenge" SG_ 737 VehPerfAccel_Y 16;
BA_ "FlexKomSigName" SG_ 737 VehPerfAccel_Y "VehPerfAccel_Y";
BA_ "FlexKomComment" SG_ 737 VehPerfAccel_Y "Vehicle lateral acceleration (+ means left, specif";
BA_ "FlexKomIsMotorola" SG_ 737 VehPerfAccel_Y 1;
BA_ "GenSigSNA" SG_ 737 VehPerfAccel_Y "3FFh";
BA_ "GenSigCycleTime" SG_ 737 LaunchRPMsetting_ESC 100;
BA_ "FlexKomSigStartValue" SG_ 737 LaunchRPMsetting_ESC "00h";
BA_ "GenSigTimeout_CBC" SG_ 737 LaunchRPMsetting_ESC 1050;
BA_ "FlexKomSID" SG_ 737 LaunchRPMsetting_ESC 2066;
BA_ "FlexKomSigStartPos" SG_ 737 LaunchRPMsetting_ESC 23;
BA_ "FlexKomSigLaenge" SG_ 737 LaunchRPMsetting_ESC 5;
BA_ "FlexKomSigName" SG_ 737 LaunchRPMsetting_ESC "LaunchRPMsetting_ESC";
BA_ "FlexKomComment" SG_ 737 LaunchRPMsetting_ESC "Launch RPM setting";
BA_ "FlexKomIsMotorola" SG_ 737 LaunchRPMsetting_ESC 1;
BA_ "GenSigSNA" SG_ 737 LaunchRPMsetting_ESC "1Fh";
BA_ "GenSigCycleTime" SG_ 737 ESC_LnchMdCnd1 100;
BA_ "FlexKomSigStartValue" SG_ 737 ESC_LnchMdCnd1 "00h";
BA_ "GenSigTimeout_IC" SG_ 737 ESC_LnchMdCnd1 1050;
BA_ "FlexKomSID" SG_ 737 ESC_LnchMdCnd1 1765;
BA_ "FlexKomSigStartPos" SG_ 737 ESC_LnchMdCnd1 37;
BA_ "FlexKomSigLaenge" SG_ 737 ESC_LnchMdCnd1 6;
BA_ "FlexKomSigName" SG_ 737 ESC_LnchMdCnd1 "ESC_LnchCnd";
BA_ "FlexKomComment" SG_ 737 ESC_LnchMdCnd1 "ESC Launch Mode condition checks packet";
BA_ "FlexKomIsMotorola" SG_ 737 ESC_LnchMdCnd1 1;
BA_ "GenSigSNA" SG_ 737 ESC_LnchMdCnd1 "0h";
BA_ "GenSigCycleTime" SG_ 737 ESC_LnchMdCnd2 100;
BA_ "FlexKomSigStartValue" SG_ 737 ESC_LnchMdCnd2 "00h";
BA_ "GenSigTimeout_IC" SG_ 737 ESC_LnchMdCnd2 1050;
BA_ "FlexKomSID" SG_ 737 ESC_LnchMdCnd2 1765;
BA_ "FlexKomSigStartPos" SG_ 737 ESC_LnchMdCnd2 37;
BA_ "FlexKomSigLaenge" SG_ 737 ESC_LnchMdCnd2 6;
BA_ "FlexKomSigName" SG_ 737 ESC_LnchMdCnd2 "ESC_LnchCnd";
BA_ "FlexKomComment" SG_ 737 ESC_LnchMdCnd2 "ESC Launch Mode condition checks packet";
BA_ "FlexKomIsMotorola" SG_ 737 ESC_LnchMdCnd2 1;
BA_ "GenSigSNA" SG_ 737 ESC_LnchMdCnd2 "0h";
BA_ "GenSigCycleTime" SG_ 737 ESC_LnchMdCnd3 100;
BA_ "FlexKomSigStartValue" SG_ 737 ESC_LnchMdCnd3 "00h";
BA_ "GenSigTimeout_IC" SG_ 737 ESC_LnchMdCnd3 1050;
BA_ "FlexKomSID" SG_ 737 ESC_LnchMdCnd3 1765;
BA_ "FlexKomSigStartPos" SG_ 737 ESC_LnchMdCnd3 37;
BA_ "FlexKomSigLaenge" SG_ 737 ESC_LnchMdCnd3 6;
BA_ "FlexKomSigName" SG_ 737 ESC_LnchMdCnd3 "ESC_LnchCnd";
BA_ "FlexKomComment" SG_ 737 ESC_LnchMdCnd3 "ESC Launch Mode condition checks packet";
BA_ "FlexKomIsMotorola" SG_ 737 ESC_LnchMdCnd3 1;
BA_ "GenSigSNA" SG_ 737 ESC_LnchMdCnd3 "0h";
BA_ "GenSigCycleTime" SG_ 737 ESC_LnchMdCnd4 100;
BA_ "FlexKomSigStartValue" SG_ 737 ESC_LnchMdCnd4 "00h";
BA_ "GenSigTimeout_IC" SG_ 737 ESC_LnchMdCnd4 1050;
BA_ "FlexKomSID" SG_ 737 ESC_LnchMdCnd4 1765;
BA_ "FlexKomSigStartPos" SG_ 737 ESC_LnchMdCnd4 37;
BA_ "FlexKomSigLaenge" SG_ 737 ESC_LnchMdCnd4 6;
BA_ "FlexKomSigName" SG_ 737 ESC_LnchMdCnd4 "ESC_LnchCnd";
BA_ "FlexKomComment" SG_ 737 ESC_LnchMdCnd4 "ESC Launch Mode condition checks packet";
BA_ "FlexKomIsMotorola" SG_ 737 ESC_LnchMdCnd4 1;
BA_ "GenSigSNA" SG_ 737 ESC_LnchMdCnd4 "0h";
BA_ "GenSigCycleTime" SG_ 737 ESC_LnchMdCnd5 100;
BA_ "FlexKomSigStartValue" SG_ 737 ESC_LnchMdCnd5 "00h";
BA_ "GenSigTimeout_IC" SG_ 737 ESC_LnchMdCnd5 1050;
BA_ "FlexKomSID" SG_ 737 ESC_LnchMdCnd5 1765;
BA_ "FlexKomSigStartPos" SG_ 737 ESC_LnchMdCnd5 37;
BA_ "FlexKomSigLaenge" SG_ 737 ESC_LnchMdCnd5 6;
BA_ "FlexKomSigName" SG_ 737 ESC_LnchMdCnd5 "ESC_LnchCnd";
BA_ "FlexKomComment" SG_ 737 ESC_LnchMdCnd5 "ESC Launch Mode condition checks packet";
BA_ "FlexKomIsMotorola" SG_ 737 ESC_LnchMdCnd5 1;
BA_ "GenSigSNA" SG_ 737 ESC_LnchMdCnd5 "0h";
BA_ "GenSigCycleTime" SG_ 737 ESC_LnchMdCnd6 100;
BA_ "FlexKomSigStartValue" SG_ 737 ESC_LnchMdCnd6 "00h";
BA_ "GenSigTimeout_IC" SG_ 737 ESC_LnchMdCnd6 1050;
BA_ "FlexKomSID" SG_ 737 ESC_LnchMdCnd6 1765;
BA_ "FlexKomSigStartPos" SG_ 737 ESC_LnchMdCnd6 37;
BA_ "FlexKomSigLaenge" SG_ 737 ESC_LnchMdCnd6 6;
BA_ "FlexKomSigName" SG_ 737 ESC_LnchMdCnd6 "ESC_LnchCnd";
BA_ "FlexKomComment" SG_ 737 ESC_LnchMdCnd6 "ESC Launch Mode condition checks packet";
BA_ "FlexKomIsMotorola" SG_ 737 ESC_LnchMdCnd6 1;
BA_ "GenSigSNA" SG_ 737 ESC_LnchMdCnd6 "0h";
BA_ "GenSigCycleTime" SG_ 737 BrkWearInd 100;
BA_ "FlexKomSigStartValue" SG_ 737 BrkWearInd "00h";
BA_ "GenSigTimeout_IC" SG_ 737 BrkWearInd 1050;
BA_ "FlexKomSID" SG_ 737 BrkWearInd 1803;
BA_ "FlexKomSigStartPos" SG_ 737 BrkWearInd 39;
BA_ "FlexKomSigLaenge" SG_ 737 BrkWearInd 2;
BA_ "FlexKomSigName" SG_ 737 BrkWearInd "BrkWearInd";
BA_ "FlexKomComment" SG_ 737 BrkWearInd "Brake pad wear indication";
BA_ "FlexKomIsMotorola" SG_ 737 BrkWearInd 1;
BA_ "GenSigSNA" SG_ 737 BrkWearInd "3h";
BA_ "GenSigCycleTime" SG_ 737 ESC_sftbtn_launch_sel 100;
BA_ "FlexKomSigStartValue" SG_ 737 ESC_sftbtn_launch_sel "00h";
BA_ "FlexKomSID" SG_ 737 ESC_sftbtn_launch_sel 2095;
BA_ "FlexKomSigStartPos" SG_ 737 ESC_sftbtn_launch_sel 40;
BA_ "FlexKomSigLaenge" SG_ 737 ESC_sftbtn_launch_sel 1;
BA_ "FlexKomSigName" SG_ 737 ESC_sftbtn_launch_sel "ESC_sftbtn_launch_sel";
BA_ "FlexKomComment" SG_ 737 ESC_sftbtn_launch_sel "Soft button launch selected; Launch selected = [1]";
BA_ "FlexKomIsMotorola" SG_ 737 ESC_sftbtn_launch_sel 1;
BA_ "GenSigSNA" SG_ 737 ESC_sftbtn_launch_sel "0h";
BA_ "GenSigCycleTime" SG_ 737 ICS_ESC_OFF_LED_hrdbtn_cnrtl 100;
BA_ "FlexKomSigStartValue" SG_ 737 ICS_ESC_OFF_LED_hrdbtn_cnrtl "00h";
BA_ "GenSigTimeout_CBC" SG_ 737 ICS_ESC_OFF_LED_hrdbtn_cnrtl 1050;
BA_ "FlexKomSID" SG_ 737 ICS_ESC_OFF_LED_hrdbtn_cnrtl 2069;
BA_ "FlexKomSigStartPos" SG_ 737 ICS_ESC_OFF_LED_hrdbtn_cnrtl 42;
BA_ "FlexKomSigLaenge" SG_ 737 ICS_ESC_OFF_LED_hrdbtn_cnrtl 2;
BA_ "FlexKomSigName" SG_ 737 ICS_ESC_OFF_LED_hrdbtn_cnrtl "ICS_ESC_OFF_LED_hrdbtn_cnrtl";
BA_ "FlexKomComment" SG_ 737 ICS_ESC_OFF_LED_hrdbtn_cnrtl "Button 4 control status";
BA_ "FlexKomIsMotorola" SG_ 737 ICS_ESC_OFF_LED_hrdbtn_cnrtl 1;
BA_ "GenSigSNA" SG_ 737 ICS_ESC_OFF_LED_hrdbtn_cnrtl "3h";
BA_ "GenSigCycleTime" SG_ 737 ESC_OFF_Hrd_Sft_Button_sts 100;
BA_ "FlexKomSigStartValue" SG_ 737 ESC_OFF_Hrd_Sft_Button_sts "00h";
BA_ "GenSigTimeout_CBC" SG_ 737 ESC_OFF_Hrd_Sft_Button_sts 1050;
BA_ "FlexKomSID" SG_ 737 ESC_OFF_Hrd_Sft_Button_sts 2068;
BA_ "FlexKomSigStartPos" SG_ 737 ESC_OFF_Hrd_Sft_Button_sts 45;
BA_ "FlexKomSigLaenge" SG_ 737 ESC_OFF_Hrd_Sft_Button_sts 3;
BA_ "FlexKomSigName" SG_ 737 ESC_OFF_Hrd_Sft_Button_sts "ESC_OFF_Hrd_Sft_Button_sts";
BA_ "FlexKomComment" SG_ 737 ESC_OFF_Hrd_Sft_Button_sts "ESC hard button status";
BA_ "FlexKomIsMotorola" SG_ 737 ESC_OFF_Hrd_Sft_Button_sts 1;
BA_ "GenSigSNA" SG_ 737 ESC_OFF_Hrd_Sft_Button_sts "7h";
BA_ "GenSigCycleTime" SG_ 737 ESC_LnchAbrtSts 100;
BA_ "FlexKomSigStartValue" SG_ 737 ESC_LnchAbrtSts "00h";
BA_ "GenSigTimeout_IC" SG_ 737 ESC_LnchAbrtSts 1050;
BA_ "FlexKomSID" SG_ 737 ESC_LnchAbrtSts 2067;
BA_ "FlexKomSigStartPos" SG_ 737 ESC_LnchAbrtSts 47;
BA_ "FlexKomSigLaenge" SG_ 737 ESC_LnchAbrtSts 2;
BA_ "FlexKomSigName" SG_ 737 ESC_LnchAbrtSts "ESC_LnchAbrtSts";
BA_ "FlexKomComment" SG_ 737 ESC_LnchAbrtSts "ESC launch mode abort status";
BA_ "FlexKomIsMotorola" SG_ 737 ESC_LnchAbrtSts 1;
BA_ "GenSigSNA" SG_ 737 ESC_LnchAbrtSts "3h";
BA_ "GenSigCycleTime" SG_ 737 ICS_Launch_HrdBtn_LED_cnrtl 100;
BA_ "FlexKomSigStartValue" SG_ 737 ICS_Launch_HrdBtn_LED_cnrtl "00h";
BA_ "GenSigTimeout_CBC" SG_ 737 ICS_Launch_HrdBtn_LED_cnrtl 1050;
BA_ "FlexKomSID" SG_ 737 ICS_Launch_HrdBtn_LED_cnrtl 2082;
BA_ "FlexKomSigStartPos" SG_ 737 ICS_Launch_HrdBtn_LED_cnrtl 52;
BA_ "FlexKomSigLaenge" SG_ 737 ICS_Launch_HrdBtn_LED_cnrtl 2;
BA_ "FlexKomSigName" SG_ 737 ICS_Launch_HrdBtn_LED_cnrtl "ICS_Launch_HrdBtn_LED_cnrtl";
BA_ "FlexKomComment" SG_ 737 ICS_Launch_HrdBtn_LED_cnrtl "Launch LED control status";
BA_ "FlexKomIsMotorola" SG_ 737 ICS_Launch_HrdBtn_LED_cnrtl 1;
BA_ "GenSigSNA" SG_ 737 ICS_Launch_HrdBtn_LED_cnrtl "3h";
BA_ "GenSigCycleTime" SG_ 737 ESC_LnchMode 100;
BA_ "FlexKomSigStartValue" SG_ 737 ESC_LnchMode "00h";
BA_ "FlexKomSID" SG_ 737 ESC_LnchMode 2078;
BA_ "FlexKomSigStartPos" SG_ 737 ESC_LnchMode 55;
BA_ "FlexKomSigLaenge" SG_ 737 ESC_LnchMode 3;
BA_ "FlexKomSigName" SG_ 737 ESC_LnchMode "ESC_LnchMode";
BA_ "FlexKomComment" SG_ 737 ESC_LnchMode "ESC launch mode - signal # 2";
BA_ "FlexKomIsMotorola" SG_ 737 ESC_LnchMode 1;
BA_ "GenSigSNA" SG_ 737 ESC_LnchMode "7h";
BA_ "GenSigCycleTime" SG_ 739 CNG_GaLvl 100;
BA_ "FlexKomSigStartValue" SG_ 739 CNG_GaLvl "FFh";
BA_ "GenSigStartValue" SG_ 739 CNG_GaLvl 255;
BA_ "FlexKomSID" SG_ 739 CNG_GaLvl 1646;
BA_ "FlexKomSigStartPos" SG_ 739 CNG_GaLvl 7;
BA_ "FlexKomSigLaenge" SG_ 739 CNG_GaLvl 8;
BA_ "FlexKomSigName" SG_ 739 CNG_GaLvl "CNG_GaLvl";
BA_ "FlexKomComment" SG_ 739 CNG_GaLvl "CNG gauge level";
BA_ "FlexKomIsMotorola" SG_ 739 CNG_GaLvl 1;
BA_ "GenSigSNA" SG_ 739 CNG_GaLvl "FFh";
BA_ "GenSigCycleTime" SG_ 739 CNG_LO 100;
BA_ "FlexKomSigStartValue" SG_ 739 CNG_LO "00h";
BA_ "FlexKomSID" SG_ 739 CNG_LO 1647;
BA_ "FlexKomSigStartPos" SG_ 739 CNG_LO 8;
BA_ "FlexKomSigLaenge" SG_ 739 CNG_LO 1;
BA_ "FlexKomSigName" SG_ 739 CNG_LO "CNG_LO";
BA_ "FlexKomComment" SG_ 739 CNG_LO "CNG is low";
BA_ "FlexKomIsMotorola" SG_ 739 CNG_LO 1;
BA_ "GenSigSNA" SG_ 739 CNG_LO "0h";
BA_ "GenSigCycleTime" SG_ 739 EngRunFuelTyp 100;
BA_ "FlexKomSigStartValue" SG_ 739 EngRunFuelTyp "00h";
BA_ "GenSigTimeout_CBC" SG_ 739 EngRunFuelTyp 1050;
BA_ "FlexKomSID" SG_ 739 EngRunFuelTyp 1649;
BA_ "FlexKomSigStartPos" SG_ 739 EngRunFuelTyp 11;
BA_ "FlexKomSigLaenge" SG_ 739 EngRunFuelTyp 3;
BA_ "FlexKomSigName" SG_ 739 EngRunFuelTyp "EngRunFuelTyp";
BA_ "FlexKomComment" SG_ 739 EngRunFuelTyp "Engine running fuel type";
BA_ "FlexKomIsMotorola" SG_ 739 EngRunFuelTyp 1;
BA_ "GenSigSNA" SG_ 739 EngRunFuelTyp "7h";
BA_ "GenSigCycleTime" SG_ 739 EngCNG_WrnStat 100;
BA_ "FlexKomSigStartValue" SG_ 739 EngCNG_WrnStat "00h";
BA_ "FlexKomSID" SG_ 739 EngCNG_WrnStat 1648;
BA_ "FlexKomSigStartPos" SG_ 739 EngCNG_WrnStat 15;
BA_ "FlexKomSigLaenge" SG_ 739 EngCNG_WrnStat 4;
BA_ "FlexKomSigName" SG_ 739 EngCNG_WrnStat "EngCNG_WrnStat";
BA_ "FlexKomComment" SG_ 739 EngCNG_WrnStat "Engine CNG warning status";
BA_ "FlexKomIsMotorola" SG_ 739 EngCNG_WrnStat 1;
BA_ "GenSigSNA" SG_ 739 EngCNG_WrnStat "Fh";
BA_ "GenSigCycleTime" SG_ 739 CNG_FuelUsed 100;
BA_ "FlexKomSigStartValue" SG_ 739 CNG_FuelUsed "FFFFh";
BA_ "GenSigStartValue" SG_ 739 CNG_FuelUsed 65535;
BA_ "FlexKomSID" SG_ 739 CNG_FuelUsed 1645;
BA_ "FlexKomSigStartPos" SG_ 739 CNG_FuelUsed 23;
BA_ "FlexKomSigLaenge" SG_ 739 CNG_FuelUsed 16;
BA_ "FlexKomSigName" SG_ 739 CNG_FuelUsed "CNG_FuelUsed";
BA_ "FlexKomComment" SG_ 739 CNG_FuelUsed "CNG fuel used per 100 ms";
BA_ "FlexKomIsMotorola" SG_ 739 CNG_FuelUsed 1;
BA_ "GenSigSNA" SG_ 739 CNG_FuelUsed "FFFFh";
BA_ "GenSigCycleTime" SG_ 739 CNG_DefFuelEcon 100;
BA_ "FlexKomSigStartValue" SG_ 739 CNG_DefFuelEcon "FFh";
BA_ "GenSigStartValue" SG_ 739 CNG_DefFuelEcon 255;
BA_ "FlexKomSID" SG_ 739 CNG_DefFuelEcon 1644;
BA_ "FlexKomSigStartPos" SG_ 739 CNG_DefFuelEcon 39;
BA_ "FlexKomSigLaenge" SG_ 739 CNG_DefFuelEcon 8;
BA_ "FlexKomSigName" SG_ 739 CNG_DefFuelEcon "CNG_DefFuelEcon";
BA_ "FlexKomComment" SG_ 739 CNG_DefFuelEcon "CNG default fuel economy";
BA_ "FlexKomIsMotorola" SG_ 739 CNG_DefFuelEcon 1;
BA_ "GenSigSNA" SG_ 739 CNG_DefFuelEcon "FFh";
BA_ "GenSigCycleTime" SG_ 746 DrvRqShftROT 20;
BA_ "FlexKomSigStartValue" SG_ 746 DrvRqShftROT "00000000FFh";
BA_ "GenSigTimeout_RF_HUB" SG_ 746 DrvRqShftROT 210;
BA_ "FlexKomSID" SG_ 746 DrvRqShftROT 1661;
BA_ "FlexKomSigStartPos" SG_ 746 DrvRqShftROT 7;
BA_ "FlexKomSigLaenge" SG_ 746 DrvRqShftROT 40;
BA_ "FlexKomSigName" SG_ 746 DrvRqShftROT "SBW_ROT1_PKT";
BA_ "FlexKomComment" SG_ 746 DrvRqShftROT "Shift by wire - rotary 1 packet";
BA_ "FlexKomIsMotorola" SG_ 746 DrvRqShftROT 1;
BA_ "GenSigSNA" SG_ 746 DrvRqShftROT "7h";
BA_ "GenSigCycleTime" SG_ 746 Manual_Gate_Request 20;
BA_ "FlexKomSigStartValue" SG_ 746 Manual_Gate_Request "00000000FFh";
BA_ "FlexKomSID" SG_ 746 Manual_Gate_Request 1661;
BA_ "FlexKomSigStartPos" SG_ 746 Manual_Gate_Request 7;
BA_ "FlexKomSigLaenge" SG_ 746 Manual_Gate_Request 40;
BA_ "FlexKomSigName" SG_ 746 Manual_Gate_Request "SBW_ROT1_PKT";
BA_ "FlexKomComment" SG_ 746 Manual_Gate_Request "Shift by wire - rotary 1 packet";
BA_ "FlexKomIsMotorola" SG_ 746 Manual_Gate_Request 1;
BA_ "GenSigSNA" SG_ 746 Manual_Gate_Request "7h";
BA_ "GenSigCycleTime" SG_ 746 ShiftInProgrss 20;
BA_ "FlexKomSigStartValue" SG_ 746 ShiftInProgrss "00000000FFh";
BA_ "FlexKomSID" SG_ 746 ShiftInProgrss 1661;
BA_ "FlexKomSigStartPos" SG_ 746 ShiftInProgrss 7;
BA_ "FlexKomSigLaenge" SG_ 746 ShiftInProgrss 40;
BA_ "FlexKomSigName" SG_ 746 ShiftInProgrss "SBW_ROT1_PKT";
BA_ "FlexKomComment" SG_ 746 ShiftInProgrss "Shift by wire - rotary 1 packet";
BA_ "FlexKomIsMotorola" SG_ 746 ShiftInProgrss 1;
BA_ "GenSigSNA" SG_ 746 ShiftInProgrss "0h";
BA_ "GenSigCycleTime" SG_ 746 ShftSensFltROT 20;
BA_ "FlexKomSigStartValue" SG_ 746 ShftSensFltROT "00000000FFh";
BA_ "FlexKomSID" SG_ 746 ShftSensFltROT 1661;
BA_ "FlexKomSigStartPos" SG_ 746 ShftSensFltROT 7;
BA_ "FlexKomSigLaenge" SG_ 746 ShftSensFltROT 40;
BA_ "FlexKomSigName" SG_ 746 ShftSensFltROT "SBW_ROT1_PKT";
BA_ "FlexKomComment" SG_ 746 ShftSensFltROT "Shift by wire - rotary 1 packet";
BA_ "FlexKomIsMotorola" SG_ 746 ShftSensFltROT 1;
BA_ "GenSigSNA" SG_ 746 ShftSensFltROT "0h";
BA_ "GenSigCycleTime" SG_ 746 ShftDispFltROT 20;
BA_ "FlexKomSigStartValue" SG_ 746 ShftDispFltROT "00000000FFh";
BA_ "FlexKomSID" SG_ 746 ShftDispFltROT 1661;
BA_ "FlexKomSigStartPos" SG_ 746 ShftDispFltROT 7;
BA_ "FlexKomSigLaenge" SG_ 746 ShftDispFltROT 40;
BA_ "FlexKomSigName" SG_ 746 ShftDispFltROT "SBW_ROT1_PKT";
BA_ "FlexKomComment" SG_ 746 ShftDispFltROT "Shift by wire - rotary 1 packet";
BA_ "FlexKomIsMotorola" SG_ 746 ShftDispFltROT 1;
BA_ "GenSigSNA" SG_ 746 ShftDispFltROT "0h";
BA_ "GenSigCycleTime" SG_ 746 ShftLkFltROT 20;
BA_ "FlexKomSigStartValue" SG_ 746 ShftLkFltROT "00000000FFh";
BA_ "FlexKomSID" SG_ 746 ShftLkFltROT 1661;
BA_ "FlexKomSigStartPos" SG_ 746 ShftLkFltROT 7;
BA_ "FlexKomSigLaenge" SG_ 746 ShftLkFltROT 40;
BA_ "FlexKomSigName" SG_ 746 ShftLkFltROT "SBW_ROT1_PKT";
BA_ "FlexKomComment" SG_ 746 ShftLkFltROT "Shift by wire - rotary 1 packet";
BA_ "FlexKomIsMotorola" SG_ 746 ShftLkFltROT 1;
BA_ "GenSigSNA" SG_ 746 ShftLkFltROT "0h";
BA_ "GenSigCycleTime" SG_ 746 MC_SBW_ROT1 20;
BA_ "FlexKomSigStartValue" SG_ 746 MC_SBW_ROT1 "00000000FFh";
BA_ "FlexKomSID" SG_ 746 MC_SBW_ROT1 1661;
BA_ "FlexKomSigStartPos" SG_ 746 MC_SBW_ROT1 7;
BA_ "FlexKomSigLaenge" SG_ 746 MC_SBW_ROT1 40;
BA_ "FlexKomSigName" SG_ 746 MC_SBW_ROT1 "SBW_ROT1_PKT";
BA_ "FlexKomComment" SG_ 746 MC_SBW_ROT1 "Shift by wire - rotary 1 packet";
BA_ "FlexKomIsMotorola" SG_ 746 MC_SBW_ROT1 1;
BA_ "GenSigSNA" SG_ 746 MC_SBW_ROT1 "0h";
BA_ "GenSigCycleTime" SG_ 746 CRC_SBW_ROT1 20;
BA_ "FlexKomSigStartValue" SG_ 746 CRC_SBW_ROT1 "00000000FFh";
BA_ "GenSigStartValue" SG_ 746 CRC_SBW_ROT1 255;
BA_ "FlexKomSID" SG_ 746 CRC_SBW_ROT1 1661;
BA_ "FlexKomSigStartPos" SG_ 746 CRC_SBW_ROT1 7;
BA_ "FlexKomSigLaenge" SG_ 746 CRC_SBW_ROT1 40;
BA_ "FlexKomSigName" SG_ 746 CRC_SBW_ROT1 "SBW_ROT1_PKT";
BA_ "FlexKomComment" SG_ 746 CRC_SBW_ROT1 "Shift by wire - rotary 1 packet";
BA_ "FlexKomIsMotorola" SG_ 746 CRC_SBW_ROT1 1;
BA_ "GenSigSNA" SG_ 746 CRC_SBW_ROT1 "FFh";
BA_ "GenSigSendType" SG_ 752 RKE_MEM 5;
BA_ "GenSigCycleTime" SG_ 752 RKE_MEM 500;
BA_ "FlexKomSigStartValue" SG_ 752 RKE_MEM "00h";
BA_ "GenSigTimeout_IC" SG_ 752 RKE_MEM 5250;
BA_ "FlexKomSID" SG_ 752 RKE_MEM 465;
BA_ "FlexKomSigLaenge" SG_ 752 RKE_MEM 1;
BA_ "FlexKomSigName" SG_ 752 RKE_MEM "RKE_MEM";
BA_ "FlexKomComment" SG_ 752 RKE_MEM "Remote linked to memory; [0] = NO, [1] = YES";
BA_ "FlexKomIsMotorola" SG_ 752 RKE_MEM 1;
BA_ "GenSigSNA" SG_ 752 RKE_MEM "0h";
BA_ "GenSigSendType" SG_ 752 EASY_EXIT 5;
BA_ "GenSigCycleTime" SG_ 752 EASY_EXIT 500;
BA_ "FlexKomSigStartValue" SG_ 752 EASY_EXIT "03h";
BA_ "GenSigStartValue" SG_ 752 EASY_EXIT 3;
BA_ "GenSigTimeout_IC" SG_ 752 EASY_EXIT 5250;
BA_ "FlexKomSID" SG_ 752 EASY_EXIT 469;
BA_ "FlexKomSigStartPos" SG_ 752 EASY_EXIT 2;
BA_ "FlexKomSigLaenge" SG_ 752 EASY_EXIT 2;
BA_ "FlexKomSigName" SG_ 752 EASY_EXIT "EASY_EXIT";
BA_ "FlexKomComment" SG_ 752 EASY_EXIT "Easy exit seat state";
BA_ "FlexKomIsMotorola" SG_ 752 EASY_EXIT 1;
BA_ "GenSigSNA" SG_ 752 EASY_EXIT "3h";
BA_ "GenSigSendType" SG_ 752 MEM_RC_STAT 5;
BA_ "GenSigCycleTime" SG_ 752 MEM_RC_STAT 500;
BA_ "FlexKomSigStartValue" SG_ 752 MEM_RC_STAT "00h";
BA_ "GenSigTimeout_IC" SG_ 752 MEM_RC_STAT 5250;
BA_ "FlexKomSID" SG_ 752 MEM_RC_STAT 470;
BA_ "FlexKomSigStartPos" SG_ 752 MEM_RC_STAT 5;
BA_ "FlexKomSigLaenge" SG_ 752 MEM_RC_STAT 3;
BA_ "FlexKomSigName" SG_ 752 MEM_RC_STAT "MEM_RC_STAT";
BA_ "FlexKomComment" SG_ 752 MEM_RC_STAT "Memory recall status";
BA_ "FlexKomIsMotorola" SG_ 752 MEM_RC_STAT 1;
BA_ "GenSigSNA" SG_ 752 MEM_RC_STAT "7h";
BA_ "GenSigSendType" SG_ 752 MSMD_PDL_LKOUT 5;
BA_ "GenSigCycleTime" SG_ 752 MSMD_PDL_LKOUT 500;
BA_ "FlexKomSigStartValue" SG_ 752 MSMD_PDL_LKOUT "00h";
BA_ "GenSigTimeout_IC" SG_ 752 MSMD_PDL_LKOUT 5250;
BA_ "FlexKomSID" SG_ 752 MSMD_PDL_LKOUT 471;
BA_ "FlexKomSigStartPos" SG_ 752 MSMD_PDL_LKOUT 10;
BA_ "FlexKomSigLaenge" SG_ 752 MSMD_PDL_LKOUT 3;
BA_ "FlexKomSigName" SG_ 752 MSMD_PDL_LKOUT "MSMD_PDL_LKOUT";
BA_ "FlexKomComment" SG_ 752 MSMD_PDL_LKOUT "Adjustable pedal lockout";
BA_ "FlexKomIsMotorola" SG_ 752 MSMD_PDL_LKOUT 1;
BA_ "GenSigSNA" SG_ 752 MSMD_PDL_LKOUT "7h";
BA_ "GenSigCycleTime" SG_ 760 EngTrqTgt_SEM 10;
BA_ "FlexKomSigStartValue" SG_ 760 EngTrqTgt_SEM "1FFF1FFF00FF0FFFh";
BA_ "GenSigStartValue" SG_ 760 EngTrqTgt_SEM 8191;
BA_ "FlexKomSID" SG_ 760 EngTrqTgt_SEM 1369;
BA_ "FlexKomSigStartPos" SG_ 760 EngTrqTgt_SEM 7;
BA_ "FlexKomSigLaenge" SG_ 760 EngTrqTgt_SEM 64;
BA_ "FlexKomSigName" SG_ 760 EngTrqTgt_SEM "ECM_A3_PKT";
BA_ "FlexKomComment" SG_ 760 EngTrqTgt_SEM "ECM_A3 message packet";
BA_ "FlexKomIsMotorola" SG_ 760 EngTrqTgt_SEM 1;
BA_ "GenSigSNA" SG_ 760 EngTrqTgt_SEM "1FFFh";
BA_ "GenSigCycleTime" SG_ 760 EngRdyForESS 10;
BA_ "FlexKomSigStartValue" SG_ 760 EngRdyForESS "1FFF1FFF00FF0FFFh";
BA_ "FlexKomSID" SG_ 760 EngRdyForESS 1369;
BA_ "FlexKomSigStartPos" SG_ 760 EngRdyForESS 7;
BA_ "FlexKomSigLaenge" SG_ 760 EngRdyForESS 64;
BA_ "FlexKomSigName" SG_ 760 EngRdyForESS "ECM_A3_PKT";
BA_ "FlexKomComment" SG_ 760 EngRdyForESS "ECM_A3 message packet";
BA_ "FlexKomIsMotorola" SG_ 760 EngRdyForESS 1;
BA_ "GenSigSNA" SG_ 760 EngRdyForESS "0h";
BA_ "GenSigCycleTime" SG_ 760 EngTrqStatic_SEM 10;
BA_ "FlexKomSigStartValue" SG_ 760 EngTrqStatic_SEM "1FFF1FFF00FF0FFFh";
BA_ "GenSigStartValue" SG_ 760 EngTrqStatic_SEM 8191;
BA_ "FlexKomSID" SG_ 760 EngTrqStatic_SEM 1369;
BA_ "FlexKomSigStartPos" SG_ 760 EngTrqStatic_SEM 7;
BA_ "FlexKomSigLaenge" SG_ 760 EngTrqStatic_SEM 64;
BA_ "FlexKomSigName" SG_ 760 EngTrqStatic_SEM "ECM_A3_PKT";
BA_ "FlexKomComment" SG_ 760 EngTrqStatic_SEM "ECM_A3 message packet";
BA_ "FlexKomIsMotorola" SG_ 760 EngTrqStatic_SEM 1;
BA_ "GenSigSNA" SG_ 760 EngTrqStatic_SEM "1FFFh";
BA_ "GenSigCycleTime" SG_ 760 TRANS_CLU_SLIP_MODE 10;
BA_ "FlexKomSigStartValue" SG_ 760 TRANS_CLU_SLIP_MODE "1FFF1FFF00FF0FFFh";
BA_ "FlexKomSID" SG_ 760 TRANS_CLU_SLIP_MODE 1369;
BA_ "FlexKomSigStartPos" SG_ 760 TRANS_CLU_SLIP_MODE 7;
BA_ "FlexKomSigLaenge" SG_ 760 TRANS_CLU_SLIP_MODE 64;
BA_ "FlexKomSigName" SG_ 760 TRANS_CLU_SLIP_MODE "ECM_A3_PKT";
BA_ "FlexKomComment" SG_ 760 TRANS_CLU_SLIP_MODE "ECM_A3 message packet";
BA_ "FlexKomIsMotorola" SG_ 760 TRANS_CLU_SLIP_MODE 1;
BA_ "GenSigSNA" SG_ 760 TRANS_CLU_SLIP_MODE "7h";
BA_ "GenSigCycleTime" SG_ 760 ThrmlMngActv 10;
BA_ "FlexKomSigStartValue" SG_ 760 ThrmlMngActv "1FFF1FFF00FF0FFFh";
BA_ "FlexKomSID" SG_ 760 ThrmlMngActv 1369;
BA_ "FlexKomSigStartPos" SG_ 760 ThrmlMngActv 7;
BA_ "FlexKomSigLaenge" SG_ 760 ThrmlMngActv 64;
BA_ "FlexKomSigName" SG_ 760 ThrmlMngActv "ECM_A3_PKT";
BA_ "FlexKomComment" SG_ 760 ThrmlMngActv "ECM_A3 message packet";
BA_ "FlexKomIsMotorola" SG_ 760 ThrmlMngActv 1;
BA_ "GenSigSNA" SG_ 760 ThrmlMngActv "0h";
BA_ "GenSigCycleTime" SG_ 760 ThrmlMngMd 10;
BA_ "FlexKomSigStartValue" SG_ 760 ThrmlMngMd "1FFF1FFF00FF0FFFh";
BA_ "GenSigTimeout_CBC" SG_ 760 ThrmlMngMd 105;
BA_ "FlexKomSID" SG_ 760 ThrmlMngMd 1369;
BA_ "FlexKomSigStartPos" SG_ 760 ThrmlMngMd 7;
BA_ "FlexKomSigLaenge" SG_ 760 ThrmlMngMd 64;
BA_ "FlexKomSigName" SG_ 760 ThrmlMngMd "ECM_A3_PKT";
BA_ "FlexKomComment" SG_ 760 ThrmlMngMd "ECM_A3 message packet";
BA_ "FlexKomIsMotorola" SG_ 760 ThrmlMngMd 1;
BA_ "GenSigSNA" SG_ 760 ThrmlMngMd "7h";
BA_ "GenSigCycleTime" SG_ 760 EngMaxRPM 10;
BA_ "FlexKomSigStartValue" SG_ 760 EngMaxRPM "1FFF1FFF00FF0FFFh";
BA_ "GenSigStartValue" SG_ 760 EngMaxRPM 255;
BA_ "FlexKomSID" SG_ 760 EngMaxRPM 1369;
BA_ "FlexKomSigStartPos" SG_ 760 EngMaxRPM 7;
BA_ "FlexKomSigLaenge" SG_ 760 EngMaxRPM 64;
BA_ "FlexKomSigName" SG_ 760 EngMaxRPM "ECM_A3_PKT";
BA_ "FlexKomComment" SG_ 760 EngMaxRPM "ECM_A3 message packet";
BA_ "FlexKomIsMotorola" SG_ 760 EngMaxRPM 1;
BA_ "GenSigSNA" SG_ 760 EngMaxRPM "FFh";
BA_ "GenSigCycleTime" SG_ 760 ESS_ENG_ST 10;
BA_ "FlexKomSigStartValue" SG_ 760 ESS_ENG_ST "1FFF1FFF00FF0FFFh";
BA_ "GenSigStartValue" SG_ 760 ESS_ENG_ST 15;
BA_ "GenSigTimeout_CBC" SG_ 760 ESS_ENG_ST 105;
BA_ "GenSigTimeout_ORC" SG_ 760 ESS_ENG_ST 35;
BA_ "FlexKomSID" SG_ 760 ESS_ENG_ST 1369;
BA_ "FlexKomSigStartPos" SG_ 760 ESS_ENG_ST 7;
BA_ "FlexKomSigLaenge" SG_ 760 ESS_ENG_ST 64;
BA_ "FlexKomSigName" SG_ 760 ESS_ENG_ST "ECM_A3_PKT";
BA_ "FlexKomComment" SG_ 760 ESS_ENG_ST "ECM_A3 message packet";
BA_ "FlexKomIsMotorola" SG_ 760 ESS_ENG_ST 1;
BA_ "GenSigSNA" SG_ 760 ESS_ENG_ST "Fh";
BA_ "GenSigCycleTime" SG_ 760 MC_ECM_A3 10;
BA_ "FlexKomSigStartValue" SG_ 760 MC_ECM_A3 "1FFF1FFF00FF0FFFh";
BA_ "FlexKomSID" SG_ 760 MC_ECM_A3 1369;
BA_ "FlexKomSigStartPos" SG_ 760 MC_ECM_A3 7;
BA_ "FlexKomSigLaenge" SG_ 760 MC_ECM_A3 64;
BA_ "FlexKomSigName" SG_ 760 MC_ECM_A3 "ECM_A3_PKT";
BA_ "FlexKomComment" SG_ 760 MC_ECM_A3 "ECM_A3 message packet";
BA_ "FlexKomIsMotorola" SG_ 760 MC_ECM_A3 1;
BA_ "GenSigSNA" SG_ 760 MC_ECM_A3 "0h";
BA_ "GenSigCycleTime" SG_ 760 CRC_ECM_A3 10;
BA_ "FlexKomSigStartValue" SG_ 760 CRC_ECM_A3 "1FFF1FFF00FF0FFFh";
BA_ "GenSigStartValue" SG_ 760 CRC_ECM_A3 255;
BA_ "FlexKomSID" SG_ 760 CRC_ECM_A3 1369;
BA_ "FlexKomSigStartPos" SG_ 760 CRC_ECM_A3 7;
BA_ "FlexKomSigLaenge" SG_ 760 CRC_ECM_A3 64;
BA_ "FlexKomSigName" SG_ 760 CRC_ECM_A3 "ECM_A3_PKT";
BA_ "FlexKomComment" SG_ 760 CRC_ECM_A3 "ECM_A3 message packet";
BA_ "FlexKomIsMotorola" SG_ 760 CRC_ECM_A3 1;
BA_ "GenSigSNA" SG_ 760 CRC_ECM_A3 "FFh";
BA_ "GenSigCycleTime" SG_ 761 EngTrqRq 10;
BA_ "FlexKomSigStartValue" SG_ 761 EngTrqRq "1FFF1FFF1FFF00FFh";
BA_ "GenSigStartValue" SG_ 761 EngTrqRq 8191;
BA_ "FlexKomSID" SG_ 761 EngTrqRq 1379;
BA_ "FlexKomSigStartPos" SG_ 761 EngTrqRq 7;
BA_ "FlexKomSigLaenge" SG_ 761 EngTrqRq 64;
BA_ "FlexKomSigName" SG_ 761 EngTrqRq "TCM_EngTrq2_Pkt";
BA_ "FlexKomComment" SG_ 761 EngTrqRq "Engine Torque Pkt";
BA_ "FlexKomIsMotorola" SG_ 761 EngTrqRq 1;
BA_ "GenSigSNA" SG_ 761 EngTrqRq "1FFFh";
BA_ "GenSigCycleTime" SG_ 761 TrqCtrlModeRq 10;
BA_ "FlexKomSigStartValue" SG_ 761 TrqCtrlModeRq "1FFF1FFF1FFF00FFh";
BA_ "FlexKomSID" SG_ 761 TrqCtrlModeRq 1379;
BA_ "FlexKomSigStartPos" SG_ 761 TrqCtrlModeRq 7;
BA_ "FlexKomSigLaenge" SG_ 761 TrqCtrlModeRq 64;
BA_ "FlexKomSigName" SG_ 761 TrqCtrlModeRq "TCM_EngTrq2_Pkt";
BA_ "FlexKomComment" SG_ 761 TrqCtrlModeRq "Engine Torque Pkt";
BA_ "FlexKomIsMotorola" SG_ 761 TrqCtrlModeRq 1;
BA_ "GenSigSNA" SG_ 761 TrqCtrlModeRq "7h";
BA_ "GenSigCycleTime" SG_ 761 TrnsTrqReqSlow 10;
BA_ "FlexKomSigStartValue" SG_ 761 TrnsTrqReqSlow "1FFF1FFF1FFF00FFh";
BA_ "GenSigStartValue" SG_ 761 TrnsTrqReqSlow 8191;
BA_ "FlexKomSID" SG_ 761 TrnsTrqReqSlow 1379;
BA_ "FlexKomSigStartPos" SG_ 761 TrnsTrqReqSlow 7;
BA_ "FlexKomSigLaenge" SG_ 761 TrnsTrqReqSlow 64;
BA_ "FlexKomSigName" SG_ 761 TrnsTrqReqSlow "TCM_EngTrq2_Pkt";
BA_ "FlexKomComment" SG_ 761 TrnsTrqReqSlow "Engine Torque Pkt";
BA_ "FlexKomIsMotorola" SG_ 761 TrnsTrqReqSlow 1;
BA_ "GenSigSNA" SG_ 761 TrnsTrqReqSlow "1FFFh";
BA_ "GenSigCycleTime" SG_ 761 TrqCtrlModeReqSlow 10;
BA_ "FlexKomSigStartValue" SG_ 761 TrqCtrlModeReqSlow "1FFF1FFF1FFF00FFh";
BA_ "FlexKomSID" SG_ 761 TrqCtrlModeReqSlow 1379;
BA_ "FlexKomSigStartPos" SG_ 761 TrqCtrlModeReqSlow 7;
BA_ "FlexKomSigLaenge" SG_ 761 TrqCtrlModeReqSlow 64;
BA_ "FlexKomSigName" SG_ 761 TrqCtrlModeReqSlow "TCM_EngTrq2_Pkt";
BA_ "FlexKomComment" SG_ 761 TrqCtrlModeReqSlow "Engine Torque Pkt";
BA_ "FlexKomIsMotorola" SG_ 761 TrqCtrlModeReqSlow 1;
BA_ "GenSigSNA" SG_ 761 TrqCtrlModeReqSlow "3h";
BA_ "GenSigCycleTime" SG_ 761 MaxTrqDes 10;
BA_ "FlexKomSigStartValue" SG_ 761 MaxTrqDes "1FFF1FFF1FFF00FFh";
BA_ "GenSigStartValue" SG_ 761 MaxTrqDes 8191;
BA_ "FlexKomSID" SG_ 761 MaxTrqDes 1379;
BA_ "FlexKomSigStartPos" SG_ 761 MaxTrqDes 7;
BA_ "FlexKomSigLaenge" SG_ 761 MaxTrqDes 64;
BA_ "FlexKomSigName" SG_ 761 MaxTrqDes "TCM_EngTrq2_Pkt";
BA_ "FlexKomComment" SG_ 761 MaxTrqDes "Engine Torque Pkt";
BA_ "FlexKomIsMotorola" SG_ 761 MaxTrqDes 1;
BA_ "GenSigSNA" SG_ 761 MaxTrqDes "1FFFh";
BA_ "GenSigCycleTime" SG_ 761 MC_TCM_EngTrq2 10;
BA_ "FlexKomSigStartValue" SG_ 761 MC_TCM_EngTrq2 "1FFF1FFF1FFF00FFh";
BA_ "FlexKomSID" SG_ 761 MC_TCM_EngTrq2 1379;
BA_ "FlexKomSigStartPos" SG_ 761 MC_TCM_EngTrq2 7;
BA_ "FlexKomSigLaenge" SG_ 761 MC_TCM_EngTrq2 64;
BA_ "FlexKomSigName" SG_ 761 MC_TCM_EngTrq2 "TCM_EngTrq2_Pkt";
BA_ "FlexKomComment" SG_ 761 MC_TCM_EngTrq2 "Engine Torque Pkt";
BA_ "FlexKomIsMotorola" SG_ 761 MC_TCM_EngTrq2 1;
BA_ "GenSigSNA" SG_ 761 MC_TCM_EngTrq2 "0h";
BA_ "GenSigCycleTime" SG_ 761 CRC_TCM_EngTrq2 10;
BA_ "FlexKomSigStartValue" SG_ 761 CRC_TCM_EngTrq2 "1FFF1FFF1FFF00FFh";
BA_ "GenSigStartValue" SG_ 761 CRC_TCM_EngTrq2 255;
BA_ "FlexKomSID" SG_ 761 CRC_TCM_EngTrq2 1379;
BA_ "FlexKomSigStartPos" SG_ 761 CRC_TCM_EngTrq2 7;
BA_ "FlexKomSigLaenge" SG_ 761 CRC_TCM_EngTrq2 64;
BA_ "FlexKomSigName" SG_ 761 CRC_TCM_EngTrq2 "TCM_EngTrq2_Pkt";
BA_ "FlexKomComment" SG_ 761 CRC_TCM_EngTrq2 "Engine Torque Pkt";
BA_ "FlexKomIsMotorola" SG_ 761 CRC_TCM_EngTrq2 1;
BA_ "GenSigSNA" SG_ 761 CRC_TCM_EngTrq2 "FFh";
BA_ "GenSigCycleTime" SG_ 762 DRV_RQ_SHFT 20;
BA_ "FlexKomSigStartValue" SG_ 762 DRV_RQ_SHFT "F04C0000FFh";
BA_ "FlexKomSID" SG_ 762 DRV_RQ_SHFT 1372;
BA_ "FlexKomSigStartPos" SG_ 762 DRV_RQ_SHFT 7;
BA_ "FlexKomSigLaenge" SG_ 762 DRV_RQ_SHFT 40;
BA_ "FlexKomSigName" SG_ 762 DRV_RQ_SHFT "SBWM_A1_PKT";
BA_ "FlexKomComment" SG_ 762 DRV_RQ_SHFT "Shift by wire A1 packet";
BA_ "FlexKomIsMotorola" SG_ 762 DRV_RQ_SHFT 1;
BA_ "GenSigSNA" SG_ 762 DRV_RQ_SHFT "Fh";
BA_ "GenSigCycleTime" SG_ 762 DRV_RQ_SHFT_INV 20;
BA_ "FlexKomSigStartValue" SG_ 762 DRV_RQ_SHFT_INV "F04C0000FFh";
BA_ "GenSigStartValue" SG_ 762 DRV_RQ_SHFT_INV 15;
BA_ "FlexKomSID" SG_ 762 DRV_RQ_SHFT_INV 1372;
BA_ "FlexKomSigStartPos" SG_ 762 DRV_RQ_SHFT_INV 7;
BA_ "FlexKomSigLaenge" SG_ 762 DRV_RQ_SHFT_INV 40;
BA_ "FlexKomSigName" SG_ 762 DRV_RQ_SHFT_INV "SBWM_A1_PKT";
BA_ "FlexKomComment" SG_ 762 DRV_RQ_SHFT_INV "Shift by wire A1 packet";
BA_ "FlexKomIsMotorola" SG_ 762 DRV_RQ_SHFT_INV 1;
BA_ "GenSigSNA" SG_ 762 DRV_RQ_SHFT_INV "0h";
BA_ "GenSigCycleTime" SG_ 762 SHFT_SENS_FLT 20;
BA_ "FlexKomSigStartValue" SG_ 762 SHFT_SENS_FLT "F04C0000FFh";
BA_ "FlexKomSID" SG_ 762 SHFT_SENS_FLT 1372;
BA_ "FlexKomSigStartPos" SG_ 762 SHFT_SENS_FLT 7;
BA_ "FlexKomSigLaenge" SG_ 762 SHFT_SENS_FLT 40;
BA_ "FlexKomSigName" SG_ 762 SHFT_SENS_FLT "SBWM_A1_PKT";
BA_ "FlexKomComment" SG_ 762 SHFT_SENS_FLT "Shift by wire A1 packet";
BA_ "FlexKomIsMotorola" SG_ 762 SHFT_SENS_FLT 1;
BA_ "GenSigSNA" SG_ 762 SHFT_SENS_FLT "0h";
BA_ "GenSigCycleTime" SG_ 762 ShftDispFlt 20;
BA_ "FlexKomSigStartValue" SG_ 762 ShftDispFlt "F04C0000FFh";
BA_ "FlexKomSID" SG_ 762 ShftDispFlt 1372;
BA_ "FlexKomSigStartPos" SG_ 762 ShftDispFlt 7;
BA_ "FlexKomSigLaenge" SG_ 762 ShftDispFlt 40;
BA_ "FlexKomSigName" SG_ 762 ShftDispFlt "SBWM_A1_PKT";
BA_ "FlexKomComment" SG_ 762 ShftDispFlt "Shift by wire A1 packet";
BA_ "FlexKomIsMotorola" SG_ 762 ShftDispFlt 1;
BA_ "GenSigSNA" SG_ 762 ShftDispFlt "0h";
BA_ "GenSigCycleTime" SG_ 762 DRV_RQ_LKOUT 20;
BA_ "FlexKomSigStartValue" SG_ 762 DRV_RQ_LKOUT "F04C0000FFh";
BA_ "GenSigStartValue" SG_ 762 DRV_RQ_LKOUT 3;
BA_ "FlexKomSID" SG_ 762 DRV_RQ_LKOUT 1372;
BA_ "FlexKomSigStartPos" SG_ 762 DRV_RQ_LKOUT 7;
BA_ "FlexKomSigLaenge" SG_ 762 DRV_RQ_LKOUT 40;
BA_ "FlexKomSigName" SG_ 762 DRV_RQ_LKOUT "SBWM_A1_PKT";
BA_ "FlexKomComment" SG_ 762 DRV_RQ_LKOUT "Shift by wire A1 packet";
BA_ "FlexKomIsMotorola" SG_ 762 DRV_RQ_LKOUT 1;
BA_ "GenSigSNA" SG_ 762 DRV_RQ_LKOUT "3h";
BA_ "GenSigCycleTime" SG_ 762 SHFT_LOCK_FLT 20;
BA_ "FlexKomSigStartValue" SG_ 762 SHFT_LOCK_FLT "F04C0000FFh";
BA_ "FlexKomSID" SG_ 762 SHFT_LOCK_FLT 1372;
BA_ "FlexKomSigStartPos" SG_ 762 SHFT_LOCK_FLT 7;
BA_ "FlexKomSigLaenge" SG_ 762 SHFT_LOCK_FLT 40;
BA_ "FlexKomSigName" SG_ 762 SHFT_LOCK_FLT "SBWM_A1_PKT";
BA_ "FlexKomComment" SG_ 762 SHFT_LOCK_FLT "Shift by wire A1 packet";
BA_ "FlexKomIsMotorola" SG_ 762 SHFT_LOCK_FLT 1;
BA_ "GenSigSNA" SG_ 762 SHFT_LOCK_FLT "0h";
BA_ "GenSigCycleTime" SG_ 762 SHFT_HS_SBWM_VALID 20;
BA_ "FlexKomSigStartValue" SG_ 762 SHFT_HS_SBWM_VALID "F04C0000FFh";
BA_ "FlexKomSID" SG_ 762 SHFT_HS_SBWM_VALID 1372;
BA_ "FlexKomSigStartPos" SG_ 762 SHFT_HS_SBWM_VALID 7;
BA_ "FlexKomSigLaenge" SG_ 762 SHFT_HS_SBWM_VALID 40;
BA_ "FlexKomSigName" SG_ 762 SHFT_HS_SBWM_VALID "SBWM_A1_PKT";
BA_ "FlexKomComment" SG_ 762 SHFT_HS_SBWM_VALID "Shift by wire A1 packet";
BA_ "FlexKomIsMotorola" SG_ 762 SHFT_HS_SBWM_VALID 1;
BA_ "GenSigSNA" SG_ 762 SHFT_HS_SBWM_VALID "0h";
BA_ "GenSigCycleTime" SG_ 762 SHFT_RET_FLT 20;
BA_ "FlexKomSigStartValue" SG_ 762 SHFT_RET_FLT "F04C0000FFh";
BA_ "GenSigStartValue" SG_ 762 SHFT_RET_FLT 1;
BA_ "FlexKomSID" SG_ 762 SHFT_RET_FLT 1372;
BA_ "FlexKomSigStartPos" SG_ 762 SHFT_RET_FLT 7;
BA_ "FlexKomSigLaenge" SG_ 762 SHFT_RET_FLT 40;
BA_ "FlexKomSigName" SG_ 762 SHFT_RET_FLT "SBWM_A1_PKT";
BA_ "FlexKomComment" SG_ 762 SHFT_RET_FLT "Shift by wire A1 packet";
BA_ "FlexKomIsMotorola" SG_ 762 SHFT_RET_FLT 1;
BA_ "GenSigSNA" SG_ 762 SHFT_RET_FLT "3h";
BA_ "GenSigCycleTime" SG_ 762 Shft_HS_SBWM 20;
BA_ "FlexKomSigStartValue" SG_ 762 Shft_HS_SBWM "F04C0000FFh";
BA_ "FlexKomSID" SG_ 762 Shft_HS_SBWM 1372;
BA_ "FlexKomSigStartPos" SG_ 762 Shft_HS_SBWM 7;
BA_ "FlexKomSigLaenge" SG_ 762 Shft_HS_SBWM 40;
BA_ "FlexKomSigName" SG_ 762 Shft_HS_SBWM "SBWM_A1_PKT";
BA_ "FlexKomComment" SG_ 762 Shft_HS_SBWM "Shift by wire A1 packet";
BA_ "FlexKomIsMotorola" SG_ 762 Shft_HS_SBWM 1;
BA_ "GenSigSNA" SG_ 762 Shft_HS_SBWM "0h";
BA_ "GenSigCycleTime" SG_ 762 MC_SBWM_A1 20;
BA_ "FlexKomSigStartValue" SG_ 762 MC_SBWM_A1 "F04C0000FFh";
BA_ "FlexKomSID" SG_ 762 MC_SBWM_A1 1372;
BA_ "FlexKomSigStartPos" SG_ 762 MC_SBWM_A1 7;
BA_ "FlexKomSigLaenge" SG_ 762 MC_SBWM_A1 40;
BA_ "FlexKomSigName" SG_ 762 MC_SBWM_A1 "SBWM_A1_PKT";
BA_ "FlexKomComment" SG_ 762 MC_SBWM_A1 "Shift by wire A1 packet";
BA_ "FlexKomIsMotorola" SG_ 762 MC_SBWM_A1 1;
BA_ "GenSigSNA" SG_ 762 MC_SBWM_A1 "0h";
BA_ "GenSigCycleTime" SG_ 762 CRC_SBWM_A1 20;
BA_ "FlexKomSigStartValue" SG_ 762 CRC_SBWM_A1 "F04C0000FFh";
BA_ "GenSigStartValue" SG_ 762 CRC_SBWM_A1 255;
BA_ "FlexKomSID" SG_ 762 CRC_SBWM_A1 1372;
BA_ "FlexKomSigStartPos" SG_ 762 CRC_SBWM_A1 7;
BA_ "FlexKomSigLaenge" SG_ 762 CRC_SBWM_A1 40;
BA_ "FlexKomSigName" SG_ 762 CRC_SBWM_A1 "SBWM_A1_PKT";
BA_ "FlexKomComment" SG_ 762 CRC_SBWM_A1 "Shift by wire A1 packet";
BA_ "FlexKomIsMotorola" SG_ 762 CRC_SBWM_A1 1;
BA_ "GenSigSNA" SG_ 762 CRC_SBWM_A1 "FFh";
BA_ "GenSigCycleTime" SG_ 764 ApplyTrq 100;
BA_ "FlexKomSigStartValue" SG_ 764 ApplyTrq "00FFFFFFFFFFFFFFh";
BA_ "GenSigTimeout_ORC" SG_ 764 ApplyTrq 350;
BA_ "FlexKomSID" SG_ 764 ApplyTrq 762;
BA_ "FlexKomSigStartPos" SG_ 764 ApplyTrq 7;
BA_ "FlexKomSigLaenge" SG_ 764 ApplyTrq 64;
BA_ "FlexKomSigName" SG_ 764 ApplyTrq "EDR_Pkt";
BA_ "FlexKomComment" SG_ 764 ApplyTrq "EDR Only information packet";
BA_ "FlexKomIsMotorola" SG_ 764 ApplyTrq 1;
BA_ "GenSigSNA" SG_ 764 ApplyTrq "0h";
BA_ "GenSigCycleTime" SG_ 764 BrkSw1Stat 100;
BA_ "FlexKomSigStartValue" SG_ 764 BrkSw1Stat "00FFFFFFFFFFFFFFh";
BA_ "FlexKomSID" SG_ 764 BrkSw1Stat 762;
BA_ "FlexKomSigStartPos" SG_ 764 BrkSw1Stat 7;
BA_ "FlexKomSigLaenge" SG_ 764 BrkSw1Stat 64;
BA_ "FlexKomSigName" SG_ 764 BrkSw1Stat "EDR_Pkt";
BA_ "FlexKomComment" SG_ 764 BrkSw1Stat "EDR Only information packet";
BA_ "FlexKomIsMotorola" SG_ 764 BrkSw1Stat 1;
BA_ "GenSigSNA" SG_ 764 BrkSw1Stat "0h";
BA_ "GenSigCycleTime" SG_ 764 ESP_TrqRqEnabl 100;
BA_ "FlexKomSigStartValue" SG_ 764 ESP_TrqRqEnabl "00FFFFFFFFFFFFFFh";
BA_ "GenSigTimeout_ORC" SG_ 764 ESP_TrqRqEnabl 350;
BA_ "FlexKomSID" SG_ 764 ESP_TrqRqEnabl 762;
BA_ "FlexKomSigStartPos" SG_ 764 ESP_TrqRqEnabl 7;
BA_ "FlexKomSigLaenge" SG_ 764 ESP_TrqRqEnabl 64;
BA_ "FlexKomSigName" SG_ 764 ESP_TrqRqEnabl "EDR_Pkt";
BA_ "FlexKomComment" SG_ 764 ESP_TrqRqEnabl "EDR Only information packet";
BA_ "FlexKomIsMotorola" SG_ 764 ESP_TrqRqEnabl 1;
BA_ "GenSigSNA" SG_ 764 ESP_TrqRqEnabl "0h";
BA_ "GenSigCycleTime" SG_ 764 ETC_LmpFlash 100;
BA_ "FlexKomSigStartValue" SG_ 764 ETC_LmpFlash "00FFFFFFFFFFFFFFh";
BA_ "GenSigTimeout_ORC" SG_ 764 ETC_LmpFlash 350;
BA_ "FlexKomSID" SG_ 764 ETC_LmpFlash 762;
BA_ "FlexKomSigStartPos" SG_ 764 ETC_LmpFlash 7;
BA_ "FlexKomSigLaenge" SG_ 764 ETC_LmpFlash 64;
BA_ "FlexKomSigName" SG_ 764 ETC_LmpFlash "EDR_Pkt";
BA_ "FlexKomComment" SG_ 764 ETC_LmpFlash "EDR Only information packet";
BA_ "FlexKomIsMotorola" SG_ 764 ETC_LmpFlash 1;
BA_ "GenSigSNA" SG_ 764 ETC_LmpFlash "0h";
BA_ "GenSigCycleTime" SG_ 764 ETC_LmpOn 100;
BA_ "FlexKomSigStartValue" SG_ 764 ETC_LmpOn "00FFFFFFFFFFFFFFh";
BA_ "GenSigTimeout_ORC" SG_ 764 ETC_LmpOn 350;
BA_ "FlexKomSID" SG_ 764 ETC_LmpOn 762;
BA_ "FlexKomSigStartPos" SG_ 764 ETC_LmpOn 7;
BA_ "FlexKomSigLaenge" SG_ 764 ETC_LmpOn 64;
BA_ "FlexKomSigName" SG_ 764 ETC_LmpOn "EDR_Pkt";
BA_ "FlexKomComment" SG_ 764 ETC_LmpOn "EDR Only information packet";
BA_ "FlexKomIsMotorola" SG_ 764 ETC_LmpOn 1;
BA_ "GenSigSNA" SG_ 764 ETC_LmpOn "0h";
BA_ "GenSigCycleTime" SG_ 764 Lv1CrsCtrlOff 100;
BA_ "FlexKomSigStartValue" SG_ 764 Lv1CrsCtrlOff "00FFFFFFFFFFFFFFh";
BA_ "GenSigTimeout_ORC" SG_ 764 Lv1CrsCtrlOff 350;
BA_ "FlexKomSID" SG_ 764 Lv1CrsCtrlOff 762;
BA_ "FlexKomSigStartPos" SG_ 764 Lv1CrsCtrlOff 7;
BA_ "FlexKomSigLaenge" SG_ 764 Lv1CrsCtrlOff 64;
BA_ "FlexKomSigName" SG_ 764 Lv1CrsCtrlOff "EDR_Pkt";
BA_ "FlexKomComment" SG_ 764 Lv1CrsCtrlOff "EDR Only information packet";
BA_ "FlexKomIsMotorola" SG_ 764 Lv1CrsCtrlOff 1;
BA_ "GenSigSNA" SG_ 764 Lv1CrsCtrlOff "0h";
BA_ "GenSigCycleTime" SG_ 764 CruiseEGD 100;
BA_ "FlexKomSigStartValue" SG_ 764 CruiseEGD "00FFFFFFFFFFFFFFh";
BA_ "GenSigTimeout_ORC" SG_ 764 CruiseEGD 350;
BA_ "FlexKomSID" SG_ 764 CruiseEGD 762;
BA_ "FlexKomSigStartPos" SG_ 764 CruiseEGD 7;
BA_ "FlexKomSigLaenge" SG_ 764 CruiseEGD 64;
BA_ "FlexKomSigName" SG_ 764 CruiseEGD "EDR_Pkt";
BA_ "FlexKomComment" SG_ 764 CruiseEGD "EDR Only information packet";
BA_ "FlexKomIsMotorola" SG_ 764 CruiseEGD 1;
BA_ "GenSigSNA" SG_ 764 CruiseEGD "0h";
BA_ "GenSigCycleTime" SG_ 764 RawPVS1 100;
BA_ "FlexKomSigStartValue" SG_ 764 RawPVS1 "00FFFFFFFFFFFFFFh";
BA_ "GenSigStartValue" SG_ 764 RawPVS1 255;
BA_ "GenSigTimeout_ORC" SG_ 764 RawPVS1 350;
BA_ "FlexKomSID" SG_ 764 RawPVS1 762;
BA_ "FlexKomSigStartPos" SG_ 764 RawPVS1 7;
BA_ "FlexKomSigLaenge" SG_ 764 RawPVS1 64;
BA_ "FlexKomSigName" SG_ 764 RawPVS1 "EDR_Pkt";
BA_ "FlexKomComment" SG_ 764 RawPVS1 "EDR Only information packet";
BA_ "FlexKomIsMotorola" SG_ 764 RawPVS1 1;
BA_ "GenSigSNA" SG_ 764 RawPVS1 "FFh";
BA_ "GenSigCycleTime" SG_ 764 RawPVS2 100;
BA_ "FlexKomSigStartValue" SG_ 764 RawPVS2 "00FFFFFFFFFFFFFFh";
BA_ "GenSigStartValue" SG_ 764 RawPVS2 255;
BA_ "GenSigTimeout_ORC" SG_ 764 RawPVS2 350;
BA_ "FlexKomSID" SG_ 764 RawPVS2 762;
BA_ "FlexKomSigStartPos" SG_ 764 RawPVS2 7;
BA_ "FlexKomSigLaenge" SG_ 764 RawPVS2 64;
BA_ "FlexKomSigName" SG_ 764 RawPVS2 "EDR_Pkt";
BA_ "FlexKomComment" SG_ 764 RawPVS2 "EDR Only information packet";
BA_ "FlexKomIsMotorola" SG_ 764 RawPVS2 1;
BA_ "GenSigSNA" SG_ 764 RawPVS2 "FFh";
BA_ "GenSigCycleTime" SG_ 764 RawTPS1 100;
BA_ "FlexKomSigStartValue" SG_ 764 RawTPS1 "00FFFFFFFFFFFFFFh";
BA_ "GenSigStartValue" SG_ 764 RawTPS1 255;
BA_ "GenSigTimeout_ORC" SG_ 764 RawTPS1 350;
BA_ "FlexKomSID" SG_ 764 RawTPS1 762;
BA_ "FlexKomSigStartPos" SG_ 764 RawTPS1 7;
BA_ "FlexKomSigLaenge" SG_ 764 RawTPS1 64;
BA_ "FlexKomSigName" SG_ 764 RawTPS1 "EDR_Pkt";
BA_ "FlexKomComment" SG_ 764 RawTPS1 "EDR Only information packet";
BA_ "FlexKomIsMotorola" SG_ 764 RawTPS1 1;
BA_ "GenSigSNA" SG_ 764 RawTPS1 "FFh";
BA_ "GenSigCycleTime" SG_ 764 RawTPS2 100;
BA_ "FlexKomSigStartValue" SG_ 764 RawTPS2 "00FFFFFFFFFFFFFFh";
BA_ "GenSigStartValue" SG_ 764 RawTPS2 255;
BA_ "GenSigTimeout_ORC" SG_ 764 RawTPS2 350;
BA_ "FlexKomSID" SG_ 764 RawTPS2 762;
BA_ "FlexKomSigStartPos" SG_ 764 RawTPS2 7;
BA_ "FlexKomSigLaenge" SG_ 764 RawTPS2 64;
BA_ "FlexKomSigName" SG_ 764 RawTPS2 "EDR_Pkt";
BA_ "FlexKomComment" SG_ 764 RawTPS2 "EDR Only information packet";
BA_ "FlexKomIsMotorola" SG_ 764 RawTPS2 1;
BA_ "GenSigSNA" SG_ 764 RawTPS2 "FFh";
BA_ "GenSigCycleTime" SG_ 764 RelativePdl 100;
BA_ "FlexKomSigStartValue" SG_ 764 RelativePdl "00FFFFFFFFFFFFFFh";
BA_ "GenSigStartValue" SG_ 764 RelativePdl 255;
BA_ "GenSigTimeout_ORC" SG_ 764 RelativePdl 350;
BA_ "FlexKomSID" SG_ 764 RelativePdl 762;
BA_ "FlexKomSigStartPos" SG_ 764 RelativePdl 7;
BA_ "FlexKomSigLaenge" SG_ 764 RelativePdl 64;
BA_ "FlexKomSigName" SG_ 764 RelativePdl "EDR_Pkt";
BA_ "FlexKomComment" SG_ 764 RelativePdl "EDR Only information packet";
BA_ "FlexKomIsMotorola" SG_ 764 RelativePdl 1;
BA_ "GenSigSNA" SG_ 764 RelativePdl "FFh";
BA_ "GenSigCycleTime" SG_ 764 RelativeThrt 100;
BA_ "FlexKomSigStartValue" SG_ 764 RelativeThrt "00FFFFFFFFFFFFFFh";
BA_ "GenSigStartValue" SG_ 764 RelativeThrt 255;
BA_ "GenSigTimeout_ORC" SG_ 764 RelativeThrt 350;
BA_ "FlexKomSID" SG_ 764 RelativeThrt 762;
BA_ "FlexKomSigStartPos" SG_ 764 RelativeThrt 7;
BA_ "FlexKomSigLaenge" SG_ 764 RelativeThrt 64;
BA_ "FlexKomSigName" SG_ 764 RelativeThrt "EDR_Pkt";
BA_ "FlexKomComment" SG_ 764 RelativeThrt "EDR Only information packet";
BA_ "FlexKomIsMotorola" SG_ 764 RelativeThrt 1;
BA_ "GenSigSNA" SG_ 764 RelativeThrt "FFh";
BA_ "GenSigCycleTime" SG_ 764 MAP 100;
BA_ "FlexKomSigStartValue" SG_ 764 MAP "00FFFFFFFFFFFFFFh";
BA_ "GenSigStartValue" SG_ 764 MAP 255;
BA_ "GenSigTimeout_ORC" SG_ 764 MAP 350;
BA_ "FlexKomSID" SG_ 764 MAP 762;
BA_ "FlexKomSigStartPos" SG_ 764 MAP 7;
BA_ "FlexKomSigLaenge" SG_ 764 MAP 64;
BA_ "FlexKomSigName" SG_ 764 MAP "EDR_Pkt";
BA_ "FlexKomComment" SG_ 764 MAP "EDR Only information packet";
BA_ "FlexKomIsMotorola" SG_ 764 MAP 1;
BA_ "GenSigSNA" SG_ 764 MAP "FFh";
BA_ "GenSigCycleTime" SG_ 766 VVT_ExhCam1Pos 100;
BA_ "FlexKomSigStartValue" SG_ 766 VVT_ExhCam1Pos "FFFFFFFF0000FF00h";
BA_ "GenSigStartValue" SG_ 766 VVT_ExhCam1Pos 255;
BA_ "GenSigTimeout_ORC" SG_ 766 VVT_ExhCam1Pos 350;
BA_ "FlexKomSID" SG_ 766 VVT_ExhCam1Pos 1093;
BA_ "FlexKomSigStartPos" SG_ 766 VVT_ExhCam1Pos 7;
BA_ "FlexKomSigLaenge" SG_ 766 VVT_ExhCam1Pos 64;
BA_ "FlexKomSigName" SG_ 766 VVT_ExhCam1Pos "EDR2_Pkt";
BA_ "FlexKomComment" SG_ 766 VVT_ExhCam1Pos "EDR2 information packet only";
BA_ "FlexKomIsMotorola" SG_ 766 VVT_ExhCam1Pos 1;
BA_ "GenSigSNA" SG_ 766 VVT_ExhCam1Pos "0h";
BA_ "GenSigCycleTime" SG_ 766 VVT_ExhCam2Pos 100;
BA_ "FlexKomSigStartValue" SG_ 766 VVT_ExhCam2Pos "FFFFFFFF0000FF00h";
BA_ "GenSigStartValue" SG_ 766 VVT_ExhCam2Pos 255;
BA_ "GenSigTimeout_ORC" SG_ 766 VVT_ExhCam2Pos 350;
BA_ "FlexKomSID" SG_ 766 VVT_ExhCam2Pos 1093;
BA_ "FlexKomSigStartPos" SG_ 766 VVT_ExhCam2Pos 7;
BA_ "FlexKomSigLaenge" SG_ 766 VVT_ExhCam2Pos 64;
BA_ "FlexKomSigName" SG_ 766 VVT_ExhCam2Pos "EDR2_Pkt";
BA_ "FlexKomComment" SG_ 766 VVT_ExhCam2Pos "EDR2 information packet only";
BA_ "FlexKomIsMotorola" SG_ 766 VVT_ExhCam2Pos 1;
BA_ "GenSigSNA" SG_ 766 VVT_ExhCam2Pos "0h";
BA_ "GenSigCycleTime" SG_ 766 VVT_IntCam1Pos 100;
BA_ "FlexKomSigStartValue" SG_ 766 VVT_IntCam1Pos "FFFFFFFF0000FF00h";
BA_ "GenSigStartValue" SG_ 766 VVT_IntCam1Pos 255;
BA_ "GenSigTimeout_ORC" SG_ 766 VVT_IntCam1Pos 350;
BA_ "FlexKomSID" SG_ 766 VVT_IntCam1Pos 1093;
BA_ "FlexKomSigStartPos" SG_ 766 VVT_IntCam1Pos 7;
BA_ "FlexKomSigLaenge" SG_ 766 VVT_IntCam1Pos 64;
BA_ "FlexKomSigName" SG_ 766 VVT_IntCam1Pos "EDR2_Pkt";
BA_ "FlexKomComment" SG_ 766 VVT_IntCam1Pos "EDR2 information packet only";
BA_ "FlexKomIsMotorola" SG_ 766 VVT_IntCam1Pos 1;
BA_ "GenSigSNA" SG_ 766 VVT_IntCam1Pos "0h";
BA_ "GenSigCycleTime" SG_ 766 VVT_IntCam2Pos 100;
BA_ "FlexKomSigStartValue" SG_ 766 VVT_IntCam2Pos "FFFFFFFF0000FF00h";
BA_ "GenSigStartValue" SG_ 766 VVT_IntCam2Pos 255;
BA_ "GenSigTimeout_ORC" SG_ 766 VVT_IntCam2Pos 350;
BA_ "FlexKomSID" SG_ 766 VVT_IntCam2Pos 1093;
BA_ "FlexKomSigStartPos" SG_ 766 VVT_IntCam2Pos 7;
BA_ "FlexKomSigLaenge" SG_ 766 VVT_IntCam2Pos 64;
BA_ "FlexKomSigName" SG_ 766 VVT_IntCam2Pos "EDR2_Pkt";
BA_ "FlexKomComment" SG_ 766 VVT_IntCam2Pos "EDR2 information packet only";
BA_ "FlexKomIsMotorola" SG_ 766 VVT_IntCam2Pos 1;
BA_ "GenSigSNA" SG_ 766 VVT_IntCam2Pos "0h";
BA_ "GenSigCycleTime" SG_ 766 GF_Charge 100;
BA_ "FlexKomSigStartValue" SG_ 766 GF_Charge "FFFFFFFF0000FF00h";
BA_ "GenSigTimeout_ORC" SG_ 766 GF_Charge 350;
BA_ "FlexKomSID" SG_ 766 GF_Charge 1093;
BA_ "FlexKomSigStartPos" SG_ 766 GF_Charge 7;
BA_ "FlexKomSigLaenge" SG_ 766 GF_Charge 64;
BA_ "FlexKomSigName" SG_ 766 GF_Charge "EDR2_Pkt";
BA_ "FlexKomComment" SG_ 766 GF_Charge "EDR2 information packet only";
BA_ "FlexKomIsMotorola" SG_ 766 GF_Charge 1;
BA_ "GenSigSNA" SG_ 766 GF_Charge "FFFFh";
BA_ "GenSigCycleTime" SG_ 766 RelativeThrtPct 100;
BA_ "FlexKomSigStartValue" SG_ 766 RelativeThrtPct "FFFFFFFF0000FF00h";
BA_ "GenSigStartValue" SG_ 766 RelativeThrtPct 255;
BA_ "GenSigTimeout_ORC" SG_ 766 RelativeThrtPct 350;
BA_ "FlexKomSID" SG_ 766 RelativeThrtPct 1093;
BA_ "FlexKomSigStartPos" SG_ 766 RelativeThrtPct 7;
BA_ "FlexKomSigLaenge" SG_ 766 RelativeThrtPct 64;
BA_ "FlexKomSigName" SG_ 766 RelativeThrtPct "EDR2_Pkt";
BA_ "FlexKomComment" SG_ 766 RelativeThrtPct "EDR2 information packet only";
BA_ "FlexKomIsMotorola" SG_ 766 RelativeThrtPct 1;
BA_ "GenSigSNA" SG_ 766 RelativeThrtPct "FFh";
BA_ "GenSigCycleTime" SG_ 769 EPB_BtnStat 100;
BA_ "FlexKomSigStartValue" SG_ 769 EPB_BtnStat "00020700000000FFh";
BA_ "FlexKomSID" SG_ 769 EPB_BtnStat 1650;
BA_ "FlexKomSigStartPos" SG_ 769 EPB_BtnStat 7;
BA_ "FlexKomSigLaenge" SG_ 769 EPB_BtnStat 64;
BA_ "FlexKomSigName" SG_ 769 EPB_BtnStat "EPB_1M_Pkt";
BA_ "FlexKomComment" SG_ 769 EPB_BtnStat "Electric parking brake packet";
BA_ "FlexKomIsMotorola" SG_ 769 EPB_BtnStat 1;
BA_ "GenSigSNA" SG_ 769 EPB_BtnStat "0h";
BA_ "GenSigCycleTime" SG_ 769 SrvLmpRq 100;
BA_ "FlexKomSigStartValue" SG_ 769 SrvLmpRq "00020700000000FFh";
BA_ "FlexKomSID" SG_ 769 SrvLmpRq 1650;
BA_ "FlexKomSigStartPos" SG_ 769 SrvLmpRq 7;
BA_ "FlexKomSigLaenge" SG_ 769 SrvLmpRq 64;
BA_ "FlexKomSigName" SG_ 769 SrvLmpRq "EPB_1M_Pkt";
BA_ "FlexKomComment" SG_ 769 SrvLmpRq "Electric parking brake packet";
BA_ "FlexKomIsMotorola" SG_ 769 SrvLmpRq 1;
BA_ "GenSigSNA" SG_ 769 SrvLmpRq "3h";
BA_ "GenSigCycleTime" SG_ 769 WrnLmpRq 100;
BA_ "FlexKomSigStartValue" SG_ 769 WrnLmpRq "00020700000000FFh";
BA_ "GenSigTimeout_ORC" SG_ 769 WrnLmpRq 350;
BA_ "FlexKomSID" SG_ 769 WrnLmpRq 1650;
BA_ "FlexKomSigStartPos" SG_ 769 WrnLmpRq 7;
BA_ "FlexKomSigLaenge" SG_ 769 WrnLmpRq 64;
BA_ "FlexKomSigName" SG_ 769 WrnLmpRq "EPB_1M_Pkt";
BA_ "FlexKomComment" SG_ 769 WrnLmpRq "Electric parking brake packet";
BA_ "FlexKomIsMotorola" SG_ 769 WrnLmpRq 1;
BA_ "GenSigSNA" SG_ 769 WrnLmpRq "3h";
BA_ "GenSigCycleTime" SG_ 769 EPB_DsblEnbl 100;
BA_ "FlexKomSigStartValue" SG_ 769 EPB_DsblEnbl "00020700000000FFh";
BA_ "GenSigStartValue" SG_ 769 EPB_DsblEnbl 2;
BA_ "FlexKomSID" SG_ 769 EPB_DsblEnbl 1650;
BA_ "FlexKomSigStartPos" SG_ 769 EPB_DsblEnbl 7;
BA_ "FlexKomSigLaenge" SG_ 769 EPB_DsblEnbl 64;
BA_ "FlexKomSigName" SG_ 769 EPB_DsblEnbl "EPB_1M_Pkt";
BA_ "FlexKomComment" SG_ 769 EPB_DsblEnbl "Electric parking brake packet";
BA_ "FlexKomIsMotorola" SG_ 769 EPB_DsblEnbl 1;
BA_ "GenSigSNA" SG_ 769 EPB_DsblEnbl "2h";
BA_ "GenSigCycleTime" SG_ 769 PrkBrkStat 100;
BA_ "FlexKomSigStartValue" SG_ 769 PrkBrkStat "00020700000000FFh";
BA_ "GenSigStartValue" SG_ 769 PrkBrkStat 7;
BA_ "GenSigTimeout_RF_HUB" SG_ 769 PrkBrkStat 1050;
BA_ "GenSigTimeout_CBC" SG_ 769 PrkBrkStat 1050;
BA_ "GenSigTimeout_ORC" SG_ 769 PrkBrkStat 350;
BA_ "FlexKomSID" SG_ 769 PrkBrkStat 1650;
BA_ "FlexKomSigStartPos" SG_ 769 PrkBrkStat 7;
BA_ "FlexKomSigLaenge" SG_ 769 PrkBrkStat 64;
BA_ "FlexKomSigName" SG_ 769 PrkBrkStat "EPB_1M_Pkt";
BA_ "FlexKomComment" SG_ 769 PrkBrkStat "Electric parking brake packet";
BA_ "FlexKomIsMotorola" SG_ 769 PrkBrkStat 1;
BA_ "GenSigSNA" SG_ 769 PrkBrkStat "7h";
BA_ "GenSigCycleTime" SG_ 769 DynBrkDispRq 100;
BA_ "FlexKomSigStartValue" SG_ 769 DynBrkDispRq "00020700000000FFh";
BA_ "FlexKomSID" SG_ 769 DynBrkDispRq 1650;
BA_ "FlexKomSigStartPos" SG_ 769 DynBrkDispRq 7;
BA_ "FlexKomSigLaenge" SG_ 769 DynBrkDispRq 64;
BA_ "FlexKomSigName" SG_ 769 DynBrkDispRq "EPB_1M_Pkt";
BA_ "FlexKomComment" SG_ 769 DynBrkDispRq "Electric parking brake packet";
BA_ "FlexKomIsMotorola" SG_ 769 DynBrkDispRq 1;
BA_ "GenSigSNA" SG_ 769 DynBrkDispRq "0h";
BA_ "GenSigCycleTime" SG_ 769 AutoAplyActv 100;
BA_ "FlexKomSigStartValue" SG_ 769 AutoAplyActv "00020700000000FFh";
BA_ "FlexKomSID" SG_ 769 AutoAplyActv 1650;
BA_ "FlexKomSigStartPos" SG_ 769 AutoAplyActv 7;
BA_ "FlexKomSigLaenge" SG_ 769 AutoAplyActv 64;
BA_ "FlexKomSigName" SG_ 769 AutoAplyActv "EPB_1M_Pkt";
BA_ "FlexKomComment" SG_ 769 AutoAplyActv "Electric parking brake packet";
BA_ "FlexKomIsMotorola" SG_ 769 AutoAplyActv 1;
BA_ "GenSigSNA" SG_ 769 AutoAplyActv "0h";
BA_ "GenSigCycleTime" SG_ 769 MC_EPB_1M 100;
BA_ "FlexKomSigStartValue" SG_ 769 MC_EPB_1M "00020700000000FFh";
BA_ "FlexKomSID" SG_ 769 MC_EPB_1M 1650;
BA_ "FlexKomSigStartPos" SG_ 769 MC_EPB_1M 7;
BA_ "FlexKomSigLaenge" SG_ 769 MC_EPB_1M 64;
BA_ "FlexKomSigName" SG_ 769 MC_EPB_1M "EPB_1M_Pkt";
BA_ "FlexKomComment" SG_ 769 MC_EPB_1M "Electric parking brake packet";
BA_ "FlexKomIsMotorola" SG_ 769 MC_EPB_1M 1;
BA_ "GenSigSNA" SG_ 769 MC_EPB_1M "0h";
BA_ "GenSigCycleTime" SG_ 769 CRC_EPB_1M 100;
BA_ "FlexKomSigStartValue" SG_ 769 CRC_EPB_1M "00020700000000FFh";
BA_ "GenSigStartValue" SG_ 769 CRC_EPB_1M 255;
BA_ "FlexKomSID" SG_ 769 CRC_EPB_1M 1650;
BA_ "FlexKomSigStartPos" SG_ 769 CRC_EPB_1M 7;
BA_ "FlexKomSigLaenge" SG_ 769 CRC_EPB_1M 64;
BA_ "FlexKomSigName" SG_ 769 CRC_EPB_1M "EPB_1M_Pkt";
BA_ "FlexKomComment" SG_ 769 CRC_EPB_1M "Electric parking brake packet";
BA_ "FlexKomIsMotorola" SG_ 769 CRC_EPB_1M 1;
BA_ "GenSigSNA" SG_ 769 CRC_EPB_1M "FFh";
BA_ "GenSigCycleTime" SG_ 770 ClampForce 100;
BA_ "FlexKomSigStartValue" SG_ 770 ClampForce "00000000000000FFh";
BA_ "GenSigTimeout_ORC" SG_ 770 ClampForce 350;
BA_ "FlexKomSID" SG_ 770 ClampForce 2083;
BA_ "FlexKomSigStartPos" SG_ 770 ClampForce 7;
BA_ "FlexKomSigLaenge" SG_ 770 ClampForce 64;
BA_ "FlexKomSigName" SG_ 770 ClampForce "EPB_1";
BA_ "FlexKomComment" SG_ 770 ClampForce "EPB_1 message packet";
BA_ "FlexKomIsMotorola" SG_ 770 ClampForce 1;
BA_ "GenSigSNA" SG_ 770 ClampForce "0h";
BA_ "GenSigCycleTime" SG_ 770 StopLampActive 100;
BA_ "FlexKomSigStartValue" SG_ 770 StopLampActive "00000000000000FFh";
BA_ "FlexKomSID" SG_ 770 StopLampActive 2083;
BA_ "FlexKomSigStartPos" SG_ 770 StopLampActive 7;
BA_ "FlexKomSigLaenge" SG_ 770 StopLampActive 64;
BA_ "FlexKomSigName" SG_ 770 StopLampActive "EPB_1";
BA_ "FlexKomComment" SG_ 770 StopLampActive "EPB_1 message packet";
BA_ "FlexKomIsMotorola" SG_ 770 StopLampActive 1;
BA_ "GenSigSNA" SG_ 770 StopLampActive "3h";
BA_ "GenSigCycleTime" SG_ 770 FaultStoreInfo 100;
BA_ "FlexKomSigStartValue" SG_ 770 FaultStoreInfo "00000000000000FFh";
BA_ "FlexKomSID" SG_ 770 FaultStoreInfo 2083;
BA_ "FlexKomSigStartPos" SG_ 770 FaultStoreInfo 7;
BA_ "FlexKomSigLaenge" SG_ 770 FaultStoreInfo 64;
BA_ "FlexKomSigName" SG_ 770 FaultStoreInfo "EPB_1";
BA_ "FlexKomComment" SG_ 770 FaultStoreInfo "EPB_1 message packet";
BA_ "FlexKomIsMotorola" SG_ 770 FaultStoreInfo 1;
BA_ "GenSigSNA" SG_ 770 FaultStoreInfo "0h";
BA_ "GenSigCycleTime" SG_ 770 EPBSwitchPosition 100;
BA_ "FlexKomSigStartValue" SG_ 770 EPBSwitchPosition "00000000000000FFh";
BA_ "GenSigTimeout_ORC" SG_ 770 EPBSwitchPosition 350;
BA_ "FlexKomSID" SG_ 770 EPBSwitchPosition 2083;
BA_ "FlexKomSigStartPos" SG_ 770 EPBSwitchPosition 7;
BA_ "FlexKomSigLaenge" SG_ 770 EPBSwitchPosition 64;
BA_ "FlexKomSigName" SG_ 770 EPBSwitchPosition "EPB_1";
BA_ "FlexKomComment" SG_ 770 EPBSwitchPosition "EPB_1 message packet";
BA_ "FlexKomIsMotorola" SG_ 770 EPBSwitchPosition 1;
BA_ "GenSigSNA" SG_ 770 EPBSwitchPosition "3h";
BA_ "GenSigCycleTime" SG_ 770 EPBSts 100;
BA_ "FlexKomSigStartValue" SG_ 770 EPBSts "00000000000000FFh";
BA_ "GenSigTimeout_ORC" SG_ 770 EPBSts 350;
BA_ "FlexKomSID" SG_ 770 EPBSts 2083;
BA_ "FlexKomSigStartPos" SG_ 770 EPBSts 7;
BA_ "FlexKomSigLaenge" SG_ 770 EPBSts 64;
BA_ "FlexKomSigName" SG_ 770 EPBSts "EPB_1";
BA_ "FlexKomComment" SG_ 770 EPBSts "EPB_1 message packet";
BA_ "FlexKomIsMotorola" SG_ 770 EPBSts 1;
BA_ "GenSigSNA" SG_ 770 EPBSts "0h";
BA_ "GenSigCycleTime" SG_ 770 AutoParkSts 100;
BA_ "FlexKomSigStartValue" SG_ 770 AutoParkSts "00000000000000FFh";
BA_ "FlexKomSID" SG_ 770 AutoParkSts 2083;
BA_ "FlexKomSigStartPos" SG_ 770 AutoParkSts 7;
BA_ "FlexKomSigLaenge" SG_ 770 AutoParkSts 64;
BA_ "FlexKomSigName" SG_ 770 AutoParkSts "EPB_1";
BA_ "FlexKomComment" SG_ 770 AutoParkSts "EPB_1 message packet";
BA_ "FlexKomIsMotorola" SG_ 770 AutoParkSts 1;
BA_ "GenSigSNA" SG_ 770 AutoParkSts "3h";
BA_ "GenSigCycleTime" SG_ 770 EPBChimeReq 100;
BA_ "FlexKomSigStartValue" SG_ 770 EPBChimeReq "00000000000000FFh";
BA_ "FlexKomSID" SG_ 770 EPBChimeReq 2083;
BA_ "FlexKomSigStartPos" SG_ 770 EPBChimeReq 7;
BA_ "FlexKomSigLaenge" SG_ 770 EPBChimeReq 64;
BA_ "FlexKomSigName" SG_ 770 EPBChimeReq "EPB_1";
BA_ "FlexKomComment" SG_ 770 EPBChimeReq "EPB_1 message packet";
BA_ "FlexKomIsMotorola" SG_ 770 EPBChimeReq 1;
BA_ "GenSigSNA" SG_ 770 EPBChimeReq "7h";
BA_ "GenSigCycleTime" SG_ 770 ServiceModeSts 100;
BA_ "FlexKomSigStartValue" SG_ 770 ServiceModeSts "00000000000000FFh";
BA_ "FlexKomSID" SG_ 770 ServiceModeSts 2083;
BA_ "FlexKomSigStartPos" SG_ 770 ServiceModeSts 7;
BA_ "FlexKomSigLaenge" SG_ 770 ServiceModeSts 64;
BA_ "FlexKomSigName" SG_ 770 ServiceModeSts "EPB_1";
BA_ "FlexKomComment" SG_ 770 ServiceModeSts "EPB_1 message packet";
BA_ "FlexKomIsMotorola" SG_ 770 ServiceModeSts 1;
BA_ "GenSigSNA" SG_ 770 ServiceModeSts "0h";
BA_ "GenSigCycleTime" SG_ 770 TextDisplay 100;
BA_ "FlexKomSigStartValue" SG_ 770 TextDisplay "00000000000000FFh";
BA_ "FlexKomSID" SG_ 770 TextDisplay 2083;
BA_ "FlexKomSigStartPos" SG_ 770 TextDisplay 7;
BA_ "FlexKomSigLaenge" SG_ 770 TextDisplay 64;
BA_ "FlexKomSigName" SG_ 770 TextDisplay "EPB_1";
BA_ "FlexKomComment" SG_ 770 TextDisplay "EPB_1 message packet";
BA_ "FlexKomIsMotorola" SG_ 770 TextDisplay 1;
BA_ "GenSigSNA" SG_ 770 TextDisplay "1Fh";
BA_ "GenSigCycleTime" SG_ 770 ValidEPBSWPos 100;
BA_ "FlexKomSigStartValue" SG_ 770 ValidEPBSWPos "00000000000000FFh";
BA_ "FlexKomSID" SG_ 770 ValidEPBSWPos 2083;
BA_ "FlexKomSigStartPos" SG_ 770 ValidEPBSWPos 7;
BA_ "FlexKomSigLaenge" SG_ 770 ValidEPBSWPos 64;
BA_ "FlexKomSigName" SG_ 770 ValidEPBSWPos "EPB_1";
BA_ "FlexKomComment" SG_ 770 ValidEPBSWPos "EPB_1 message packet";
BA_ "FlexKomIsMotorola" SG_ 770 ValidEPBSWPos 1;
BA_ "GenSigSNA" SG_ 770 ValidEPBSWPos "0h";
BA_ "GenSigCycleTime" SG_ 770 EnableDecelerationReq 100;
BA_ "FlexKomSigStartValue" SG_ 770 EnableDecelerationReq "00000000000000FFh";
BA_ "FlexKomSID" SG_ 770 EnableDecelerationReq 2083;
BA_ "FlexKomSigStartPos" SG_ 770 EnableDecelerationReq 7;
BA_ "FlexKomSigLaenge" SG_ 770 EnableDecelerationReq 64;
BA_ "FlexKomSigName" SG_ 770 EnableDecelerationReq "EPB_1";
BA_ "FlexKomComment" SG_ 770 EnableDecelerationReq "EPB_1 message packet";
BA_ "FlexKomIsMotorola" SG_ 770 EnableDecelerationReq 1;
BA_ "GenSigSNA" SG_ 770 EnableDecelerationReq "0h";
BA_ "GenSigCycleTime" SG_ 770 FunctionLamp 100;
BA_ "FlexKomSigStartValue" SG_ 770 FunctionLamp "00000000000000FFh";
BA_ "FlexKomSID" SG_ 770 FunctionLamp 2083;
BA_ "FlexKomSigStartPos" SG_ 770 FunctionLamp 7;
BA_ "FlexKomSigLaenge" SG_ 770 FunctionLamp 64;
BA_ "FlexKomSigName" SG_ 770 FunctionLamp "EPB_1";
BA_ "FlexKomComment" SG_ 770 FunctionLamp "EPB_1 message packet";
BA_ "FlexKomIsMotorola" SG_ 770 FunctionLamp 1;
BA_ "GenSigSNA" SG_ 770 FunctionLamp "3h";
BA_ "GenSigCycleTime" SG_ 770 EPBWarningLampReq 100;
BA_ "FlexKomSigStartValue" SG_ 770 EPBWarningLampReq "00000000000000FFh";
BA_ "GenSigTimeout_ORC" SG_ 770 EPBWarningLampReq 350;
BA_ "FlexKomSID" SG_ 770 EPBWarningLampReq 2083;
BA_ "FlexKomSigStartPos" SG_ 770 EPBWarningLampReq 7;
BA_ "FlexKomSigLaenge" SG_ 770 EPBWarningLampReq 64;
BA_ "FlexKomSigName" SG_ 770 EPBWarningLampReq "EPB_1";
BA_ "FlexKomComment" SG_ 770 EPBWarningLampReq "EPB_1 message packet";
BA_ "FlexKomIsMotorola" SG_ 770 EPBWarningLampReq 1;
BA_ "GenSigSNA" SG_ 770 EPBWarningLampReq "3h";
BA_ "GenSigCycleTime" SG_ 770 MC_EPB_1 100;
BA_ "FlexKomSigStartValue" SG_ 770 MC_EPB_1 "00000000000000FFh";
BA_ "FlexKomSID" SG_ 770 MC_EPB_1 2083;
BA_ "FlexKomSigStartPos" SG_ 770 MC_EPB_1 7;
BA_ "FlexKomSigLaenge" SG_ 770 MC_EPB_1 64;
BA_ "FlexKomSigName" SG_ 770 MC_EPB_1 "EPB_1";
BA_ "FlexKomComment" SG_ 770 MC_EPB_1 "EPB_1 message packet";
BA_ "FlexKomIsMotorola" SG_ 770 MC_EPB_1 1;
BA_ "GenSigSNA" SG_ 770 MC_EPB_1 "0h";
BA_ "GenSigCycleTime" SG_ 770 CRC_EPB_1 100;
BA_ "FlexKomSigStartValue" SG_ 770 CRC_EPB_1 "00000000000000FFh";
BA_ "GenSigStartValue" SG_ 770 CRC_EPB_1 255;
BA_ "FlexKomSID" SG_ 770 CRC_EPB_1 2083;
BA_ "FlexKomSigStartPos" SG_ 770 CRC_EPB_1 7;
BA_ "FlexKomSigLaenge" SG_ 770 CRC_EPB_1 64;
BA_ "FlexKomSigName" SG_ 770 CRC_EPB_1 "EPB_1";
BA_ "FlexKomComment" SG_ 770 CRC_EPB_1 "EPB_1 message packet";
BA_ "FlexKomIsMotorola" SG_ 770 CRC_EPB_1 1;
BA_ "GenSigSNA" SG_ 770 CRC_EPB_1 "FFh";
BA_ "GenSigCycleTime" SG_ 772 TPM_IndLmp_On_Rq 1000;
BA_ "FlexKomSigStartValue" SG_ 772 TPM_IndLmp_On_Rq "000000FFFFFFFFFFh";
BA_ "GenSigTimeout_IC" SG_ 772 TPM_IndLmp_On_Rq 5500;
BA_ "GenSigTimeout_ORC" SG_ 772 TPM_IndLmp_On_Rq 3500;
BA_ "GenSigTimeout_ETM" SG_ 772 TPM_IndLmp_On_Rq 10500;
BA_ "FlexKomSID" SG_ 772 TPM_IndLmp_On_Rq 866;
BA_ "FlexKomSigStartPos" SG_ 772 TPM_IndLmp_On_Rq 7;
BA_ "FlexKomSigLaenge" SG_ 772 TPM_IndLmp_On_Rq 64;
BA_ "FlexKomSigName" SG_ 772 TPM_IndLmp_On_Rq "TPM_A1_PKT";
BA_ "FlexKomComment" SG_ 772 TPM_IndLmp_On_Rq "Tire Pressure Packet";
BA_ "FlexKomIsMotorola" SG_ 772 TPM_IndLmp_On_Rq 1;
BA_ "GenSigSNA" SG_ 772 TPM_IndLmp_On_Rq "3h";
BA_ "GenSigCycleTime" SG_ 772 TPM_Chime_Rq 1000;
BA_ "FlexKomSigStartValue" SG_ 772 TPM_Chime_Rq "000000FFFFFFFFFFh";
BA_ "GenSigTimeout_IC" SG_ 772 TPM_Chime_Rq 10500;
BA_ "GenSigTimeout_ORC" SG_ 772 TPM_Chime_Rq 3500;
BA_ "FlexKomSID" SG_ 772 TPM_Chime_Rq 866;
BA_ "FlexKomSigStartPos" SG_ 772 TPM_Chime_Rq 7;
BA_ "FlexKomSigLaenge" SG_ 772 TPM_Chime_Rq 64;
BA_ "FlexKomSigName" SG_ 772 TPM_Chime_Rq "TPM_A1_PKT";
BA_ "FlexKomComment" SG_ 772 TPM_Chime_Rq "Tire Pressure Packet";
BA_ "FlexKomIsMotorola" SG_ 772 TPM_Chime_Rq 1;
BA_ "GenSigSNA" SG_ 772 TPM_Chime_Rq "0h";
BA_ "GenSigCycleTime" SG_ 772 TPM_SwIndRq 1000;
BA_ "FlexKomSigStartValue" SG_ 772 TPM_SwIndRq "000000FFFFFFFFFFh";
BA_ "GenSigTimeout_CBC" SG_ 772 TPM_SwIndRq 10500;
BA_ "GenSigTimeout_IC" SG_ 772 TPM_SwIndRq 10500;
BA_ "GenSigTimeout_ORC" SG_ 772 TPM_SwIndRq 3500;
BA_ "FlexKomSID" SG_ 772 TPM_SwIndRq 866;
BA_ "FlexKomSigStartPos" SG_ 772 TPM_SwIndRq 7;
BA_ "FlexKomSigLaenge" SG_ 772 TPM_SwIndRq 64;
BA_ "FlexKomSigName" SG_ 772 TPM_SwIndRq "TPM_A1_PKT";
BA_ "FlexKomComment" SG_ 772 TPM_SwIndRq "Tire Pressure Packet";
BA_ "FlexKomIsMotorola" SG_ 772 TPM_SwIndRq 1;
BA_ "GenSigSNA" SG_ 772 TPM_SwIndRq "3h";
BA_ "GenSigCycleTime" SG_ 772 TPM_Sys_Stat 1000;
BA_ "FlexKomSigStartValue" SG_ 772 TPM_Sys_Stat "000000FFFFFFFFFFh";
BA_ "GenSigTimeout_IC" SG_ 772 TPM_Sys_Stat 10500;
BA_ "GenSigTimeout_ORC" SG_ 772 TPM_Sys_Stat 3500;
BA_ "FlexKomSID" SG_ 772 TPM_Sys_Stat 866;
BA_ "FlexKomSigStartPos" SG_ 772 TPM_Sys_Stat 7;
BA_ "FlexKomSigLaenge" SG_ 772 TPM_Sys_Stat 64;
BA_ "FlexKomSigName" SG_ 772 TPM_Sys_Stat "TPM_A1_PKT";
BA_ "FlexKomComment" SG_ 772 TPM_Sys_Stat "Tire Pressure Packet";
BA_ "FlexKomIsMotorola" SG_ 772 TPM_Sys_Stat 1;
BA_ "GenSigSNA" SG_ 772 TPM_Sys_Stat "7h";
BA_ "GenSigCycleTime" SG_ 772 TireFL 1000;
BA_ "FlexKomSigStartValue" SG_ 772 TireFL "000000FFFFFFFFFFh";
BA_ "GenSigTimeout_IC" SG_ 772 TireFL 10500;
BA_ "GenSigTimeout_ORC" SG_ 772 TireFL 3500;
BA_ "GenSigTimeout_ETM" SG_ 772 TireFL 10500;
BA_ "FlexKomSID" SG_ 772 TireFL 866;
BA_ "FlexKomSigStartPos" SG_ 772 TireFL 7;
BA_ "FlexKomSigLaenge" SG_ 772 TireFL 64;
BA_ "FlexKomSigName" SG_ 772 TireFL "TPM_A1_PKT";
BA_ "FlexKomComment" SG_ 772 TireFL "Tire Pressure Packet";
BA_ "FlexKomIsMotorola" SG_ 772 TireFL 1;
BA_ "GenSigSNA" SG_ 772 TireFL "3h";
BA_ "GenSigCycleTime" SG_ 772 TireFR 1000;
BA_ "FlexKomSigStartValue" SG_ 772 TireFR "000000FFFFFFFFFFh";
BA_ "GenSigTimeout_IC" SG_ 772 TireFR 10500;
BA_ "GenSigTimeout_ORC" SG_ 772 TireFR 3500;
BA_ "GenSigTimeout_ETM" SG_ 772 TireFR 10500;
BA_ "FlexKomSID" SG_ 772 TireFR 866;
BA_ "FlexKomSigStartPos" SG_ 772 TireFR 7;
BA_ "FlexKomSigLaenge" SG_ 772 TireFR 64;
BA_ "FlexKomSigName" SG_ 772 TireFR "TPM_A1_PKT";
BA_ "FlexKomComment" SG_ 772 TireFR "Tire Pressure Packet";
BA_ "FlexKomIsMotorola" SG_ 772 TireFR 1;
BA_ "GenSigSNA" SG_ 772 TireFR "3h";
BA_ "GenSigCycleTime" SG_ 772 TireRR 1000;
BA_ "FlexKomSigStartValue" SG_ 772 TireRR "000000FFFFFFFFFFh";
BA_ "GenSigTimeout_IC" SG_ 772 TireRR 10500;
BA_ "GenSigTimeout_ORC" SG_ 772 TireRR 3500;
BA_ "GenSigTimeout_ETM" SG_ 772 TireRR 10500;
BA_ "FlexKomSID" SG_ 772 TireRR 866;
BA_ "FlexKomSigStartPos" SG_ 772 TireRR 7;
BA_ "FlexKomSigLaenge" SG_ 772 TireRR 64;
BA_ "FlexKomSigName" SG_ 772 TireRR "TPM_A1_PKT";
BA_ "FlexKomComment" SG_ 772 TireRR "Tire Pressure Packet";
BA_ "FlexKomIsMotorola" SG_ 772 TireRR 1;
BA_ "GenSigSNA" SG_ 772 TireRR "3h";
BA_ "GenSigCycleTime" SG_ 772 TireRL 1000;
BA_ "FlexKomSigStartValue" SG_ 772 TireRL "000000FFFFFFFFFFh";
BA_ "GenSigTimeout_IC" SG_ 772 TireRL 10500;
BA_ "GenSigTimeout_ORC" SG_ 772 TireRL 3500;
BA_ "GenSigTimeout_ETM" SG_ 772 TireRL 10500;
BA_ "FlexKomSID" SG_ 772 TireRL 866;
BA_ "FlexKomSigStartPos" SG_ 772 TireRL 7;
BA_ "FlexKomSigLaenge" SG_ 772 TireRL 64;
BA_ "FlexKomSigName" SG_ 772 TireRL "TPM_A1_PKT";
BA_ "FlexKomComment" SG_ 772 TireRL "Tire Pressure Packet";
BA_ "FlexKomIsMotorola" SG_ 772 TireRL 1;
BA_ "GenSigSNA" SG_ 772 TireRL "3h";
BA_ "GenSigCycleTime" SG_ 772 TireSpr 1000;
BA_ "FlexKomSigStartValue" SG_ 772 TireSpr "000000FFFFFFFFFFh";
BA_ "GenSigTimeout_IC" SG_ 772 TireSpr 10500;
BA_ "GenSigTimeout_ORC" SG_ 772 TireSpr 3500;
BA_ "FlexKomSID" SG_ 772 TireSpr 866;
BA_ "FlexKomSigStartPos" SG_ 772 TireSpr 7;
BA_ "FlexKomSigLaenge" SG_ 772 TireSpr 64;
BA_ "FlexKomSigName" SG_ 772 TireSpr "TPM_A1_PKT";
BA_ "FlexKomComment" SG_ 772 TireSpr "Tire Pressure Packet";
BA_ "FlexKomIsMotorola" SG_ 772 TireSpr 1;
BA_ "GenSigSNA" SG_ 772 TireSpr "3h";
BA_ "GenSigCycleTime" SG_ 772 RunFlatTireLow 1000;
BA_ "FlexKomSigStartValue" SG_ 772 RunFlatTireLow "000000FFFFFFFFFFh";
BA_ "GenSigTimeout_IC" SG_ 772 RunFlatTireLow 10500;
BA_ "GenSigTimeout_ORC" SG_ 772 RunFlatTireLow 3500;
BA_ "FlexKomSID" SG_ 772 RunFlatTireLow 866;
BA_ "FlexKomSigStartPos" SG_ 772 RunFlatTireLow 7;
BA_ "FlexKomSigLaenge" SG_ 772 RunFlatTireLow 64;
BA_ "FlexKomSigName" SG_ 772 RunFlatTireLow "TPM_A1_PKT";
BA_ "FlexKomComment" SG_ 772 RunFlatTireLow "Tire Pressure Packet";
BA_ "FlexKomIsMotorola" SG_ 772 RunFlatTireLow 1;
BA_ "GenSigSNA" SG_ 772 RunFlatTireLow "0h";
BA_ "GenSigCycleTime" SG_ 772 TirePressFL 1000;
BA_ "FlexKomSigStartValue" SG_ 772 TirePressFL "000000FFFFFFFFFFh";
BA_ "GenSigStartValue" SG_ 772 TirePressFL 255;
BA_ "GenSigTimeout_IC" SG_ 772 TirePressFL 10500;
BA_ "GenSigTimeout_ORC" SG_ 772 TirePressFL 3500;
BA_ "FlexKomSID" SG_ 772 TirePressFL 866;
BA_ "FlexKomSigStartPos" SG_ 772 TirePressFL 7;
BA_ "FlexKomSigLaenge" SG_ 772 TirePressFL 64;
BA_ "FlexKomSigName" SG_ 772 TirePressFL "TPM_A1_PKT";
BA_ "FlexKomComment" SG_ 772 TirePressFL "Tire Pressure Packet";
BA_ "FlexKomIsMotorola" SG_ 772 TirePressFL 1;
BA_ "GenSigSNA" SG_ 772 TirePressFL "FFh";
BA_ "GenSigCycleTime" SG_ 772 TirePressFR 1000;
BA_ "FlexKomSigStartValue" SG_ 772 TirePressFR "000000FFFFFFFFFFh";
BA_ "GenSigStartValue" SG_ 772 TirePressFR 255;
BA_ "GenSigTimeout_IC" SG_ 772 TirePressFR 10500;
BA_ "GenSigTimeout_ORC" SG_ 772 TirePressFR 3500;
BA_ "FlexKomSID" SG_ 772 TirePressFR 866;
BA_ "FlexKomSigStartPos" SG_ 772 TirePressFR 7;
BA_ "FlexKomSigLaenge" SG_ 772 TirePressFR 64;
BA_ "FlexKomSigName" SG_ 772 TirePressFR "TPM_A1_PKT";
BA_ "FlexKomComment" SG_ 772 TirePressFR "Tire Pressure Packet";
BA_ "FlexKomIsMotorola" SG_ 772 TirePressFR 1;
BA_ "GenSigSNA" SG_ 772 TirePressFR "FFh";
BA_ "GenSigCycleTime" SG_ 772 TirePressRL 1000;
BA_ "FlexKomSigStartValue" SG_ 772 TirePressRL "000000FFFFFFFFFFh";
BA_ "GenSigStartValue" SG_ 772 TirePressRL 255;
BA_ "GenSigTimeout_IC" SG_ 772 TirePressRL 10500;
BA_ "GenSigTimeout_ORC" SG_ 772 TirePressRL 3500;
BA_ "FlexKomSID" SG_ 772 TirePressRL 866;
BA_ "FlexKomSigStartPos" SG_ 772 TirePressRL 7;
BA_ "FlexKomSigLaenge" SG_ 772 TirePressRL 64;
BA_ "FlexKomSigName" SG_ 772 TirePressRL "TPM_A1_PKT";
BA_ "FlexKomComment" SG_ 772 TirePressRL "Tire Pressure Packet";
BA_ "FlexKomIsMotorola" SG_ 772 TirePressRL 1;
BA_ "GenSigSNA" SG_ 772 TirePressRL "FFh";
BA_ "GenSigCycleTime" SG_ 772 TirePressRR 1000;
BA_ "FlexKomSigStartValue" SG_ 772 TirePressRR "000000FFFFFFFFFFh";
BA_ "GenSigStartValue" SG_ 772 TirePressRR 255;
BA_ "GenSigTimeout_IC" SG_ 772 TirePressRR 10500;
BA_ "GenSigTimeout_ORC" SG_ 772 TirePressRR 3500;
BA_ "FlexKomSID" SG_ 772 TirePressRR 866;
BA_ "FlexKomSigStartPos" SG_ 772 TirePressRR 7;
BA_ "FlexKomSigLaenge" SG_ 772 TirePressRR 64;
BA_ "FlexKomSigName" SG_ 772 TirePressRR "TPM_A1_PKT";
BA_ "FlexKomComment" SG_ 772 TirePressRR "Tire Pressure Packet";
BA_ "FlexKomIsMotorola" SG_ 772 TirePressRR 1;
BA_ "GenSigSNA" SG_ 772 TirePressRR "FFh";
BA_ "GenSigCycleTime" SG_ 772 TirePressSpr 1000;
BA_ "FlexKomSigStartValue" SG_ 772 TirePressSpr "000000FFFFFFFFFFh";
BA_ "GenSigStartValue" SG_ 772 TirePressSpr 255;
BA_ "GenSigTimeout_IC" SG_ 772 TirePressSpr 10500;
BA_ "GenSigTimeout_ORC" SG_ 772 TirePressSpr 3500;
BA_ "FlexKomSID" SG_ 772 TirePressSpr 866;
BA_ "FlexKomSigStartPos" SG_ 772 TirePressSpr 7;
BA_ "FlexKomSigLaenge" SG_ 772 TirePressSpr 64;
BA_ "FlexKomSigName" SG_ 772 TirePressSpr "TPM_A1_PKT";
BA_ "FlexKomComment" SG_ 772 TirePressSpr "Tire Pressure Packet";
BA_ "FlexKomIsMotorola" SG_ 772 TirePressSpr 1;
BA_ "GenSigSNA" SG_ 772 TirePressSpr "FFh";
VAL_ 678 ISO_TelltaleSts 7 "SNA" 4 "YELLOW_F" 3 "YELLOW" 2 "GREEN" 1 "WHITE" 0 "OFF" ;
VAL_ 678 TrqIntensitySts 7 "SNA" 3 "T3" 2 "T2" 1 "T1" 0 "OFF" ;
VAL_ 678 SensitivitySts 7 "SNA" 5 "S5" 4 "S4" 3 "S3" 2 "S2" 1 "S1" 0 "OFF" ;
VAL_ 678 DisplaySts 255 "SNA" 240 "MESS27" 161 "MESS26" 160 "MESS25" 108 "MESS24" 107 "MESS23" 106 "MESS22" 105 "ESS21" 104 "MESS20" 103 "ESS19" 102 "MESS18" 101 "ESS17" 100 "ESS16" 99 "MESS15" 98 "MESS14" 97 "MESS13" 12 "MESS12" 11 "MESS11" 10 "MESS10" 9 "MESS9" 8 "MESS8" 7 "MESS7" 6 "MESS6" 5 "MESS5" 4 "MESS4" 3 "MESS3" 2 "MESS2" 1 "MESS1" 0 "OFF" ;
VAL_ 678 DispPopupSts 255 "SNA" 22 "MESS22" 21 "MESS21" 20 "MESS20" 19 "MESS19" 18 "MESS18" 17 "MESS17" 16 "MESS16" 15 "MESS15" 14 "MESS14" 13 "MESS13" 12 "MESS12" 11 "MESS11" 10 "MESS10" 9 "MESS9" 8 "MESS8" 7 "MESS7" 6 "MESS6" 5 "MESS5" 4 "MESS4" 3 "MESS3" 2 "MESS2" 1 "MESS1" 0 "NONE" ;
VAL_ 678 HALF_CHIME_TYPESts 15 "SNA" 6 "HALF" 0 "NONE" ;
VAL_ 680 EngTrgtSpdCtrl 4095 "SNA" ;
VAL_ 680 EmodeBtnSts 3 "SNA" 2 "BLINK" 1 "CONT" 0 "OFF" ;
VAL_ 680 CurrentGear 15 "SNA" 14 "KRAFTFREI" 13 "P" 12 "R2" 11 "R" 10 "D9" 9 "D2P" 8 "D8" 7 "D7" 6 "D6" 5 "D5" 4 "D4" 3 "D3" 2 "D2" 1 "D1" 0 "N" ;
VAL_ 680 CurrentGearForDisplay 15 "SNA" 14 "R" 13 "N" 12 "P" 9 "D9" 8 "D8" 7 "D7" 6 "D6" 5 "D5" 4 "D4" 3 "D3" 2 "D2" 1 "D1" 0 "Initialize" ;
VAL_ 680 TargetGear 15 "SNA" 14 "ABBRUCH" 13 "P" 12 "R2" 11 "R" 10 "D9" 9 "D2P" 8 "D8" 7 "D7" 6 "D6" 5 "D5" 4 "D4" 3 "D3" 2 "D2" 1 "D1" 0 "N" ;
VAL_ 680 TX_WARN2 255 "SNA" 21 "WARN_21" 20 "WARN_20" 19 "WARN_19" 18 "WARN_18" 17 "WARN_17" 15 "WARN_15" 14 "WARN_14" 13 "WARN_13" 12 "WARN_12" 11 "WARN_11" 10 "WARN_10" 9 "WARN_9" 8 "WARN_8" 7 "WARN_7" 6 "WARN_6" 5 "WARN_5" 4 "WARN_4" 3 "WARN_3" 2 "WARN_2" 1 "WARN_1" 0 "None" ;
VAL_ 683 Pitch_Angle 255 "SNA" ;
VAL_ 683 Roll_Angle 255 "SNA" ;
VAL_ 685 Cfg_Aux_PTO 7 "SNA" 5 "FIVE" 4 "FOUR" 0 "NONE" ;
VAL_ 687 SelTrlrNum 7 "SNA" 4 "T4" 3 "T3" 2 "T2" 1 "T1" 0 "NONE" ;
VAL_ 687 SelTrlrStyle 31 "SNA" 15 "FIFTH" 14 "UTILITY" 13 "TRAVEL" 12 "SNOWMOBILE" 11 "MOTORCYCLE" 10 "JETSKI" 9 "LIVESTOCK" 8 "GOOSE" 7 "FLAT" 6 "EQUIPMENT" 5 "DUMP" 4 "CARGO" 3 "CAR" 2 "BOAT" 1 "TRAILER" 0 "NONE" ;
VAL_ 687 TrlrTripDist 16777215 "SNA" ;
VAL_ 687 TrlrStyle_1 31 "SNA" 15 "FIFTH" 14 "UTILITY" 13 "TRAVEL" 12 "SNOWMOBILE" 11 "MOTORCYCLE" 10 "JETSKI" 9 "LIVESTOCK" 8 "GOOSE" 7 "FLAT" 6 "EQUIPMENT" 5 "DUMP" 4 "CARGO" 3 "CAR" 2 "BOAT" 1 "TRAILER" 0 "NONE" ;
VAL_ 687 TrlrStyle_2 31 "SNA" 15 "FIFTH" 14 "UTILITY" 13 "TRAVEL" 12 "SNOWMOBILE" 11 "MOTORCYCLE" 10 "JETSKI" 9 "LIVESTOCK" 8 "GOOSE" 7 "FLAT" 6 "EQUIPMENT" 5 "DUMP" 4 "CARGO" 3 "CAR" 2 "BOAT" 1 "TRAILER" 0 "NONE" ;
VAL_ 687 TrlrStyle_3 31 "SNA" 15 "FIFTH" 14 "UTILITY" 13 "TRAVEL" 12 "SNOWMOBILE" 11 "MOTORCYCLE" 10 "JETSKI" 9 "LIVESTOCK" 8 "GOOSE" 7 "FLAT" 6 "EQUIPMENT" 5 "DUMP" 4 "CARGO" 3 "CAR" 2 "BOAT" 1 "TRAILER" 0 "NONE" ;
VAL_ 687 TrlrStyle_4 31 "SNA" 15 "FIFTH" 14 "UTILITY" 13 "TRAVEL" 12 "SNOWMOBILE" 11 "MOTORCYCLE" 10 "JETSKI" 9 "LIVESTOCK" 8 "GOOSE" 7 "FLAT" 6 "EQUIPMENT" 5 "DUMP" 4 "CARGO" 3 "CAR" 2 "BOAT" 1 "TRAILER" 0 "NONE" ;
VAL_ 688 EPPM_Stat 3 "SNA" 1 "DEPLOYED" 0 "OK" ;
VAL_ 698 UConnReq 31 "SNA" 20 "GLBL_WIN_UP_RQ" 19 "AirSuspCancel" 18 "AirSuspReq" 17 "ExtLightReq" 16 "PASSENGER_TOGGLE_REQUEST" 15 "DRIVER_TOGGLE_REQUEST" 14 "PANIC_TOGGLE_REQUEST" 13 "CLOSE_CONVERTIBLE_TOP" 12 "OPEN_CONVERTIBLE_TOP" 11 "GLOBAL_WINDOW_DOWN_REQUEST" 10 "REMOTE_START_OFF" 9 "REMOTE_START_ON" 8 "FLIPPER_GLASS_REQUEST" 7 "RIGHT_SLIDER_TOGGLE_REQUEST" 6 "LEFT_SLIDER_TOGGLE_REQUEST" 5 "TRUNK_PLG_TOGGLE_REQUEST" 4 "ALL_UNLOCK_REQUEST" 3 "DRIVER_UNLOCK_REQUEST" 2 "RELOCK_REQUEST" 1 "LOCK_REQUEST" 0 "NO_BASIC_REQUEST" ;
VAL_ 698 UConnReqAuthCode 65535 "SNA" ;
VAL_ 698 UConnReqFOBNum 15 "SNA" 8 "FOB_8" 7 "FOB_7" 6 "FOB_6" 5 "FOB_5" 4 "FOB_4" 3 "FOB_3" 2 "FOB_2" 1 "FOB_1" 0 "FOB_DEFAULT" ;
VAL_ 706 EC_ECUCfg15_Stat 3 "SNA" 2 "REQUEST_DATA" 1 "PROGAMMED" 0 "NA" ;
VAL_ 707 EC_BU_ECUCfg15_Stat 3 "SNA" 2 "NA1" 1 "PROGAMMED" 0 "NA" ;
VAL_ 719 PTSControlSts 3 "NOT" 2 "REAR" 1 "FRONT" 0 "ACTIVE" ;
VAL_ 719 PTSSysFlt 3 "SYSTEM" 2 "REAR" 1 "FRONT" 0 "FALSE" ;
VAL_ 719 PPPA_ControlSts 3 "SNA" 2 "BLINK" 1 "CONT" 0 "OFF" ;
VAL_ 720 BSM_LT_WRN 7 "SNA" 4 "FM_LED" 2 "RM_LED" 0 "NW" ;
VAL_ 720 BSM_RT_WRN 7 "SNA" 4 "FM_LED" 2 "RM_LED" 0 "NW" ;
VAL_ 720 BSM_ChmRq 3 "FAST_CHM" 2 "SLOW_CHM" 1 "1_CHM" 0 "NO_CHM" ;
VAL_ 720 BSM_CFG_STAT 3 "SNA" 2 "ENB_LED_CHM" 1 "ENB_LED" 0 "NT_ENB" ;
VAL_ 729 LDW_LEDControlSts 3 "SNA" 2 "BLINK" 1 "CONT" 0 "OFF" ;
VAL_ 729 TorqueIntensitySts 7 "SNA" 2 "T3" 1 "T2" 0 "T1" ;
VAL_ 729 ConfigSts 7 "SNA" 4 "MOST" 3 "MORE" 2 "MID" 1 "LESS" 0 "LEAST" ;
VAL_ 734 RFHM_TXFR_SEL 7 "SNA" 3 "ECHO" 2 "PSWD" 1 "ID" 0 "KEY" ;
VAL_ 735 CBC_TXFR_SEL 7 "SNA" 3 "ECHO" 2 "PSWD" 1 "ID" 0 "KEY" ;
VAL_ 736 LT_DIST 65535 "SNA" ;
VAL_ 736 RT_DIST 65535 "SNA" ;
VAL_ 736 SPCR_Warn_V2 7 "SNA" 6 "LVL6" 5 "LVL5" 4 "LVL4" 3 "LVL3" 2 "LVL2" 1 "LVL1" 0 "NW" ;
VAL_ 736 HILL_DES_STAT 3 "HDC_THRML_DEACT" 2 "HDC_AVL" 1 "HDC_ACT" 0 "HDC_UNAVL" ;
VAL_ 736 ESP_Off_IndLmp_On_Rq 0 "SNA" ;
VAL_ 736 ESP_TRK_MD 0 "SNA" ;
VAL_ 736 ESC_CtrlLmp_Info 3 "SNA" 2 "BLINK" 1 "CONT" 0 "OFF" ;
VAL_ 736 ABS_IndLmp_On_Rq 3 "SNA" 2 "BLINK" 1 "CONT" 0 "OFF" ;
VAL_ 736 BrkIndLmp_On_Rq_ESC 3 "SNA" 2 "BLINK" 1 "CONT" 0 "OFF" ;
VAL_ 736 SelSpdLmp 3 "SNA" 2 "BLINK" 1 "CONT" 0 "OFF" ;
VAL_ 737 VehPerfAccel_X 1023 "SNA" ;
VAL_ 737 ESC_LnchMd 3 "SNA" 2 "CNC" 1 "LAUNCH_ON" 0 "LAUNCH_OFF" ;
VAL_ 737 VehPerfAccel_Y 1023 "SNA" ;
VAL_ 737 LaunchRPMsetting_ESC 31 "SNA" ;
VAL_ 737 BrkWearInd 3 "SNA" 1 "PADS_WORN" 0 "PADS_NOT_WORN" ;
VAL_ 737 ICS_ESC_OFF_LED_hrdbtn_cnrtl 3 "SNA" 2 "BLINK" 1 "CONT" 0 "OFF" ;
VAL_ 737 ESC_OFF_Hrd_Sft_Button_sts 7 "SNA" 3 "OFF" 2 "TRACK" 1 "SPORT" 0 "STREET" ;
VAL_ 737 ESC_LnchAbrtSts 3 "SNA" 2 "AwA" 1 "AwE" 0 "NOT" ;
VAL_ 737 ICS_Launch_HrdBtn_LED_cnrtl 3 "SNA" 2 "BLINK" 1 "CONT" 0 "OFF" ;
VAL_ 737 ESC_LnchMode 7 "SNA" 3 "CNC" 2 "LAUNCH_ACT" 1 "LAUNCH_ON" 0 "LAUNCH_OFF" ;
VAL_ 739 CNG_GaLvl 255 "SNA" ;
VAL_ 739 EngRunFuelTyp 7 "SNA" 6 "IND_CLMP_FLASH" 5 "IND_CLMP_ON" 4 "IND_CLMP_OFF" 3 "IND_GLMP_FLASH" 2 "IND_GLMP_ON" 1 "IND_GLMP_OFF" 0 "IND_GCLMPS_OFF" ;
VAL_ 739 EngCNG_WrnStat 15 "SNA" 5 "CNG_WARN5_ON" 4 "CNG_WARN4_ON" 3 "CNG_WARN3_ON" 2 "CNG_WARN2_ON" 1 "CNG_WARN1_ON" 0 "CNG_WARNS_OFF" ;
VAL_ 739 CNG_FuelUsed 65535 "SNA" ;
VAL_ 739 CNG_DefFuelEcon 255 "SNA" ;
VAL_ 746 DrvRqShftROT 7 "SNA" 5 "FIFTH" 4 "DRIVE" 3 "NEUT" 2 "REV" 1 "PARK" 0 "INIT" ;
VAL_ 746 Manual_Gate_Request 7 "SNA" 4 "BOTH" 3 "MINUS" 2 "PLUS" 0 "Not_Active" ;
VAL_ 752 EASY_EXIT 3 "SNA" 2 "NDEF2" 1 "ON" 0 "OFF" ;
VAL_ 752 MEM_RC_STAT 7 "SNA" 3 "VEH_IN_MOT" 2 "VEH_NOT_PARK" 1 "SB_BUCKLED" 0 "MEM_ENBL" ;
VAL_ 752 MSMD_PDL_LKOUT 7 "SNA" 3 "AP_DSBL" 2 "LKOUT_TX_REV" 1 "LKOUT_CRUISE" 0 "LKOUT_NONE" ;
VAL_ 760 EngTrqTgt_SEM 8191 "SNA" ;
VAL_ 760 EngRdyForESS 0 "SNA" ;
VAL_ 760 EngTrqStatic_SEM 8191 "SNA" ;
VAL_ 760 TRANS_CLU_SLIP_MODE 7 "SNA" 5 "MDS_IDFSO_ACT" 4 "IDFSO_ACTIVE" 3 "AC_EN_DIS_RQ" 2 "IDFSO_RQ" 1 "MDS_RQ" 0 "NORMAL" ;
VAL_ 760 ThrmlMngMd 7 "SNA" 6 "MODE_6" 5 "MODE_5" 4 "MODE_4" 3 "MODE_3" 2 "MODE_2" 1 "MODE_1" 0 "NORMAL" ;
VAL_ 760 EngMaxRPM 255 "SNA" ;
VAL_ 760 ESS_ENG_ST 15 "SNA" 9 "ENS_ST" 8 "ENS_IHB_LATCH" 7 "ENS_DSBL" 6 "ENS_ST_INH" 5 "ENS_ST_PRTCT" 4 "ENS_STOP_PEND" 3 "ENS_RUN" 2 "ENS_RQ_ST" 1 "ENS_STOPPED" ;
VAL_ 761 EngTrqRq 8191 "SNA" ;
VAL_ 761 TrqCtrlModeRq 7 "SNA" 2 "TRQ_DEC_Fast" 1 "TRQ_INC_Fast" 0 "NONE" ;
VAL_ 761 TrnsTrqReqSlow 8191 "SNA" ;
VAL_ 761 TrqCtrlModeReqSlow 3 "SNA" 2 "TRQ_DEC_Slow" 1 "TRQ_INC_Slow" 0 "NONE" ;
VAL_ 761 MaxTrqDes 8191 "SNA" ;
VAL_ 762 DRV_RQ_SHFT 15 "SNA" 12 "NOT_HOME" 8 "SHFT_ERR" 7 "POS_SIX" 6 "POS_FIVE" 5 "POS_FOUR" 4 "POS_THREE" 3 "POS_TWO" 2 "POS_ONE" 1 "POS_ZERO" 0 "INIT" ;
VAL_ 762 DRV_RQ_SHFT_INV 0 "SNA" 15 "INIT" 14 "POS_ZERO" 13 "POS_ONE" 12 "POS_TWO" 11 "POS_THREE" 10 "POS_FOUR" 9 "POS_FIVE" 8 "POS_SIX" 7 "SHFT_ERR" 3 "NOT_HOME" ;
VAL_ 762 DRV_RQ_LKOUT 3 "SNA" 1 "PSD" 0 "NPSD" ;
VAL_ 762 SHFT_RET_FLT 3 "SNA" 2 "FAULT" 1 "NOT_INI" 0 "OK" ;
VAL_ 764 RawPVS1 255 "SNA" ;
VAL_ 764 RawPVS2 255 "SNA" ;
VAL_ 764 RawTPS1 255 "SNA" ;
VAL_ 764 RawTPS2 255 "SNA" ;
VAL_ 764 RelativePdl 255 "SNA" ;
VAL_ 764 RelativeThrt 255 "SNA" ;
VAL_ 764 MAP 255 "SNA" ;
VAL_ 766 VVT_ExhCam1Pos 0 "SNA" ;
VAL_ 766 VVT_ExhCam2Pos 0 "SNA" ;
VAL_ 766 VVT_IntCam1Pos 0 "SNA" ;
VAL_ 766 VVT_IntCam2Pos 0 "SNA" ;
VAL_ 766 GF_Charge 65535 "SNA" ;
VAL_ 766 RelativeThrtPct 255 "SNA" ;
VAL_ 769 EPB_BtnStat 3 "SD_NOT_PSD" 2 "SD_PSD" 1 "PSD" 0 "NOT_PSD" ;
VAL_ 769 SrvLmpRq 3 "SNA" 1 "ON" 0 "OFF" ;
VAL_ 769 WrnLmpRq 3 "SNA" 1 "ON" 0 "OFF" ;
VAL_ 769 EPB_DsblEnbl 2 "DSBL" 1 "ENBL" ;
VAL_ 769 PrkBrkStat 7 "SNA" 4 "MP" 3 "RIP" 2 "AIP" 1 "APPLY" 0 "REL" ;
VAL_ 770 StopLampActive 3 "SNA" 1 "ON" 0 "OFF" ;
VAL_ 770 EPBSwitchPosition 3 "SNA" 2 "APPLY" 1 "RELEASE" 0 "NONE" ;
VAL_ 770 AutoParkSts 3 "SNA" 2 "GRADE" 1 "ON" 0 "OFF" ;
VAL_ 770 EPBChimeReq 7 "SNA" 5 "T5" 4 "T4" 3 "T3" 2 "T2" 1 "T1" 0 "NONE" ;
VAL_ 770 TextDisplay 31 "SNA" 30 "TxtMsg_30" 29 "TxtMsg_29" 28 "TxtMsg_28" 27 "TxtMsg_27" 26 "TxtMsg_26" 25 "TxtMsg_25" 24 "TxtMsg_24" 23 "TxtMsg_23" 22 "TxtMsg_22" 21 "TxtMsg_21" 20 "TxtMsg_20" 19 "TxtMsg_19" 18 "TxtMsg_18" 17 "TxtMsg_17" 16 "TxtMsg_16" 15 "TxtMsg_15" 14 "TxtMsg_14" 13 "TxtMsg_13" 12 "TxtMsg_12" 11 "TxtMsg_11" 10 "TxtMsg_10" 9 "TxtMsg_9" 8 "TxtMsg_8" 7 "TxtMsg_7" 6 "TxtMsg_6" 5 "TxtMsg_5" 4 "TxtMsg_4" 3 "TxtMsg_3" 2 "TxtMsg_2" 1 "TxtMsg_1" 0 "NONE" ;
VAL_ 770 EnableDecelerationReq 3 "ERROR" 0 "OK" ;
VAL_ 770 FunctionLamp 3 "SNA" 2 "BLINK" 1 "CONT" 0 "OFF" ;
VAL_ 770 EPBWarningLampReq 3 "SNA" 2 "BLINK" 1 "CONT" 0 "OFF" ;
VAL_ 772 TPM_IndLmp_On_Rq 3 "SNA" 2 "IND_LMP_FLASH" 1 "IND_LMP_ON" 0 "IND_LMP_OFF" ;
VAL_ 772 TPM_SwIndRq 3 "SNA" 2 "SW_IND_LMP_FLASH" 1 "SW_IND_LMP_ON" 0 "SW_IND_LMP_OFF" ;
VAL_ 772 TPM_Sys_Stat 7 "SNA" 3 "TPM_NA" 2 "LOCALIZATION_CMPLT" 1 "PERF_LOCALIZATION" 0 "NON_LOCALIZED" ;
VAL_ 772 TireFL 3 "SNA" 2 "HIGH" 1 "LOW" 0 "NORMAL" ;
VAL_ 772 TireFR 3 "SNA" 2 "HIGH" 1 "LOW" 0 "NORMAL" ;
VAL_ 772 TireRR 3 "SNA" 2 "HIGH" 1 "LOW" 0 "NORMAL" ;
VAL_ 772 TireRL 3 "SNA" 2 "HIGH" 1 "LOW" 0 "NORMAL" ;
VAL_ 772 TireSpr 3 "SNA" 2 "HIGH" 1 "LOW" 0 "NORMAL" ;
VAL_ 772 TirePressFL 255 "SNA" ;
VAL_ 772 TirePressFR 255 "SNA" ;
VAL_ 772 TirePressRL 255 "SNA" ;
VAL_ 772 TirePressRR 255 "SNA" ;
VAL_ 772 TirePressSpr 255 "SNA" ;
